[part 11 of 22: package /Cluster]
AUTOSAR XML (schema 4-3-0)
package /Cluster  (continued)
  can cluster E3V_K2CANFD: baudrate=500000, protocol-name=CAN, protocol-version=2.0, bus-off-recovery={bor-counter-l-1-to-l-2=1, bor-time-l-1=0.05, bor-time-l-2=0.2}, can-fd-baudrate=500000  (continued)
    can physical channel CHNL: comm-connectors=CN_E3V_K2CANFD  (continued)
      frame TSG_FT_01_XIX_E3V_K2CANFD: id 0x3D0, to SAM, frame-length=8, can-addressing-mode=STANDARD, can-frame-rx-behavior=CAN-FD, can-frame-tx-behavior=CAN-FD
        pdu TSG_FT_01_XIX_E3V_K2CANFD: length=8, minimum-delay=0.02, transmission-mode-true-timing={cyclic-timing={time-offset=0.0, time-period=0.1}, event-controlled-timing={number-of-repetitions=0, repetition-period=0.0}}, unused-bit-pattern=0  # ab MQB 7.05
          signal FT_Tuer_geoeffnet_XIX_TSG_FT_01_XIX_E3V_K2CANFD: start 0, 1 bit, little-endian, data-type-policy=OVERRIDE, i-signal-type=PRIMITIVE, init-value=0, base-type=BT_FT_Tuer_geoeffnet, compu {0=Cx0_geschlossen (CM_FT_Tuer_geoeffnet_Cx0_geschlossen), 1=Cx1_Tuer_offen (CM_FT_Tuer_geoeffnet_Cx1_Tuer_offen)}, range raw 0..1, transfer-property=TRIGGERED-ON-CHANGE-WITHOUT-REPETITION, to SAM(timeout 1 s)  # Zeigt eine geöffnete Tür an
          signal FT_verriegelt_XIX_TSG_FT_01_XIX_E3V_K2CANFD: start 1, 1 bit, little-endian, data-type-policy=OVERRIDE, i-signal-type=PRIMITIVE, init-value=0, base-type=BT_FT_verriegelt, compu {0=Cx0_Init (CM_FT_verriegelt_Cx0_Init), 1=Cx1_verriegelt (CM_FT_verriegelt_Cx1_verriegelt)}, range raw 0..1, transfer-property=TRIGGERED-ON-CHANGE-WITHOUT-REPETITION  # Zeigt eine verriegelte Tür an ( Status wird erst nach vollständiger Schlossansteuerung ausgegeben (<=1,5sek))
          signal FT_gesafet_XIX_TSG_FT_01_XIX_E3V_K2CANFD: start 2, 1 bit, little-endian, data-type-policy=OVERRIDE, i-signal-type=PRIMITIVE, init-value=0, base-type=BT_FT_gesafet, compu {0=Cx0_Init (CM_FT_gesafet_Cx0_Init), 1=Cx1_gesafet (CM_FT_gesafet_Cx1_gesafet)}, range raw 0..1, transfer-property=TRIGGERED-ON-CHANGE-WITHOUT-REPETITION  # Im Zustand Safe wird auch das Signal FT_verriegelt = 1 gesendet
          signal FT_Schluesselschalter_auf_XIX_TSG_FT_01_XIX_E3V_K2CANFD: start 3, 1 bit, little-endian, data-type-policy=OVERRIDE, i-signal-type=PRIMITIVE, init-value=0, base-type=BT_FT_Schluesselschalter_auf, compu {0=Cx0_Init (CM_FT_Schluesselschalter_auf_Cx0_Init), 1=Cx1_Schluesselschalter_auf_betaetigt (CM_FT_Schluesselschalter_auf_Cx1_Schluesselschalter_auf_betaetigt)}, range raw 0..1, transfer-property=TRIGGERED-ON-CHANGE-WITHOUT-REPETITION  # Schlüsselschalter Richtung auf betätigt
          signal FT_Schluesselschalter_zu_XIX_TSG_FT_01_XIX_E3V_K2CANFD: start 4, 1 bit, little-endian, data-type-policy=OVERRIDE, i-signal-type=PRIMITIVE, init-value=0, base-type=BT_FT_Schluesselschalter_zu, compu {1=Cx1_Schluesselschalter_zu_betaetigt (CM_FT_Schluesselschalter_zu_Cx1_Schluesselschalter_zu_betaetigt) (Schluesselschalter zu betaetigt)}, range raw 1, transfer-property=TRIGGERED-ON-CHANGE-WITHOUT-REPETITION
          signal FT_Unlock_Taster_XIX_TSG_FT_01_XIX_E3V_K2CANFD: start 5, 1 bit, little-endian, data-type-policy=OVERRIDE, i-signal-type=PRIMITIVE, init-value=0, base-type=BT_FT_Unlock_Taster, compu {0=Cx0_Init (CM_FT_Unlock_Taster_Cx0_Init), 1=Cx1_Unlock_Taster_betaetigt (CM_FT_Unlock_Taster_Cx1_Unlock_Taster_betaetigt)}, range raw 0..1, transfer-property=TRIGGERED-ON-CHANGE-WITHOUT-REPETITION  # Entriegelungstaster betätigt
          signal FT_Lock_Taster_XIX_TSG_FT_01_XIX_E3V_K2CANFD: start 6, 1 bit, little-endian, data-type-policy=OVERRIDE, i-signal-type=PRIMITIVE, init-value=0, base-type=BT_FT_Lock_Taster, compu {0=Cx0_Init (CM_FT_Lock_Taster_Cx0_Init), 1=Cx1_Lock_Taster_betaetigt (CM_FT_Lock_Taster_Cx1_Lock_Taster_betaetigt)}, range raw 0..1, transfer-property=TRIGGERED-ON-CHANGE-WITHOUT-REPETITION  # Verriegelungstaster betätigt
          signal FT_Sperrklinke_XIX_TSG_FT_01_XIX_E3V_K2CANFD: start 7, 1 bit, little-endian, data-type-policy=OVERRIDE, i-signal-type=PRIMITIVE, init-value=0, base-type=BT_FT_Sperrklinke, compu {0=Cx0_Schloss_in_Vorraste_und_Hauptraste (CM_FT_Sperrklinke_Cx0_Schloss_in_Vorraste_und_Hauptraste), 1=Cx1_Tuer_auf_oder_Tuer_Position_zwischen_Vor_und_Hauptraste (CM_FT_Sperrklinke_Cx1_Tuer_auf_oder_Tuer_Position_zwischen_Vor_und_Hauptraste)}, range raw 0..1, transfer-property=TRIGGERED-ON-CHANGE-WITHOUT-REPETITION  # Vorraste für Schloß zwischen Vor- und Hauptraste Signal kurz auf 1, danach wieder auf 0 wenn Tür in Hauptraste (Tür ist sicher zu wenn Sperrklinke und Türkontakt auf 0 sind)
          signal FT_TAG_betaetigt_XIX_TSG_FT_01_XIX_E3V_K2CANFD: start 8, 1 bit, little-endian, data-type-policy=OVERRIDE, i-signal-type=PRIMITIVE, init-value=0, base-type=BT_FT_TAG_betaetigt, compu {0=Cx0_nicht_betaetigt (CM_FT_TAG_betaetigt_Cx0_nicht_betaetigt), 1=Cx1_betaetigt (CM_FT_TAG_betaetigt_Cx1_betaetigt)}, range raw 0..1, transfer-property=TRIGGERED-ON-CHANGE-WITHOUT-REPETITION  # Türaussengriff wird nicht im MLB-B8 verwendet
          signal FT_TIG_betaetigt_XIX_TSG_FT_01_XIX_E3V_K2CANFD: start 9, 1 bit, little-endian, data-type-policy=OVERRIDE, i-signal-type=PRIMITIVE, init-value=0, base-type=BT_FT_TIG_betaetigt, compu {0=Cx0_nicht_betaetigt (CM_FT_TIG_betaetigt_Cx0_nicht_betaetigt), 1=Cx1_betaetigt (CM_FT_TIG_betaetigt_Cx1_betaetigt)}, range raw 0..1, transfer-property=TRIGGERED-ON-CHANGE-WITHOUT-REPETITION  # Türinnengriff wird nicht im MLB-B8 verwendet
          signal FT_IRUE_Taste_XIX_TSG_FT_01_XIX_E3V_K2CANFD: start 10, 1 bit, little-endian, data-type-policy=OVERRIDE, i-signal-type=PRIMITIVE, init-value=0, base-type=BT_FT_IRUE_Taste, compu {0=Cx0_Init (CM_FT_IRUE_Taste_Cx0_Init), 1=Cx1_IRUE_Taste_betaetigt (CM_FT_IRUE_Taste_Cx1_IRUE_Taste_betaetigt)}, range raw 0..1, transfer-property=TRIGGERED-ON-CHANGE-WITHOUT-REPETITION  # Betätigung IRUE-Taster (Innenraumüberwachung) MQB: Bei Verbau eines einzelnen Taster zur Deaktivierung von IRUE und NGS wird dieses Signal als Deaktivierungsanforderung beider DWA-Alarmquellen gesendet.
          signal FT_HD_Taste_XIX_TSG_FT_01_XIX_E3V_K2CANFD: start 11, 1 bit, little-endian, data-type-policy=OVERRIDE, i-signal-type=PRIMITIVE, init-value=0, base-type=BT_FT_HD_Taste, compu {0=Cx0_nicht_betaetigt (CM_FT_HD_Taste_Cx0_nicht_betaetigt), 1=Cx1_Heckdeckeltaste_betaetigt (CM_FT_HD_Taste_Cx1_Heckdeckeltaste_betaetigt)}, range raw 0..1, transfer-property=TRIGGERED-ON-CHANGE-WITHOUT-REPETITION  # Taste in der Fahrertür zum Öffnen des Heckschlosses
          signal FT_TD_Taste_Fehler_XIX_TSG_FT_01_XIX_E3V_K2CANFD: start 12, 1 bit, little-endian, data-type-policy=OVERRIDE, i-signal-type=PRIMITIVE, init-value=0, base-type=BT_FT_TD_Taste_Fehler, compu {0=Cx0_iO (CM_FT_TD_Taste_Fehler_Cx0_iO), 1=Cx1_defekt (CM_FT_TD_Taste_Fehler_Cx1_defekt)}, range raw 0..1, transfer-property=PENDING  # Fehlerstatus des Tankdeckelentriegelungstasters. Wird bei Drucktankkonzepten vom MSG zusammen mit dem Signal FT_TD_Taste ausgewertet, um Tankbereitschaft herzustellen. Der Fehler beschreibt einen hängenden TD_Taster. Ein Kurzschluss oder Leitungsunterbrechung kann nicht diagnostiziert werden.
          signal FT_TD_Taste_XIX_TSG_FT_01_XIX_E3V_K2CANFD: start 13, 1 bit, little-endian, data-type-policy=OVERRIDE, i-signal-type=PRIMITIVE, init-value=0, base-type=BT_FT_TD_Taste, compu {0=Cx0_Init (CM_FT_TD_Taste_Cx0_Init), 1=Cx1_Tankdeckel_Taster_betaetigt (CM_FT_TD_Taste_Cx1_Tankdeckel_Taster_betaetigt)}, range raw 0..1, transfer-property=TRIGGERED-ON-CHANGE-WITHOUT-REPETITION  # Tankdeckelentriegelungs-Taste betätigt
          signal SSR_Temp_Freigabe_XIX_TSG_FT_01_XIX_E3V_K2CANFD: start 14, 1 bit, little-endian, data-type-policy=OVERRIDE, i-signal-type=PRIMITIVE, init-value=0, base-type=BT_SSR_Temp_Freigabe, compu {0=Cx0_SSR_Deaktiviert (CM_SSR_Temp_Freigabe_Cx0_SSR_Deaktiviert), 1=Cx1_SSR_Freigegeben (CM_SSR_Temp_Freigabe_Cx1_SSR_Freigegeben)}, range raw 0..1, transfer-property=PENDING  # Freigabe des Seitenscheibenrollos. Bit wird für die Deaktivierung des SSR bei Innenraumtemperaturen kleiner -10 Grad verwendet.
          signal FT_Sp_Heizung_Anf_XIX_TSG_FT_01_XIX_E3V_K2CANFD: start 15, 1 bit, little-endian, data-type-policy=OVERRIDE, i-signal-type=PRIMITIVE, init-value=0, base-type=BT_FT_Sp_Heizung_Anf, compu {phys=raw*100 for raw 0..1; unit Unit_PerCent}, range phys 0..100 Unit_PerCent, raw 0..1, unit=Unit_PerCent, transfer-property=PENDING  # Kundenanforderung der Außenspiegelheizung Fahrertür
          signal FT_HD_Taste_2_XIX_TSG_FT_01_XIX_E3V_K2CANFD: start 16, 1 bit, little-endian, data-type-policy=OVERRIDE, i-signal-type=PRIMITIVE, init-value=0, base-type=BT_FT_HD_Taste_2, compu {0=Cx0_Taste_nicht_gedrueckt (CM_FT_HD_Taste_2_Cx0_Taste_nicht_gedrueckt), 1=Cx1_Taste_gedrueckt (CM_FT_HD_Taste_2_Cx1_Taste_gedrueckt)}, range raw 0..1, transfer-property=TRIGGERED-ON-CHANGE-WITHOUT-REPETITION  # 2. HD-Taste im Bedienfeld Funktion: Heckdeckel schließen
          signal FT_Lock_Unlock_Taster_XIX_TSG_FT_01_XIX_E3V_K2CANFD: start 17, 1 bit, little-endian, data-type-policy=OVERRIDE, i-signal-type=PRIMITIVE, init-value=0, base-type=BT_FT_Lock_Unlock_Taster, compu {0=Cx0_nicht_betaetigt (CM_FT_Lock_Unlock_Taster_Cx0_nicht_betaetigt), 1=Cx1_betaetigt (CM_FT_Lock_Unlock_Taster_Cx1_betaetigt)}, range raw 0..1, transfer-property=TRIGGERED-ON-CHANGE-WITHOUT-REPETITION  # ZV Funktion Lock Unlock mit Toggle-Logik
          signal FT_TSG_hinten_verbaut_XIX_TSG_FT_01_XIX_E3V_K2CANFD: start 18, 1 bit, little-endian, data-type-policy=OVERRIDE, i-signal-type=PRIMITIVE, init-value=0, base-type=BT_FT_TSG_hinten_verbaut, compu {0=Cx0_nicht_verbaut (CM_FT_TSG_hinten_verbaut_Cx0_nicht_verbaut) (nicht verbaut), 1=Cx1_verbaut (CM_FT_TSG_hinten_verbaut_Cx1_verbaut)}, range raw 0..1, transfer-property=TRIGGERED-ON-CHANGE-WITHOUT-REPETITION
          signal FT_Sp_Blk_def_XIX_TSG_FT_01_XIX_E3V_K2CANFD: start 19, 1 bit, little-endian, data-type-policy=OVERRIDE, i-signal-type=PRIMITIVE, init-value=0, base-type=BT_FT_Sp_Blk_def, compu {0=Cx0_iO (CM_FT_Sp_Blk_def_Cx0_iO), 1=Cx1_defekt (CM_FT_Sp_Blk_def_Cx1_defekt)}, range raw 0..1, transfer-property=TRIGGERED-ON-CHANGE-WITHOUT-REPETITION, to SAM(timeout 1 s)  # Blinker am Spiegel defekt
          signal FT_FH_S_ManHoch_XIX_TSG_FT_01_XIX_E3V_K2CANFD: start 20, 1 bit, little-endian, data-type-policy=OVERRIDE, i-signal-type=PRIMITIVE, init-value=0, base-type=BT_FT_FH_S_ManHoch, compu {0=Cx0_Init (CM_FT_FH_S_ManHoch_Cx0_Init), 1=Cx1_FH_Schalter_man_hoch_betaetigt (CM_FT_FH_S_ManHoch_Cx1_FH_Schalter_man_hoch_betaetigt)}, range raw 0..1, transfer-property=TRIGGERED-ON-CHANGE-WITHOUT-REPETITION  # FH Schalter manuell hoch gedrückt
          signal FT_FH_S_AutoHoch_XIX_TSG_FT_01_XIX_E3V_K2CANFD: start 21, 1 bit, little-endian, data-type-policy=OVERRIDE, i-signal-type=PRIMITIVE, init-value=0, base-type=BT_FT_FH_S_AutoHoch, compu {0=Cx0_Init (CM_FT_FH_S_AutoHoch_Cx0_Init), 1=Cx1_FH_Schalter_auto_hoch_betaetigt (CM_FT_FH_S_AutoHoch_Cx1_FH_Schalter_auto_hoch_betaetigt)}, range raw 0..1, transfer-property=TRIGGERED-ON-CHANGE-WITHOUT-REPETITION  # FH Schalter automatisch hoch gedrückt
          signal FT_FH_S_ManTief_XIX_TSG_FT_01_XIX_E3V_K2CANFD: start 22, 1 bit, little-endian, data-type-policy=OVERRIDE, i-signal-type=PRIMITIVE, init-value=0, base-type=BT_FT_FH_S_ManTief, compu {0=Cx0_Init (CM_FT_FH_S_ManTief_Cx0_Init), 1=Cx1_FH_Schalter_man_tief_betaetigt (CM_FT_FH_S_ManTief_Cx1_FH_Schalter_man_tief_betaetigt)}, range raw 0..1, transfer-property=TRIGGERED-ON-CHANGE-WITHOUT-REPETITION  # FH Schalter manuell tief gedrückt
          signal FT_FH_S_AutoTief_XIX_TSG_FT_01_XIX_E3V_K2CANFD: start 23, 1 bit, little-endian, data-type-policy=OVERRIDE, i-signal-type=PRIMITIVE, init-value=0, base-type=BT_FT_FH_S_AutoTief, compu {0=Cx0_Init (CM_FT_FH_S_AutoTief_Cx0_Init), 1=Cx1_FH_Schalter_auto_tief_betaetigt (CM_FT_FH_S_AutoTief_Cx1_FH_Schalter_auto_tief_betaetigt)}, range raw 0..1, transfer-property=TRIGGERED-ON-CHANGE-WITHOUT-REPETITION  # FH Schalter automatisch tief gedrückt
          signal FT_FH_Oeffnung_XIX_TSG_FT_01_XIX_E3V_K2CANFD: start 24, 8 bit, little-endian, data-type-policy=OVERRIDE, i-signal-type=PRIMITIVE, init-value=0, base-type=BT_FT_FH_Oeffnung, compu {phys=raw*0.5 for raw 0..200; unit Unit_PerCent}, range phys 0..100 Unit_PerCent, raw 0..200, unit=Unit_PerCent, transfer-property=TRIGGERED-ON-CHANGE-WITHOUT-REPETITION  # Gibt den Fensteröffnungswert in % an.
          signal FT_FH_Bew_hoch_XIX_TSG_FT_01_XIX_E3V_K2CANFD: start 32, 1 bit, little-endian, data-type-policy=OVERRIDE, i-signal-type=PRIMITIVE, init-value=0, base-type=BT_FT_FH_Bew_hoch, compu {0=Cx0_Init (CM_FT_FH_Bew_hoch_Cx0_Init), 1=Cx1_FH_in_Bewegung_hoch (CM_FT_FH_Bew_hoch_Cx1_FH_in_Bewegung_hoch)}, range raw 0..1, transfer-property=TRIGGERED-ON-CHANGE-WITHOUT-REPETITION, to SAM(timeout 1 s)  # Fensterheber in Bewegung Richtung hoch
          signal FT_FH_Bew_tief_XIX_TSG_FT_01_XIX_E3V_K2CANFD: start 33, 1 bit, little-endian, data-type-policy=OVERRIDE, i-signal-type=PRIMITIVE, init-value=0, base-type=BT_FT_FH_Bew_tief, compu {0=Cx0_Init (CM_FT_FH_Bew_tief_Cx0_Init), 1=Cx1_FH_in_Bewegung_tief (CM_FT_FH_Bew_tief_Cx1_FH_in_Bewegung_tief)}, range raw 0..1, transfer-property=TRIGGERED-ON-CHANGE-WITHOUT-REPETITION, to SAM(timeout 1 s)  # Fensterheber in Bewegung Richtung tief
          signal FT_FH_Fang_XIX_TSG_FT_01_XIX_E3V_K2CANFD: start 34, 1 bit, little-endian, data-type-policy=OVERRIDE, i-signal-type=PRIMITIVE, init-value=0, base-type=BT_FT_FH_Fang, compu {0=Cx0_ausserhalb_Fangbereich (CM_FT_FH_Fang_Cx0_ausserhalb_Fangbereich), 1=Cx1_innerhalb_Fangbereich (CM_FT_FH_Fang_Cx1_innerhalb_Fangbereich)}, range raw 0..1, transfer-property=TRIGGERED-ON-CHANGE-WITHOUT-REPETITION  # Fangbereich ist 4mm von oberer Lippendichtung
          signal FT_FH_Block_XIX_TSG_FT_01_XIX_E3V_K2CANFD: start 35, 1 bit, little-endian, data-type-policy=OVERRIDE, i-signal-type=PRIMITIVE, init-value=0, base-type=BT_FT_FH_Block, compu {0=Cx0_Init (CM_FT_FH_Block_Cx0_Init), 1=Cx1_Fenster_Block (CM_FT_FH_Block_Cx1_Fenster_Block)}, range raw 0..1, transfer-property=TRIGGERED-ON-CHANGE-WITHOUT-REPETITION  # Fensterscheibe befindet sich im mechanischen Block (oben oder unten)
          signal FT_FH_Thermo_XIX_TSG_FT_01_XIX_E3V_K2CANFD: start 36, 1 bit, little-endian, data-type-policy=OVERRIDE, i-signal-type=PRIMITIVE, init-value=0, base-type=BT_FT_FH_Thermo, compu {0=Cx0_Init (CM_FT_FH_Thermo_Cx0_Init), 1=Cx1_Thermoschutz_aktiv (CM_FT_FH_Thermo_Cx1_Thermoschutz_aktiv)}, range raw 0..1, transfer-property=TRIGGERED-ON-CHANGE-WITHOUT-REPETITION  # gibt an ob Fensterheber im Thermoschutz ist
          signal FT_UEKB_aktiviert_XIX_TSG_FT_01_XIX_E3V_K2CANFD: start 37, 1 bit, little-endian, data-type-policy=OVERRIDE, i-signal-type=PRIMITIVE, init-value=0, base-type=BT_FT_UEKB_aktiviert, compu {0=Cx0_Init (CM_FT_UEKB_aktiviert_Cx0_Init), 1=Cx1_UEKB_aktiv (CM_FT_UEKB_aktiviert_Cx1_UEKB_aktiv)}, range raw 0..1, transfer-property=TRIGGERED-ON-CHANGE-WITHOUT-REPETITION  # Überschutzbegrenzungskraft bei Reversieren
          signal ASW_HMI_defekt_XIX_TSG_FT_01_XIX_E3V_K2CANFD: start 38, 1 bit, little-endian, data-type-policy=OVERRIDE, i-signal-type=PRIMITIVE, init-value=0, base-type=BT_ASW_HMI_defekt, compu {0=Cx0_iO (CM_ASW_HMI_defekt_Cx0_iO), 1=Cx1_defekt (CM_ASW_HMI_defekt_Cx1_defekt)}, range raw 0..1, transfer-property=PENDING  # HMI Status der Funktion AusstiegsWarnung (ASW). HMI wird durch das TSG angesteuert.
          signal FT_FH_normiert_XIX_TSG_FT_01_XIX_E3V_K2CANFD: start 39, 1 bit, little-endian, data-type-policy=OVERRIDE, i-signal-type=PRIMITIVE, init-value=0, base-type=BT_FT_FH_normiert, compu {0=Cx0_Init (CM_FT_FH_normiert_Cx0_Init), 1=Cx1_Fenster_normiert (CM_FT_FH_normiert_Cx1_Fenster_normiert)}, range raw 0..1, transfer-property=TRIGGERED-ON-CHANGE-WITHOUT-REPETITION  # Die Position der Fensterheberscheibe ist bekannt
          signal FT_Schliesstaster_XIX_TSG_FT_01_XIX_E3V_K2CANFD: start 40, 1 bit, little-endian, data-type-policy=OVERRIDE, i-signal-type=PRIMITIVE, init-value=0, base-type=BT_FT_Schliesstaster, compu {1=Cx1_Schliesstaster_betaetigt (CM_FT_Schliesstaster_Cx1_Schliesstaster_betaetigt)}, range raw 1, transfer-property=TRIGGERED-ON-CHANGE-WITHOUT-REPETITION  # Vorhalt
          signal FT_Zuziehhilfe_aktiv_XIX_TSG_FT_01_XIX_E3V_K2CANFD: start 41, 1 bit, little-endian, data-type-policy=OVERRIDE, i-signal-type=PRIMITIVE, init-value=0, base-type=BT_FT_Zuziehhilfe_aktiv, compu {0=Cx0_Init (CM_FT_Zuziehhilfe_aktiv_Cx0_Init), 1=Cx1_Zuziehilfe_aktiv (CM_FT_Zuziehhilfe_aktiv_Cx1_Zuziehilfe_aktiv)}, range raw 0..1, transfer-property=TRIGGERED-ON-CHANGE-WITHOUT-REPETITION  # Zuziehhilfe aktiv
          signal FT_SP_ausgerastet_XIX_TSG_FT_01_XIX_E3V_K2CANFD: start 42, 1 bit, little-endian, data-type-policy=OVERRIDE, i-signal-type=PRIMITIVE, init-value=0, base-type=BT_FT_SP_ausgerastet, compu {0=Cx0_Init (CM_FT_SP_ausgerastet_Cx0_Init), 1=Cx1_Spiegel_ausgerastet (CM_FT_SP_ausgerastet_Cx1_Spiegel_ausgerastet)}, range raw 0..1, transfer-property=TRIGGERED-ON-CHANGE-WITHOUT-REPETITION  # Spiegel ausgerastet
          signal FT_SP_lr_aktiv_XIX_TSG_FT_01_XIX_E3V_K2CANFD: start 43, 1 bit, little-endian, data-type-policy=OVERRIDE, i-signal-type=PRIMITIVE, init-value=0, base-type=BT_FT_SP_lr_aktiv, compu {0=Cx0_Init (CM_FT_SP_lr_aktiv_Cx0_Init), 1=Cx1_Spiegel_xAchse_aktiv (CM_FT_SP_lr_aktiv_Cx1_Spiegel_xAchse_aktiv)}, range raw 0..1, transfer-property=TRIGGERED-ON-CHANGE-WITHOUT-REPETITION  # Spiegelverstellung in Richtung links/rechts aktiv
          signal FT_SP_ht_aktiv_XIX_TSG_FT_01_XIX_E3V_K2CANFD: start 44, 1 bit, little-endian, data-type-policy=OVERRIDE, i-signal-type=PRIMITIVE, init-value=0, base-type=BT_FT_SP_ht_aktiv, compu {0=Cx0_Init (CM_FT_SP_ht_aktiv_Cx0_Init), 1=Cx1_Spiegel_yAchse_aktiv (CM_FT_SP_ht_aktiv_Cx1_Spiegel_yAchse_aktiv)}, range raw 0..1, transfer-property=TRIGGERED-ON-CHANGE-WITHOUT-REPETITION  # Spiegelverstellung in Richtung hoch/tief aktiv
          signal ASW_wakeup_XIX_TSG_FT_01_XIX_E3V_K2CANFD: start 45, 1 bit, little-endian, data-type-policy=OVERRIDE, i-signal-type=PRIMITIVE, init-value=0, base-type=BT_ASW_wakeup, compu {0=Cx0_Sleep (CM_ASW_wakeup_Cx0_Sleep), 1=Cx1_Wakeup (CM_ASW_wakeup_Cx1_Wakeup)}, range raw 0..1, transfer-property=TRIGGERED-ON-CHANGE-WITHOUT-REPETITION  # Trigger Start Nachlaufzeit t_1 für die Funktion Ausstieswarnung (ASW)
          signal FT_Oben_Block_erw_XIX_TSG_FT_01_XIX_E3V_K2CANFD: start 46, 1 bit, little-endian, data-type-policy=OVERRIDE, i-signal-type=PRIMITIVE, init-value=0, base-type=BT_FT_Oben_Block_erw, compu {0=Cx0_Fensterheber_nicht_in_Blockerwar (CM_FT_Oben_Block_erw_Cx0_Fensterheber_nicht_in_Blockerwar), 1=Cx1_Fensterheber_in_Blockerwartung_o (CM_FT_Oben_Block_erw_Cx1_Fensterheber_in_Blockerwartung_o)}, range raw 0..1, transfer-property=TRIGGERED-ON-CHANGE-WITHOUT-REPETITION, to SAM(timeout 1 s)  # Fensterheber in Blockerwartung oben
          signal FT_Unten_Block_erw_XIX_TSG_FT_01_XIX_E3V_K2CANFD: start 47, 1 bit, little-endian, data-type-policy=OVERRIDE, i-signal-type=PRIMITIVE, init-value=0, base-type=BT_FT_Unten_Block_erw, compu {0=Cx0_Fensterheber_nicht_in_Blockerwar (CM_FT_Unten_Block_erw_Cx0_Fensterheber_nicht_in_Blockerwar), 1=Cx1_Fensterheber_in_Blockerwartung_u (CM_FT_Unten_Block_erw_Cx1_Fensterheber_in_Blockerwartung_u)}, range raw 0..1, transfer-property=TRIGGERED-ON-CHANGE-WITHOUT-REPETITION, to SAM(timeout 1 s)  # Fensterheber in Blockerwartung unten
          signal FT_Kisi_li_aktiv_XIX_TSG_FT_01_XIX_E3V_K2CANFD: start 48, 1 bit, little-endian, data-type-policy=OVERRIDE, i-signal-type=PRIMITIVE, init-value=0, base-type=BT_FT_Kisi_li_aktiv, compu {0=Cx0_inaktiv (CM_FT_Kisi_li_aktiv_Cx0_inaktiv), 1=Cx1_aktiv (CM_FT_Kisi_li_aktiv_Cx1_aktiv)}, range raw 0..1, transfer-property=TRIGGERED-ON-CHANGE-WITHOUT-REPETITION, to SAM(timeout 1 s)  # Aktivierungsstatus der Kindersicherung links
          signal FT_Kisi_re_aktiv_XIX_TSG_FT_01_XIX_E3V_K2CANFD: start 49, 1 bit, little-endian, data-type-policy=OVERRIDE, i-signal-type=PRIMITIVE, init-value=0, base-type=BT_FT_Kisi_re_aktiv, compu {0=Cx0_inaktiv (CM_FT_Kisi_re_aktiv_Cx0_inaktiv), 1=Cx1_aktiv (CM_FT_Kisi_re_aktiv_Cx1_aktiv)}, range raw 0..1, transfer-property=TRIGGERED-ON-CHANGE-WITHOUT-REPETITION, to SAM(timeout 1 s)  # Aktivierungsstatus der Kindersicherung rechts
          signal FT_Kisi_Taster_li_XIX_TSG_FT_01_XIX_E3V_K2CANFD: start 50, 1 bit, little-endian, data-type-policy=OVERRIDE, i-signal-type=PRIMITIVE, init-value=0, base-type=BT_FT_Kisi_Taster_li, compu {0=Cx0_nicht_betaetigt (CM_FT_Kisi_Taster_li_Cx0_nicht_betaetigt), 1=Cx1_betaetigt (CM_FT_Kisi_Taster_li_Cx1_betaetigt)}, range raw 0..1, transfer-property=TRIGGERED-ON-CHANGE-WITHOUT-REPETITION, to SAM(timeout 1 s)  # Linker Kisi Taster betaetigt
          signal FT_Kisi_Taster_re_XIX_TSG_FT_01_XIX_E3V_K2CANFD: start 51, 1 bit, little-endian, data-type-policy=OVERRIDE, i-signal-type=PRIMITIVE, init-value=0, base-type=BT_FT_Kisi_Taster_re, compu {0=Cx0_nicht_betaetigt (CM_FT_Kisi_Taster_re_Cx0_nicht_betaetigt), 1=Cx1_betaetigt (CM_FT_Kisi_Taster_re_Cx1_betaetigt)}, range raw 0..1, transfer-property=TRIGGERED-ON-CHANGE-WITHOUT-REPETITION, to SAM(timeout 1 s)  # Rechter Kisi Taster betaetigt
          signal FT_BFS_Fond_Freigabe_XIX_TSG_FT_01_XIX_E3V_K2CANFD: start 52, 1 bit, little-endian, data-type-policy=OVERRIDE, i-signal-type=PRIMITIVE, init-value=0, base-type=BT_FT_BFS_Fond_Freigabe, compu {0=Cx0_Init (CM_FT_BFS_Fond_Freigabe_Cx0_Init), 1=Cx1_Freigabe_fuer_Fondbedienung_BFS (CM_FT_BFS_Fond_Freigabe_Cx1_Freigabe_fuer_Fondbedienung_BFS)}, range raw 0..1, transfer-property=TRIGGERED-ON-CHANGE-WITHOUT-REPETITION  # Freigabe für Fondverstellung
          signal FT_Kisi_Fehler_XIX_TSG_FT_01_XIX_E3V_K2CANFD: start 53, 1 bit, little-endian, data-type-policy=OVERRIDE, i-signal-type=PRIMITIVE, init-value=0, base-type=BT_FT_Kisi_Fehler, invalid-value=Invalid_FT_Kisi_Fehler_XIX_TSG_FT_01_XIX_E3V_K2CANFD:1, compu {0=Cx0_kein_Fehler (CM_FT_Kisi_Fehler_Cx0_kein_Fehler), 1=Cx1_Fehler (CM_FT_Kisi_Fehler_Cx1_Fehler)}, range raw 0..1, transfer-property=TRIGGERED-ON-CHANGE-WITHOUT-REPETITION  # Fehlerstatus Kindersicherungsfunktion
          signal FT_Daemmglas_XIX_TSG_FT_01_XIX_E3V_K2CANFD: start 54, 1 bit, little-endian, data-type-policy=OVERRIDE, i-signal-type=PRIMITIVE, init-value=0, base-type=BT_FT_Daemmglas, compu {0=Cx0_Normalglas_verbaut (CM_FT_Daemmglas_Cx0_Normalglas_verbaut), 1=Cx1_Daemmglas_verbaut (CM_FT_Daemmglas_Cx1_Daemmglas_verbaut)}, range raw 0..1, transfer-property=TRIGGERED-ON-CHANGE-WITHOUT-REPETITION  # Daemmglas verbaut
          signal FT_SP_Heizung_Status_XIX_TSG_FT_01_XIX_E3V_K2CANFD: start 55, 1 bit, little-endian, data-type-policy=OVERRIDE, i-signal-type=PRIMITIVE, init-value=0, base-type=BT_FT_SP_Heizung_Status, compu {0=Cx0_Init (CM_FT_SP_Heizung_Status_Cx0_Init), 1=Cx1_Status_Spiegelheizung_ein (CM_FT_SP_Heizung_Status_Cx1_Status_Spiegelheizung_ein)}, range raw 0..1, transfer-property=TRIGGERED-ON-CHANGE-WITHOUT-REPETITION  # Status der Spiegelheizung
          signal ASW_Warnung_aktiv_FS_XIX_TSG_FT_01_XIX_E3V_K2CANFD: start 56, 1 bit, little-endian, data-type-policy=OVERRIDE, i-signal-type=PRIMITIVE, init-value=0, base-type=BT_ASW_Warnung_aktiv_FS, compu {0=Cx0_nicht_angefordert (CM_ASW_Warnung_aktiv_FS_Cx0_nicht_angefordert), 1=Cx1_angefordert (CM_ASW_Warnung_aktiv_FS_Cx1_angefordert)}, range raw 0..1, transfer-property=TRIGGERED-ON-CHANGE-WITHOUT-REPETITION, to SAM(timeout 1 s)  # Abschaltung der Ambientefunktion Fahrertür bei aktiver ASW Warnung an der Fahrertür
          signal FT_FH_Pos_oben_XIX_TSG_FT_01_XIX_E3V_K2CANFD: start 57, 1 bit, little-endian, data-type-policy=OVERRIDE, i-signal-type=PRIMITIVE, init-value=0, base-type=BT_FT_FH_Pos_oben, compu {1=Cx1_Scheibe_oben_nach_Absenken_auf_Position (CM_FT_FH_Pos_oben_Cx1_Scheibe_oben_nach_Absenken_auf_Position) (Scheibe oben (nach Absenken auf Position))}, range raw 1, transfer-property=TRIGGERED-ON-CHANGE-WITHOUT-REPETITION
          signal FT_Tuerschloss_defekt_XIX_TSG_FT_01_XIX_E3V_K2CANFD: start 58, 1 bit, little-endian, data-type-policy=OVERRIDE, i-signal-type=PRIMITIVE, init-value=0, base-type=BT_FT_Tuerschloss_defekt, compu {0=Cx0_Tuerschloss_funktionsfaehig (CM_FT_Tuerschloss_defekt_Cx0_Tuerschloss_funktionsfaehig), 1=Cx1_Tuerschloss_defekt (CM_FT_Tuerschloss_defekt_Cx1_Tuerschloss_defekt)}, range raw 0..1, transfer-property=PENDING  # Das Fahrertürschloss ist nicht mehr funktionsfähig.
          signal FT_SWA_Taster_XIX_TSG_FT_01_XIX_E3V_K2CANFD: start 59, 1 bit, little-endian, data-type-policy=OVERRIDE, i-signal-type=PRIMITIVE, init-value=0, base-type=BT_FT_SWA_Taster, compu {0=Cx0_Taster_nicht_betaetigt (CM_FT_SWA_Taster_Cx0_Taster_nicht_betaetigt), 1=Cx1_Taster_betaetigt (CM_FT_SWA_Taster_Cx1_Taster_betaetigt)}, range raw 0..1, transfer-property=TRIGGERED-ON-CHANGE-WITHOUT-REPETITION  # SWA/ASW Taster Fahrertür
          signal SWA_HMI_Diagnose_XIX_TSG_FT_01_XIX_E3V_K2CANFD: start 60, 2 bit, little-endian, data-type-policy=OVERRIDE, i-signal-type=PRIMITIVE, init-value=0, base-type=BT_SWA_HMI_Diagnose, compu {0=Cx0_kein_Fehler_erkannt (CM_SWA_HMI_Diagnose_Cx0_kein_Fehler_erkannt), 1=Cx1_Fehler_Taster_erkannt (CM_SWA_HMI_Diagnose_Cx1_Fehler_Taster_erkannt), 2=Cx2_Fehler_LED_erkannt (CM_SWA_HMI_Diagnose_Cx2_Fehler_LED_erkannt), 3=Cx3_Fehler_LED_und_Taster_erkannt (CM_SWA_HMI_Diagnose_Cx3_Fehler_LED_und_Taster_erkannt)}, range raw 0..3, transfer-property=PENDING  # SWA HMI Diagnose beim TSG
          signal FS_Status_eTAG_XIX_TSG_FT_01_XIX_E3V_K2CANFD: start 62, 2 bit, little-endian, data-type-policy=OVERRIDE, i-signal-type=PRIMITIVE, init-value=0, base-type=BT_FS_Status_eTAG, invalid-value=Invalid_FS_Status_eTAG_XIX_TSG_FT_01_XIX_E3V_K2CANFD:3, compu {0=Cx0_Init (CM_FS_Status_eTAG_Cx0_Init), 1=Cx1_Griff_ausgefahren (CM_FS_Status_eTAG_Cx1_Griff_ausgefahren), 2=Cx2_Griff_eingefahren (CM_FS_Status_eTAG_Cx2_Griff_eingefahren), 3=Cx3_Fehler (CM_FS_Status_eTAG_Cx3_Fehler)}, range raw 0..3, transfer-property=TRIGGERED-ON-CHANGE-WITHOUT-REPETITION  # Status des elektrischen Tueraussengriffes Fahrertuer
      frame TSG_FT_02_XIX_E3V_K2CANFD: id 0x3E5, to SAM, frame-length=8, can-addressing-mode=STANDARD, can-frame-rx-behavior=CAN-FD, can-frame-tx-behavior=CAN-FD
        pdu TSG_FT_02_XIX_E3V_K2CANFD_E2E: length=8, minimum-delay=0.02, transmission-mode-true-timing=event-controlled-timing={number-of-repetitions=0, repetition-period=0.0}, unused-bit-pattern=0  # Fuer die Botschaft ist das Cyclic-Timing 0.1 zu verwenden.
          signal TSG_FT_02_CRC_XIX_TSG_FT_02_XIX_E3V_K2CANFD: start 0, 8 bit, little-endian, data-type-policy=OVERRIDE, i-signal-type=PRIMITIVE, base-type=BT_TSG_FT_02_CRC, compu {phys=raw for raw 0..255}, range phys 0..255, raw 0..255, to SAM(timeout 1 s)  # Für MLB: "Berechnung siehe Lastenheft "Kommunikationsabsicherung für FlexRay und CAN"" Ab MQB und MLBevo: "Berechnung siehe Lastenheft "End-to-End Kommunikationsabsicherung"" Endwerte siehe Begleitdokument "S-PDU Kennungsfolgen"
          signal TSG_FT_02_BZ_XIX_TSG_FT_02_XIX_E3V_K2CANFD: start 8, 4 bit, little-endian, data-type-policy=OVERRIDE, i-signal-type=PRIMITIVE, base-type=BT_TSG_FT_02_BZ, compu {phys=raw for raw 0..15}, range phys 0..15, raw 0..15, to SAM(timeout 1 s)  # 4bit Botschaftszaehler, wird mit jeder Sendebotschaft inkrementiert
          signal FT_Tuer_Status_XIX_TSG_FT_02_XIX_E3V_K2CANFD: start 12, 2 bit, little-endian, data-type-policy=OVERRIDE, i-signal-type=PRIMITIVE, init-value=0, base-type=BT_FT_Tuer_Status, invalid-value=Invalid_FT_Tuer_Status_XIX_TSG_FT_02_XIX_E3V_K2CANFD:3, compu {0=Cx0_Init (CM_FT_Tuer_Status_Cx0_Init), 1=Cx1_Tuer_geschlossen (CM_FT_Tuer_Status_Cx1_Tuer_geschlossen), 2=Cx2_Tuer_offen (CM_FT_Tuer_Status_Cx2_Tuer_offen), 3=Cx3_Fehler (CM_FT_Tuer_Status_Cx3_Fehler)}, range raw 0..3  # Tür geöffnet oder Tür geschlossen
          signal FT_Tuer_Status_QBit_XIX_TSG_FT_02_XIX_E3V_K2CANFD: start 14, 1 bit, little-endian, data-type-policy=OVERRIDE, i-signal-type=PRIMITIVE, base-type=BT_FT_Tuer_Status_QBit, compu {0=Cx0_Status_Tuerkontakt_sicher (CM_FT_Tuer_Status_QBit_Cx0_Status_Tuerkontakt_sicher), 1=Cx1_Status_Tuerkontakt_unsicher (CM_FT_Tuer_Status_QBit_Cx1_Status_Tuerkontakt_unsicher)}, range raw 0..1  # Dieses Bit gibt die Zuverlässigkeit des Türkontakts an. Ein auf dieses Bit folgender Fehlereintrag ist mit dem Sender des Bits abzustimmen (gültig ab PPE).
          signal FT_Lock_Taster_02_XIX_TSG_FT_02_XIX_E3V_K2CANFD: start 15, 1 bit, little-endian, data-type-policy=OVERRIDE, i-signal-type=PRIMITIVE, init-value=0, base-type=BT_FT_Lock_Taster_02, compu {0=Cx0_nicht_betaetigt (CM_FT_Lock_Taster_02_Cx0_nicht_betaetigt), 1=Cx1_betaetigt (CM_FT_Lock_Taster_02_Cx1_betaetigt)}, range raw 0..1  # Lock-Taster betätigt
          signal FT_Schluesselschalter_zu_02_XIX_TSG_FT_02_XIX_E3V_K2CANFD: start 16, 1 bit, little-endian, data-type-policy=OVERRIDE, i-signal-type=PRIMITIVE, init-value=0, base-type=BT_FT_Schluesselschalter_zu_02, compu {0=Cx0_nicht_betaetigt (CM_FT_Schluesselschalter_zu_02_Cx0_nicht_betaetigt), 1=Cx1_betaetigt (CM_FT_Schluesselschalter_zu_02_Cx1_betaetigt)}, range raw 0..1  # Schlüsselschalter für Schließen betätigt
          signal FT_BFS_Tuer_Status_XIX_TSG_FT_02_XIX_E3V_K2CANFD: start 17, 2 bit, little-endian, data-type-policy=OVERRIDE, i-signal-type=PRIMITIVE, init-value=0, base-type=BT_FT_BFS_Tuer_Status, invalid-value=Invalid_FT_BFS_Tuer_Status_XIX_TSG_FT_02_XIX_E3V_K2CANFD:3, compu {0=Cx0_Init (CM_FT_BFS_Tuer_Status_Cx0_Init), 1=Cx1_Tuer_geschlossen (CM_FT_BFS_Tuer_Status_Cx1_Tuer_geschlossen), 2=Cx2_Tuer_offen (CM_FT_BFS_Tuer_Status_Cx2_Tuer_offen), 3=Cx3_Fehler (CM_FT_BFS_Tuer_Status_Cx3_Fehler)}, range raw 0..3  # Gesammelte Türstatusbotschaft
          signal FT_HBFS_Tuer_Status_XIX_TSG_FT_02_XIX_E3V_K2CANFD: start 19, 2 bit, little-endian, data-type-policy=OVERRIDE, i-signal-type=PRIMITIVE, init-value=0, base-type=BT_FT_HBFS_Tuer_Status, invalid-value=Invalid_FT_HBFS_Tuer_Status_XIX_TSG_FT_02_XIX_E3V_K2CANFD:3, compu {0=Cx0_Init (CM_FT_HBFS_Tuer_Status_Cx0_Init), 1=Cx1_Tuer_geschlossen (CM_FT_HBFS_Tuer_Status_Cx1_Tuer_geschlossen), 2=Cx2_Tuer_offen (CM_FT_HBFS_Tuer_Status_Cx2_Tuer_offen), 3=Cx3_Fehler (CM_FT_HBFS_Tuer_Status_Cx3_Fehler)}, range raw 0..3  # Türstatus mit Fehler und Initwert
          signal FT_HFS_Tuer_Status_XIX_TSG_FT_02_XIX_E3V_K2CANFD: start 21, 2 bit, little-endian, data-type-policy=OVERRIDE, i-signal-type=PRIMITIVE, init-value=0, base-type=BT_FT_HFS_Tuer_Status, invalid-value=Invalid_FT_HFS_Tuer_Status_XIX_TSG_FT_02_XIX_E3V_K2CANFD:3, compu {0=Cx0_Init (CM_FT_HFS_Tuer_Status_Cx0_Init), 1=Cx1_Tuer_geschlossen (CM_FT_HFS_Tuer_Status_Cx1_Tuer_geschlossen), 2=Cx2_Tuer_offen (CM_FT_HFS_Tuer_Status_Cx2_Tuer_offen), 3=Cx3_Fehler (CM_FT_HFS_Tuer_Status_Cx3_Fehler)}, range raw 0..3  # Türstatus mit Fehler und Initwert
          signal FT_Tueroeffnen_Warnung_XIX_TSG_FT_02_XIX_E3V_K2CANFD: start 23, 1 bit, little-endian, data-type-policy=OVERRIDE, i-signal-type=PRIMITIVE, init-value=0, base-type=BT_FT_Tueroeffnen_Warnung, compu {0=Cx0_Tuerwarnung_nicht_aktiv (CM_FT_Tueroeffnen_Warnung_Cx0_Tuerwarnung_nicht_aktiv), 1=Cx1_Tuerwarnung_aktiv (CM_FT_Tueroeffnen_Warnung_Cx1_Tuerwarnung_aktiv)}, range raw 0..1  # Bit wird gesetzt, wenn Tür während der Fahrt geoeffnet werden soll.
          signal FT_SP_Heizung_ein_XIX_TSG_FT_02_XIX_E3V_K2CANFD: start 24, 1 bit, little-endian, data-type-policy=OVERRIDE, i-signal-type=PRIMITIVE, init-value=0, base-type=BT_FT_SP_Heizung_ein, compu {0=Cx0_Aus (CM_FT_SP_Heizung_ein_Cx0_Aus), 1=Cx1_Ein (CM_FT_SP_Heizung_ein_Cx1_Ein)}, range raw 0..1  # Dieses Signal zeigt die tatsächliche Ansteuerung der Spiegelheizung incl. PWM an. Zudem wird aufgrund des Teilnetzbetriebs das Signal zur Ansteuerung der Beifahrer-Spiegelheizung benutzt.
          signal FT_Kisi_Taster_li_02_XIX_TSG_FT_02_XIX_E3V_K2CANFD: start 25, 1 bit, little-endian, data-type-policy=OVERRIDE, i-signal-type=PRIMITIVE, init-value=0, base-type=BT_FT_Kisi_Taster_li_02, compu {0=Cx0_nicht_betaetigt (CM_FT_Kisi_Taster_li_02_Cx0_nicht_betaetigt), 1=Cx1_betaetigt (CM_FT_Kisi_Taster_li_02_Cx1_betaetigt)}, range raw 0..1, to SAM(timeout 1 s)  # Der Kindersicherungstaster hinten links aktiv.
          signal FT_Kisi_Taster_re_02_XIX_TSG_FT_02_XIX_E3V_K2CANFD: start 26, 1 bit, little-endian, data-type-policy=OVERRIDE, i-signal-type=PRIMITIVE, init-value=0, base-type=BT_FT_Kisi_Taster_re_02, compu {0=Cx0_nicht_betaetigt (CM_FT_Kisi_Taster_re_02_Cx0_nicht_betaetigt), 1=Cx1_betaetigt (CM_FT_Kisi_Taster_re_02_Cx1_betaetigt)}, range raw 0..1, to SAM(timeout 1 s)  # Der Kindersicherungstaster hinten rechts aktiv.
          signal FT_TD_Taste_Status_XIX_TSG_FT_02_XIX_E3V_K2CANFD: start 27, 2 bit, little-endian, data-type-policy=OVERRIDE, i-signal-type=PRIMITIVE, init-value=0, base-type=BT_FT_TD_Taste_Status, compu {0=Cx0_kein_Fehler (CM_FT_TD_Taste_Status_Cx0_kein_Fehler), 1=Cx1_Kurzschluss_nach_Minus (CM_FT_TD_Taste_Status_Cx1_Kurzschluss_nach_Minus), 2=Cx2_Kurzschluss_nach_Plus (CM_FT_TD_Taste_Status_Cx2_Kurzschluss_nach_Plus), 3=Cx3_Leitungsunterbrechung (CM_FT_TD_Taste_Status_Cx3_Leitungsunterbrechung)}, range raw 0..3  # Status Taste für Tankdeckel
          signal FT_TCR_Mode_aktiv_XIX_TSG_FT_02_XIX_E3V_K2CANFD: start 29, 1 bit, little-endian, data-type-policy=OVERRIDE, i-signal-type=PRIMITIVE, init-value=0, base-type=BT_FT_TCR_Mode_aktiv, compu {0=Cx0_TCR_Mode_deaktiv (CM_FT_TCR_Mode_aktiv_Cx0_TCR_Mode_deaktiv), 1=Cx1_TCR_Mode_aktiv (CM_FT_TCR_Mode_aktiv_Cx1_TCR_Mode_aktiv)}, range raw 0..1  # Signal zeigt eine aktive mechanische Redundanz am Türschloss an.
          signal TBF_FS_Touch_Event_XIX_TSG_FT_02_XIX_E3V_K2CANFD: start 30, 4 bit, little-endian, data-type-policy=OVERRIDE, i-signal-type=PRIMITIVE, init-value=0, base-type=BT_TBF_FS_Touch_Event, compu {0=Cx0_nicht_betaetigt (CM_TBF_FS_Touch_Event_Cx0_nicht_betaetigt), 1=Cx1_Tippen (CM_TBF_FS_Touch_Event_Cx1_Tippen), 2=Cx2_Wischen (CM_TBF_FS_Touch_Event_Cx2_Wischen), 3=Cx3_Geste (CM_TBF_FS_Touch_Event_Cx3_Geste), 4=Cx4_Doppeltippen (CM_TBF_FS_Touch_Event_Cx4_Doppeltippen), 5=Cx5_Longpress_1 (CM_TBF_FS_Touch_Event_Cx5_Longpress_1), 6=Cx6_Longpress_2 (CM_TBF_FS_Touch_Event_Cx6_Longpress_2), 7=Cx7_reserviert (CM_TBF_FS_Touch_Event_Cx7_reserviert), 8=Cx8_reserviert (CM_TBF_FS_Touch_Event_Cx8_reserviert), 9=Cx9_reserviert (CM_TBF_FS_Touch_Event_Cx9_reserviert), 10=Cxa_reserviert (CM_TBF_FS_Touch_Event_Cxa_reserviert), 11=Cxb_reserviert (CM_TBF_FS_Touch_Event_Cxb_reserviert), 12=Cxc_reserviert (CM_TBF_FS_Touch_Event_Cxc_reserviert), 13=Cxd_reserviert (CM_TBF_FS_Touch_Event_Cxd_reserviert), 14=Cxe_reserviert (CM_TBF_FS_Touch_Event_Cxe_reserviert), 15=Cxf_reserviert (CM_TBF_FS_Touch_Event_Cxf_reserviert)}, range raw 0..15  # Touch_Events für Informationen einer Funktionsauslösung auf dem TBF, welche dann für bspw. ein akustisches Signal zentral umgesetzt werden können.
          signal FT_KiSi_Status_Soll_HBFS_XIX_TSG_FT_02_XIX_E3V_K2CANFD: start 34, 1 bit, little-endian, data-type-policy=OVERRIDE, i-signal-type=PRIMITIVE, base-type=BT_FT_KiSi_Status_Soll_HBFS, compu {0=Cx0_inaktiv (CM_FT_KiSi_Status_Soll_HBFS_Cx0_inaktiv), 1=Cx1_aktiv (CM_FT_KiSi_Status_Soll_HBFS_Cx1_aktiv)}, range raw 0..1  # Soll KiSi Status HBFS
          signal FT_KiSi_Status_Soll_HFS_XIX_TSG_FT_02_XIX_E3V_K2CANFD: start 35, 1 bit, little-endian, data-type-policy=OVERRIDE, i-signal-type=PRIMITIVE, base-type=BT_FT_KiSi_Status_Soll_HFS, compu {0=Cx0_inaktiv (CM_FT_KiSi_Status_Soll_HFS_Cx0_inaktiv), 1=Cx1_aktiv (CM_FT_KiSi_Status_Soll_HFS_Cx1_aktiv)}, range raw 0..1  # Soll Status der KiSi HFS
          signal FS_Push_Tuergriff_XIX_TSG_FT_02_XIX_E3V_K2CANFD: start 36, 1 bit, little-endian, data-type-policy=OVERRIDE, i-signal-type=PRIMITIVE, init-value=0, base-type=BT_FS_Push_Tuergriff, compu {0=Cx0_nicht_erkannt (CM_FS_Push_Tuergriff_Cx0_nicht_erkannt), 1=Cx1_erkannt (CM_FS_Push_Tuergriff_Cx1_erkannt)}, range raw 0..1  # Push zum Ausfahren der Flush-Tuergriffe
          signal TSG_FS_Spiegel_angeklappt_XIX_TSG_FT_02_XIX_E3V_K2CANFD: start 37, 1 bit, little-endian, data-type-policy=OVERRIDE, i-signal-type=PRIMITIVE, init-value=0, base-type=BT_TSG_FS_Spiegel_angeklappt, compu {0=Cx0_Spiegel_ausgeklappt (CM_TSG_FS_Spiegel_angeklappt_Cx0_Spiegel_ausgeklappt), 1=Cx1_Spiegel_eingeklappt (CM_TSG_FS_Spiegel_angeklappt_Cx1_Spiegel_eingeklappt)}, range raw 0..1  # Funktionsrückmeldung TSG_FS über Spiegelstellung angeklappt
          signal FT_Cargolock_bet_XIX_TSG_FT_02_XIX_E3V_K2CANFD: start 38, 1 bit, little-endian, data-type-policy=OVERRIDE, i-signal-type=PRIMITIVE, init-value=0, base-type=BT_FT_Cargolock_bet, compu {0=Cx0_nicht_betaetigt (CM_FT_Cargolock_bet_Cx0_nicht_betaetigt), 1=Cx1_betaetigt (CM_FT_Cargolock_bet_Cx1_betaetigt)}, range raw 0..1  # CargoLock-Taste betätigt
          signal ISignalVoid_TSG_FT_02_XIX_E3V_K2CANFD_0: start 39, 1 bit, little-endian, system signal SignalVoid_TSG_FT_02_0, data-type-policy=OVERRIDE, i-signal-type=PRIMITIVE, base-type=BT_SignalVoid
          signal FT_kisi_asynchron_XIX_TSG_FT_02_XIX_E3V_K2CANFD: start 40, 1 bit, little-endian, data-type-policy=OVERRIDE, i-signal-type=PRIMITIVE, init-value=0, base-type=BT_FT_kisi_asynchron, compu {0=Cx0_nicht_aktiv (CM_FT_kisi_asynchron_Cx0_nicht_aktiv), 1=Cx1_aktiv (CM_FT_kisi_asynchron_Cx1_aktiv)}, range raw 0..1  # Signal erzeugt eine seperate Warnmeldung bei ungewollter Asynchronität der "elektrische Kindersicherung" der Schlösser.
          signal ISignalVoid_TSG_FT_02_XIX_E3V_K2CANFD_1: start 41, 1 bit, little-endian, system signal SignalVoid_TSG_FT_02_1, data-type-policy=OVERRIDE, i-signal-type=PRIMITIVE, base-type=BT_SignalVoid
          signal FS_Status_eTAG_ext_XIX_TSG_FT_02_XIX_E3V_K2CANFD: start 42, 3 bit, little-endian, data-type-policy=OVERRIDE, i-signal-type=PRIMITIVE, init-value=3, base-type=BT_FS_Status_eTAG_ext, invalid-value=Invalid_FS_Status_eTAG_ext_XIX_TSG_FT_02_XIX_E3V_K2CANFD:4, compu {0=Cx0_Griff_eingefahren (CM_FS_Status_eTAG_ext_Cx0_Griff_eingefahren), 1=Cx1_Griff_ausgefahren (CM_FS_Status_eTAG_ext_Cx1_Griff_ausgefahren), 2=Cx2_Griff_verfaehrt (CM_FS_Status_eTAG_ext_Cx2_Griff_verfaehrt), 3=Cx3_init (CM_FS_Status_eTAG_ext_Cx3_init), 4=Cx4_Fehler (CM_FS_Status_eTAG_ext_Cx4_Fehler)}, range raw 0..4  # erweitert um den Wert "verfährt"
          signal FT_ASW_Warnton_XIX_TSG_FT_02_XIX_E3V_K2CANFD: start 45, 2 bit, little-endian, data-type-policy=OVERRIDE, i-signal-type=PRIMITIVE, init-value=0, base-type=BT_FT_ASW_Warnton, invalid-value=Invalid_FT_ASW_Warnton_XIX_TSG_FT_02_XIX_E3V_K2CANFD:3, compu {0=Cx0_kein_warnton (CM_FT_ASW_Warnton_Cx0_kein_warnton), 1=Cx1_warnton_links (CM_FT_ASW_Warnton_Cx1_warnton_links), 2=Cx2_warnton_rechts (CM_FT_ASW_Warnton_Cx2_warnton_rechts), 3=Cx3_Fehler (CM_FT_ASW_Warnton_Cx3_Fehler)}, range raw 0..3  # erzeugt ein Warnton bei AS Warnung
          signal SSA_FT_ASW_Status_XIX_TSG_FT_02_XIX_E3V_K2CANFD: start 47, 2 bit, little-endian, data-type-policy=OVERRIDE, i-signal-type=PRIMITIVE, init-value=0, base-type=BT_SSA_FT_ASW_Status, compu {0=Cx0_Init (CM_SSA_FT_ASW_Status_Cx0_Init), 1=Cx1_InfoStufe_aktiv (CM_SSA_FT_ASW_Status_Cx1_InfoStufe_aktiv), 2=Cx2_Warnstufe_aktiv (CM_SSA_FT_ASW_Status_Cx2_Warnstufe_aktiv)}, range raw 0..2  # SmartSensorActor: Rückmeldung des Status der ASW Anzeige.
          signal ISignalVoid_TSG_FT_02_XIX_E3V_K2CANFD_2: start 49, 7 bit, little-endian, system signal SignalVoid_TSG_FT_02_2, data-type-policy=OVERRIDE, i-signal-type=PRIMITIVE, base-type=BT_SignalVoid
          signal ISignalVoid_TSG_FT_02_XIX_E3V_K2CANFD_3: start 56, 8 bit, little-endian, system signal SignalVoid_TSG_FT_02_3, data-type-policy=OVERRIDE, i-signal-type=PRIMITIVE, base-type=BT_SignalVoid
          mapping SG_TSG_FT_02_XIX_E3V_K2CANFD: i-signal-group=SG_TSG_FT_02_XIX_E3V_K2CANFD, transfer-property=TRIGGERED-WITHOUT-REPETITION
      frame TSG_HBFS_01_XIX_E3V_K2CANFD: id 0x3CF, from SAM, to SAM, frame-length=8, can-addressing-mode=STANDARD, can-frame-rx-behavior=CAN-FD, can-frame-tx-behavior=CAN-FD
        pdu TSG_HBFS_01_XIX_E3V_K2CANFD: length=8, minimum-delay=0.02, transmission-mode-true-timing={cyclic-timing={time-offset=0.0, time-period=0.1}, event-controlled-timing={number-of-repetitions=0, repetition-period=0.0}}, unused-bit-pattern=0
          signal HBFS_Tuer_geoeffnet_XIX_TSG_HBFS_01_XIX_E3V_K2CANFD: start 0, 1 bit, little-endian, data-type-policy=OVERRIDE, i-signal-type=PRIMITIVE, init-value=0, base-type=BT_HBFS_Tuer_geoeffnet, compu {0=Cx0_geschlossen (CM_HBFS_Tuer_geoeffnet_Cx0_geschlossen), 1=Cx1_offen (CM_HBFS_Tuer_geoeffnet_Cx1_offen)}, range raw 0..1, transfer-property=TRIGGERED-ON-CHANGE-WITHOUT-REPETITION, to SAM(timeout 1 s)  # HBFS Tuer geoeffnet
          signal HBFS_verriegelt_XIX_TSG_HBFS_01_XIX_E3V_K2CANFD: start 1, 1 bit, little-endian, data-type-policy=OVERRIDE, i-signal-type=PRIMITIVE, init-value=0, base-type=BT_HBFS_verriegelt, compu {0=Cx0_nicht_verriegelt (CM_HBFS_verriegelt_Cx0_nicht_verriegelt), 1=Cx1_verriegelt (CM_HBFS_verriegelt_Cx1_verriegelt)}, range raw 0..1, transfer-property=TRIGGERED-ON-CHANGE-WITHOUT-REPETITION  # Verriegelungsstatus Tür
          signal HBFS_gesafet_XIX_TSG_HBFS_01_XIX_E3V_K2CANFD: start 2, 1 bit, little-endian, data-type-policy=OVERRIDE, i-signal-type=PRIMITIVE, init-value=0, base-type=BT_HBFS_gesafet, compu {0=Cx0_nicht_gesafet (CM_HBFS_gesafet_Cx0_nicht_gesafet), 1=Cx1_gesafet (CM_HBFS_gesafet_Cx1_gesafet)}, range raw 0..1, transfer-property=TRIGGERED-ON-CHANGE-WITHOUT-REPETITION  # HBFS Tuer gesafet. Im Zustand Safe wird auch das Signal HBFS_verriegelt = 1 gesendet.
          signal HBFS_Heckrollotaster_betaetigt_XIX_TSG_HBFS_01_XIX_E3V_K2CANFD: start 3, 1 bit, little-endian, data-type-policy=OVERRIDE, i-signal-type=PRIMITIVE, init-value=0, base-type=BT_HBFS_Heckrollotaster_betaetigt, compu {0=Cx0_keine_Verfahranweisung_in_Richtung_Hoch (CM_HBFS_Heckrollotaster_betaetigt_Cx0_keine_Verfahranweisung_in_Richtung_Hoch), 1=Cx1_In_Richtung_Hoch_Verfahren (CM_HBFS_Heckrollotaster_betaetigt_Cx1_In_Richtung_Hoch_Verfahren)}, range raw 0..1, transfer-property=TRIGGERED-ON-CHANGE-WITHOUT-REPETITION  # Verfahren des Heckrollos in Richtung Hoch Bei Einfachtaster wird Bit als Togglebit verwendet (Heckrollo hoch, tief)
          signal HBFS_Tuerschloss_defekt_XIX_TSG_HBFS_01_XIX_E3V_K2CANFD: start 4, 1 bit, little-endian, data-type-policy=OVERRIDE, i-signal-type=PRIMITIVE, base-type=BT_HBFS_Tuerschloss_defekt, compu {0=Cx0_Tuerschloss_funktionsfaehig (CM_HBFS_Tuerschloss_defekt_Cx0_Tuerschloss_funktionsfaehig), 1=Cx1_Tuerschloss_defekt (CM_HBFS_Tuerschloss_defekt_Cx1_Tuerschloss_defekt)}, range raw 0..1, transfer-property=PENDING  # Das hintere Tuerschloss auf der Beifahrerseite ist nicht mehr funktionsfähig.
          signal HBFS_Unlock_Taster_XIX_TSG_HBFS_01_XIX_E3V_K2CANFD: start 5, 1 bit, little-endian, data-type-policy=OVERRIDE, i-signal-type=PRIMITIVE, init-value=0, base-type=BT_HBFS_Unlock_Taster, compu {0=Cx0_nicht_betaetigt (CM_HBFS_Unlock_Taster_Cx0_nicht_betaetigt), 1=Cx1_betaetigt (CM_HBFS_Unlock_Taster_Cx1_betaetigt)}, range raw 0..1, transfer-property=TRIGGERED-ON-CHANGE-WITHOUT-REPETITION  # Betaetigung Unlock Taster
          signal HBFS_Lock_Taster_XIX_TSG_HBFS_01_XIX_E3V_K2CANFD: start 6, 1 bit, little-endian, data-type-policy=OVERRIDE, i-signal-type=PRIMITIVE, init-value=0, base-type=BT_HBFS_Lock_Taster, compu {0=Cx0_nicht_betaetigt (CM_HBFS_Lock_Taster_Cx0_nicht_betaetigt), 1=Cx1_betaetigt (CM_HBFS_Lock_Taster_Cx1_betaetigt)}, range raw 0..1, transfer-property=TRIGGERED-ON-CHANGE-WITHOUT-REPETITION  # Betaetigung Lock-Taster
          signal HBFS_Sperrklinke_XIX_TSG_HBFS_01_XIX_E3V_K2CANFD: start 7, 1 bit, little-endian, data-type-policy=OVERRIDE, i-signal-type=PRIMITIVE, init-value=0, base-type=BT_HBFS_Sperrklinke, compu {0=Cx0_Schloss_in_Vorraste_und_Hauptraste (CM_HBFS_Sperrklinke_Cx0_Schloss_in_Vorraste_und_Hauptraste), 1=Cx1_Tuer_auf_oder_Tuer_Position_zwischen_Vor_und_Hauptraste (CM_HBFS_Sperrklinke_Cx1_Tuer_auf_oder_Tuer_Position_zwischen_Vor_und_Hauptraste)}, range raw 0..1, transfer-property=TRIGGERED-ON-CHANGE-WITHOUT-REPETITION  # Vorraste für Schloß zwischen Vor- und Hauptraste Signal kurz auf 1, danach wieder auf 0 wenn Tür in Hauptraste (Tür ist sicher zu wenn Sperrklinke und Türkontakt auf 0 sind)
          signal HBFS_TAG_betaetigt_XIX_TSG_HBFS_01_XIX_E3V_K2CANFD: start 8, 1 bit, little-endian, data-type-policy=OVERRIDE, i-signal-type=PRIMITIVE, init-value=0, base-type=BT_HBFS_TAG_betaetigt, compu {0=Cx0_nicht_betaetigt (CM_HBFS_TAG_betaetigt_Cx0_nicht_betaetigt), 1=Cx1_betaetigt (CM_HBFS_TAG_betaetigt_Cx1_betaetigt)}, range raw 0..1, transfer-property=TRIGGERED-ON-CHANGE-WITHOUT-REPETITION  # Betaetigung Türaussengriff
          signal HBFS_TIG_betaetigt_XIX_TSG_HBFS_01_XIX_E3V_K2CANFD: start 9, 1 bit, little-endian, data-type-policy=OVERRIDE, i-signal-type=PRIMITIVE, init-value=0, base-type=BT_HBFS_TIG_betaetigt, compu {0=Cx0_nicht_betaetigt (CM_HBFS_TIG_betaetigt_Cx0_nicht_betaetigt), 1=Cx1_betaetigt (CM_HBFS_TIG_betaetigt_Cx1_betaetigt)}, range raw 0..1, transfer-property=TRIGGERED-ON-CHANGE-WITHOUT-REPETITION, to SAM(timeout 1 s)  # Betaetigung Tuerinnengriff
          signal HBFS_FH_S_HFS_AutoHoch_XIX_TSG_HBFS_01_XIX_E3V_K2CANFD: start 10, 1 bit, little-endian, data-type-policy=OVERRIDE, i-signal-type=PRIMITIVE, init-value=0, base-type=BT_HBFS_FH_S_HFS_AutoHoch, compu {0=Cx0_keine_Bedienung (CM_HBFS_FH_S_HFS_AutoHoch_Cx0_keine_Bedienung), 1=Cx1_Automatiklauf_Angefordert (CM_HBFS_FH_S_HFS_AutoHoch_Cx1_Automatiklauf_Angefordert)}, range raw 0..1, transfer-property=TRIGGERED-ON-CHANGE-WITHOUT-REPETITION  # Automatisches Hochfahren der Seitenscheibe HFS
          signal HBFS_FH_S_HFS_AutoTief_XIX_TSG_HBFS_01_XIX_E3V_K2CANFD: start 11, 1 bit, little-endian, data-type-policy=OVERRIDE, i-signal-type=PRIMITIVE, init-value=0, base-type=BT_HBFS_FH_S_HFS_AutoTief, compu {0=Cx0_keine_Bedienung (CM_HBFS_FH_S_HFS_AutoTief_Cx0_keine_Bedienung), 1=Cx1_Automatiklauf_Angefordert (CM_HBFS_FH_S_HFS_AutoTief_Cx1_Automatiklauf_Angefordert)}, range raw 0..1, transfer-property=TRIGGERED-ON-CHANGE-WITHOUT-REPETITION  # Automatisches Absenken der Seitenscheibe HFS
          signal HBFS_FH_S_HFS_ManHoch_XIX_TSG_HBFS_01_XIX_E3V_K2CANFD: start 12, 1 bit, little-endian, data-type-policy=OVERRIDE, i-signal-type=PRIMITIVE, init-value=0, base-type=BT_HBFS_FH_S_HFS_ManHoch, compu {0=Cx0_keine_Bedienung (CM_HBFS_FH_S_HFS_ManHoch_Cx0_keine_Bedienung), 1=Cx1_Manueller_Lauf_Angefordert (CM_HBFS_FH_S_HFS_ManHoch_Cx1_Manueller_Lauf_Angefordert)}, range raw 0..1, transfer-property=TRIGGERED-ON-CHANGE-WITHOUT-REPETITION  # Manuelles Hochfahren der Seitenscheibe HFS
          signal HBFS_FH_S_HFS_ManTief_XIX_TSG_HBFS_01_XIX_E3V_K2CANFD: start 13, 1 bit, little-endian, data-type-policy=OVERRIDE, i-signal-type=PRIMITIVE, init-value=0, base-type=BT_HBFS_FH_S_HFS_ManTief, compu {0=Cx0_keine_Bedienung (CM_HBFS_FH_S_HFS_ManTief_Cx0_keine_Bedienung), 1=Cx1_Manueller_Lauf_Angefordert (CM_HBFS_FH_S_HFS_ManTief_Cx1_Manueller_Lauf_Angefordert)}, range raw 0..1, transfer-property=TRIGGERED-ON-CHANGE-WITHOUT-REPETITION  # Manuelles Absenken der Seitenscheibe HFS
          signal HBFS_Tuer_Status_XIX_TSG_HBFS_01_XIX_E3V_K2CANFD: start 14, 2 bit, little-endian, data-type-policy=OVERRIDE, i-signal-type=PRIMITIVE, init-value=0, base-type=BT_HBFS_Tuer_Status, invalid-value=Invalid_HBFS_Tuer_Status_XIX_TSG_HBFS_01_XIX_E3V_K2CANFD:3, compu {0=Cx0_Init (CM_HBFS_Tuer_Status_Cx0_Init), 1=Cx1_Tuer_geschlossen (CM_HBFS_Tuer_Status_Cx1_Tuer_geschlossen), 2=Cx2_Tuer_offen (CM_HBFS_Tuer_Status_Cx2_Tuer_offen), 3=Cx3_Fehler (CM_HBFS_Tuer_Status_Cx3_Fehler)}, range raw 0..3, transfer-property=TRIGGERED-ON-CHANGE-WITHOUT-REPETITION  # Türstatus mit Fehler und Initwert
          signal HBFS_SAD_Schalter_XIX_TSG_HBFS_01_XIX_E3V_K2CANFD: start 16, 4 bit, little-endian, data-type-policy=OVERRIDE, i-signal-type=PRIMITIVE, init-value=14, base-type=BT_HBFS_SAD_Schalter, invalid-value=Invalid_HBFS_SAD_Schalter_XIX_TSG_HBFS_01_XIX_E3V_K2CANFD:15, compu {0=Cx0_nicht_betaetigt (CM_HBFS_SAD_Schalter_Cx0_nicht_betaetigt), 5=Cx5_AUF_manuell (CM_HBFS_SAD_Schalter_Cx5_AUF_manuell), 6=Cx6_AUF_automatik (CM_HBFS_SAD_Schalter_Cx6_AUF_automatik), 7=Cx7_ZU_manuell (CM_HBFS_SAD_Schalter_Cx7_ZU_manuell), 8=Cx8_ZU_automatik (CM_HBFS_SAD_Schalter_Cx8_ZU_automatik), 13=Cxd_nicht_verfuegbar (CM_HBFS_SAD_Schalter_Cxd_nicht_verfuegbar), 14=Cxe_Init (CM_HBFS_SAD_Schalter_Cxe_Init), 15=Cxf_Fehler (CM_HBFS_SAD_Schalter_Cxf_Fehler)}, range raw 0..15, transfer-property=TRIGGERED-ON-CHANGE-WITHOUT-REPETITION  # | Ausstelldach MD3 ----------------------------- 0 | nicht_betaetigt 1 | 2 | 3 | 4 | 5 | (m) Auf 6 | (a) Auf 7 | (m) Zu 8 | (a) Zu 13| Schalter nicht verfuegbar 14| Init 15| Fehlerfall
          signal HBFS_FH_S_ManHoch_XIX_TSG_HBFS_01_XIX_E3V_K2CANFD: start 20, 1 bit, little-endian, data-type-policy=OVERRIDE, i-signal-type=PRIMITIVE, init-value=0, base-type=BT_HBFS_FH_S_ManHoch, compu {0=Cx0_nicht_betaetigt (CM_HBFS_FH_S_ManHoch_Cx0_nicht_betaetigt), 1=Cx1_betaetigt (CM_HBFS_FH_S_ManHoch_Cx1_betaetigt)}, range raw 0..1, transfer-property=TRIGGERED-ON-CHANGE-WITHOUT-REPETITION, to SAM(timeout 1 s)  # Betaetigung FH Schalter man hoch
          signal HBFS_FH_S_AutoHoch_XIX_TSG_HBFS_01_XIX_E3V_K2CANFD: start 21, 1 bit, little-endian, data-type-policy=OVERRIDE, i-signal-type=PRIMITIVE, init-value=0, base-type=BT_HBFS_FH_S_AutoHoch, compu {0=Cx0_nicht_betaetigt (CM_HBFS_FH_S_AutoHoch_Cx0_nicht_betaetigt), 1=Cx1_betaetigt (CM_HBFS_FH_S_AutoHoch_Cx1_betaetigt)}, range raw 0..1, transfer-property=TRIGGERED-ON-CHANGE-WITHOUT-REPETITION, to SAM(timeout 1 s)  # Betaetigung FH Schalter auto tief
          signal HBFS_FH_S_ManTief_XIX_TSG_HBFS_01_XIX_E3V_K2CANFD: start 22, 1 bit, little-endian, data-type-policy=OVERRIDE, i-signal-type=PRIMITIVE, init-value=0, base-type=BT_HBFS_FH_S_ManTief, compu {0=Cx0_nicht_betaetigt (CM_HBFS_FH_S_ManTief_Cx0_nicht_betaetigt), 1=Cx1_betaetigt (CM_HBFS_FH_S_ManTief_Cx1_betaetigt)}, range raw 0..1, transfer-property=TRIGGERED-ON-CHANGE-WITHOUT-REPETITION, to SAM(timeout 1 s)  # Betaetigung FH Schalter man tief
          signal HBFS_FH_S_AutoTief_XIX_TSG_HBFS_01_XIX_E3V_K2CANFD: start 23, 1 bit, little-endian, data-type-policy=OVERRIDE, i-signal-type=PRIMITIVE, init-value=0, base-type=BT_HBFS_FH_S_AutoTief, compu {0=Cx0_nicht_betaetigt (CM_HBFS_FH_S_AutoTief_Cx0_nicht_betaetigt), 1=Cx1_betaetigt (CM_HBFS_FH_S_AutoTief_Cx1_betaetigt)}, range raw 0..1, transfer-property=TRIGGERED-ON-CHANGE-WITHOUT-REPETITION, to SAM(timeout 1 s)  # Betaetigung FH Schalter auto hoch
          signal HBFS_FH_Oeffnung_XIX_TSG_HBFS_01_XIX_E3V_K2CANFD: start 24, 8 bit, little-endian, data-type-policy=OVERRIDE, i-signal-type=PRIMITIVE, init-value=0, base-type=BT_HBFS_FH_Oeffnung, compu {phys=raw*0.5 for raw 0..200; unit Unit_PerCent}, range phys 0..100 Unit_PerCent, raw 0..200, unit=Unit_PerCent, transfer-property=TRIGGERED-ON-CHANGE-WITHOUT-REPETITION  # Gibt den Fensteröffnungswert in % an.
          signal HBFS_FH_Bew_hoch_XIX_TSG_HBFS_01_XIX_E3V_K2CANFD: start 32, 1 bit, little-endian, data-type-policy=OVERRIDE, i-signal-type=PRIMITIVE, init-value=0, base-type=BT_HBFS_FH_Bew_hoch, compu {0=Cx0_inaktiv (CM_HBFS_FH_Bew_hoch_Cx0_inaktiv), 1=Cx1_aktiv (CM_HBFS_FH_Bew_hoch_Cx1_aktiv)}, range raw 0..1, transfer-property=TRIGGERED-ON-CHANGE-WITHOUT-REPETITION  # HBFS Fenster bewegt sich in Richtung hoch
          signal HBFS_FH_Bew_tief_XIX_TSG_HBFS_01_XIX_E3V_K2CANFD: start 33, 1 bit, little-endian, data-type-policy=OVERRIDE, i-signal-type=PRIMITIVE, init-value=0, base-type=BT_HBFS_FH_Bew_tief, compu {0=Cx0_inaktiv (CM_HBFS_FH_Bew_tief_Cx0_inaktiv), 1=Cx1_aktiv (CM_HBFS_FH_Bew_tief_Cx1_aktiv)}, range raw 0..1, transfer-property=TRIGGERED-ON-CHANGE-WITHOUT-REPETITION  # HBFS Fenster bewegt sich in Richtung tief
          signal HBFS_FH_Fang_XIX_TSG_HBFS_01_XIX_E3V_K2CANFD: start 34, 1 bit, little-endian, data-type-policy=OVERRIDE, i-signal-type=PRIMITIVE, init-value=0, base-type=BT_HBFS_FH_Fang, compu {0=Cx0_ausserhalb_Fangbereich (CM_HBFS_FH_Fang_Cx0_ausserhalb_Fangbereich), 1=Cx1_innerhalb_Fangbereich (CM_HBFS_FH_Fang_Cx1_innerhalb_Fangbereich)}, range raw 0..1, transfer-property=TRIGGERED-ON-CHANGE-WITHOUT-REPETITION  # Fangbereich ist 4mm von oberer Lippendichtung
          signal HBFS_FH_Block_XIX_TSG_HBFS_01_XIX_E3V_K2CANFD: start 35, 1 bit, little-endian, data-type-policy=OVERRIDE, i-signal-type=PRIMITIVE, init-value=0, base-type=BT_HBFS_FH_Block, compu {0=Cx0_inaktiv (CM_HBFS_FH_Block_Cx0_inaktiv), 1=Cx1_aktiv (CM_HBFS_FH_Block_Cx1_aktiv)}, range raw 0..1, transfer-property=TRIGGERED-ON-CHANGE-WITHOUT-REPETITION  # Fensterscheibe befindet sich im mechanischen Block (oben oder unten)
          signal HBFS_FH_Thermo_XIX_TSG_HBFS_01_XIX_E3V_K2CANFD: start 36, 1 bit, little-endian, data-type-policy=OVERRIDE, i-signal-type=PRIMITIVE, init-value=0, base-type=BT_HBFS_FH_Thermo, compu {0=Cx0_inaktiv (CM_HBFS_FH_Thermo_Cx0_inaktiv), 1=Cx1_aktiv (CM_HBFS_FH_Thermo_Cx1_aktiv)}, range raw 0..1, transfer-property=TRIGGERED-ON-CHANGE-WITHOUT-REPETITION  # gibt an ob Fensterheber im Thermoschutz ist
          signal HBFS_UEKB_aktiviert_XIX_TSG_HBFS_01_XIX_E3V_K2CANFD: start 37, 1 bit, little-endian, data-type-policy=OVERRIDE, i-signal-type=PRIMITIVE, init-value=0, base-type=BT_HBFS_UEKB_aktiviert, compu {0=Cx0_inaktiv (CM_HBFS_UEKB_aktiviert_Cx0_inaktiv), 1=Cx1_aktiv (CM_HBFS_UEKB_aktiviert_Cx1_aktiv)}, range raw 0..1, transfer-property=TRIGGERED-ON-CHANGE-WITHOUT-REPETITION  # Überschutzbegrenzungskraft bei Reversieren
          signal HBFS_Tueroeffnen_Warnung_XIX_TSG_HBFS_01_XIX_E3V_K2CANFD: start 38, 1 bit, little-endian, data-type-policy=OVERRIDE, i-signal-type=PRIMITIVE, init-value=0, base-type=BT_HBFS_Tueroeffnen_Warnung, compu {0=Cx0_Tuerwarnung_nicht_aktiv (CM_HBFS_Tueroeffnen_Warnung_Cx0_Tuerwarnung_nicht_aktiv), 1=Cx1_Tuerwarnung_aktiv (CM_HBFS_Tueroeffnen_Warnung_Cx1_Tuerwarnung_aktiv)}, range raw 0..1, transfer-property=TRIGGERED-ON-CHANGE-WITHOUT-REPETITION  # Bit wird gesetzt, wenn Tür während der Fahrt geoeffnet werden soll.
          signal HBFS_FH_normiert_XIX_TSG_HBFS_01_XIX_E3V_K2CANFD: start 39, 1 bit, little-endian, data-type-policy=OVERRIDE, i-signal-type=PRIMITIVE, init-value=0, base-type=BT_HBFS_FH_normiert, compu {0=Cx0_inaktiv (CM_HBFS_FH_normiert_Cx0_inaktiv), 1=Cx1_aktiv (CM_HBFS_FH_normiert_Cx1_aktiv)}, range raw 0..1, transfer-property=TRIGGERED-ON-CHANGE-WITHOUT-REPETITION  # Die Position der Fensterheberscheibe ist bekannt.
          signal ASW_Warnung_aktiv_HBFS_XIX_TSG_HBFS_01_XIX_E3V_K2CANFD: start 40, 1 bit, little-endian, data-type-policy=OVERRIDE, i-signal-type=PRIMITIVE, init-value=0, base-type=BT_ASW_Warnung_aktiv_HBFS, compu {0=Cx0_nicht_angefordert (CM_ASW_Warnung_aktiv_HBFS_Cx0_nicht_angefordert), 1=Cx1_angefordert (CM_ASW_Warnung_aktiv_HBFS_Cx1_angefordert)}, range raw 0..1, transfer-property=TRIGGERED-ON-CHANGE-WITHOUT-REPETITION, to SAM(timeout 1 s)  # Abschaltung der Ambientefunktion Tür hinten der Beifahrerseite bei aktiver ASW Warnung an der Fahrertür
          signal HBFS_Zuziehhilfe_aktiv_XIX_TSG_HBFS_01_XIX_E3V_K2CANFD: start 41, 1 bit, little-endian, data-type-policy=OVERRIDE, i-signal-type=PRIMITIVE, init-value=0, base-type=BT_HBFS_Zuziehhilfe_aktiv, compu {0=Cx0_Init (CM_HBFS_Zuziehhilfe_aktiv_Cx0_Init), 1=Cx1_Zuziehhilfe_aktiv (CM_HBFS_Zuziehhilfe_aktiv_Cx1_Zuziehhilfe_aktiv)}, range raw 0..1, transfer-property=TRIGGERED-ON-CHANGE-WITHOUT-REPETITION  # Zuziehhilfe aktiv
          signal HBFS_Seitenrollo_hoch_XIX_TSG_HBFS_01_XIX_E3V_K2CANFD: start 42, 1 bit, little-endian, data-type-policy=OVERRIDE, i-signal-type=PRIMITIVE, init-value=0, base-type=BT_HBFS_Seitenrollo_hoch, compu {0=Cx0_Init (CM_HBFS_Seitenrollo_hoch_Cx0_Init), 1=Cx1_Seitenrollo_in_Bewegung_hoch (CM_HBFS_Seitenrollo_hoch_Cx1_Seitenrollo_in_Bewegung_hoch)}, range raw 0..1, transfer-property=TRIGGERED-ON-CHANGE-WITHOUT-REPETITION  # Seitenrollo in Bewegung Richtung hoch
          signal HBFS_Seitenrollo_tief_XIX_TSG_HBFS_01_XIX_E3V_K2CANFD: start 43, 1 bit, little-endian, data-type-policy=OVERRIDE, i-signal-type=PRIMITIVE, init-value=0, base-type=BT_HBFS_Seitenrollo_tief, compu {0=Cx0_Init (CM_HBFS_Seitenrollo_tief_Cx0_Init), 1=Cx1_Seitenrollo_in_Bewegung_tief (CM_HBFS_Seitenrollo_tief_Cx1_Seitenrollo_in_Bewegung_tief)}, range raw 0..1, transfer-property=TRIGGERED-ON-CHANGE-WITHOUT-REPETITION  # Seitenrollo in Bewegung Richtung tief
          signal HBFS_Status_KiSi_XIX_TSG_HBFS_01_XIX_E3V_K2CANFD: start 44, 1 bit, little-endian, data-type-policy=OVERRIDE, i-signal-type=PRIMITIVE, init-value=0, base-type=BT_HBFS_Status_KiSi, compu {0=Cx0_inaktiv (CM_HBFS_Status_KiSi_Cx0_inaktiv), 1=Cx1_aktiv (CM_HBFS_Status_KiSi_Cx1_aktiv)}, range raw 0..1, transfer-property=TRIGGERED-ON-CHANGE-WITHOUT-REPETITION, to SAM(timeout 1 s)  # Status Kindersicherung HBFS
          signal SSR_HBFS_Pos_Unten_XIX_TSG_HBFS_01_XIX_E3V_K2CANFD: start 45, 1 bit, little-endian, data-type-policy=OVERRIDE, i-signal-type=PRIMITIVE, init-value=0, base-type=BT_SSR_HBFS_Pos_Unten, compu {0=Cx0_SSR_Oben (CM_SSR_HBFS_Pos_Unten_Cx0_SSR_Oben), 1=Cx1_SSR_Unten (CM_SSR_HBFS_Pos_Unten_Cx1_SSR_Unten)}, range raw 0..1, transfer-property=PENDING  # Signal für die "Global Close". Über dieses Bit wissen die anderen TSGs, ob der SSR oder der FH verfahren werden darf.
          signal HBFS_Oben_Block_erw_XIX_TSG_HBFS_01_XIX_E3V_K2CANFD: start 46, 1 bit, little-endian, data-type-policy=OVERRIDE, i-signal-type=PRIMITIVE, init-value=0, base-type=BT_HBFS_Oben_Block_erw, compu {0=Cx0_Fensterheber_nicht_in_Blockerwar (CM_HBFS_Oben_Block_erw_Cx0_Fensterheber_nicht_in_Blockerwar), 1=Cx1_Fensterheber_in_Blockerwartung_o (CM_HBFS_Oben_Block_erw_Cx1_Fensterheber_in_Blockerwartung_o)}, range raw 0..1, transfer-property=TRIGGERED-ON-CHANGE-WITHOUT-REPETITION  # Fensterheber in Blockerwartung oben
          signal HBFS_Unten_Block_erw_XIX_TSG_HBFS_01_XIX_E3V_K2CANFD: start 47, 1 bit, little-endian, data-type-policy=OVERRIDE, i-signal-type=PRIMITIVE, init-value=0, base-type=BT_HBFS_Unten_Block_erw, compu {0=Cx0_Fensterheber_nicht_in_Blockerwar (CM_HBFS_Unten_Block_erw_Cx0_Fensterheber_nicht_in_Blockerwar), 1=Cx1_Fensterheber_in_Blockerwartung_u (CM_HBFS_Unten_Block_erw_Cx1_Fensterheber_in_Blockerwartung_u)}, range raw 0..1, transfer-property=TRIGGERED-ON-CHANGE-WITHOUT-REPETITION  # Fensterheber in Blockerwartung unten
          signal MTHBFS_M_Taste_XIX_TSG_HBFS_01_XIX_E3V_K2CANFD: start 48, 1 bit, little-endian, data-type-policy=OVERRIDE, i-signal-type=PRIMITIVE, init-value=0, base-type=BT_MTHBFS_M_Taste, compu {0=Cx0_nicht_betaetigt (CM_MTHBFS_M_Taste_Cx0_nicht_betaetigt), 1=Cx1_betaetigt (CM_MTHBFS_M_Taste_Cx1_betaetigt)}, range raw 0..1, transfer-property=TRIGGERED-ON-CHANGE-WITHOUT-REPETITION  # Betätigung M-Taste HBFS
          signal MTHBFS_Pos1_XIX_TSG_HBFS_01_XIX_E3V_K2CANFD: start 49, 1 bit, little-endian, data-type-policy=OVERRIDE, i-signal-type=PRIMITIVE, init-value=0, base-type=BT_MTHBFS_Pos1, compu {0=Cx0_nicht_betaetigt (CM_MTHBFS_Pos1_Cx0_nicht_betaetigt), 1=Cx1_betaetigt (CM_MTHBFS_Pos1_Cx1_betaetigt)}, range raw 0..1, transfer-property=TRIGGERED-ON-CHANGE-WITHOUT-REPETITION  # Betätigung Postionstaste 1 HBFS
          signal MTHBFS_Pos2_XIX_TSG_HBFS_01_XIX_E3V_K2CANFD: start 50, 1 bit, little-endian, data-type-policy=OVERRIDE, i-signal-type=PRIMITIVE, init-value=0, base-type=BT_MTHBFS_Pos2, compu {0=Cx0_nicht_betaetigt (CM_MTHBFS_Pos2_Cx0_nicht_betaetigt), 1=Cx1_betaetigt (CM_MTHBFS_Pos2_Cx1_betaetigt)}, range raw 0..1, transfer-property=TRIGGERED-ON-CHANGE-WITHOUT-REPETITION  # Betätigung Postionstaste 2 HBFS
          signal MTHBFS_Pos3_XIX_TSG_HBFS_01_XIX_E3V_K2CANFD: start 51, 1 bit, little-endian, data-type-policy=OVERRIDE, i-signal-type=PRIMITIVE, init-value=0, base-type=BT_MTHBFS_Pos3, compu {0=Cx0_nicht_betaetigt (CM_MTHBFS_Pos3_Cx0_nicht_betaetigt), 1=Cx1_betaetigt (CM_MTHBFS_Pos3_Cx1_betaetigt)}, range raw 0..1, transfer-property=TRIGGERED-ON-CHANGE-WITHOUT-REPETITION  # Betätigung Postionstaste 3 HBFS
          signal HBFS_MRollo_Schalter_XIX_TSG_HBFS_01_XIX_E3V_K2CANFD: start 52, 3 bit, little-endian, data-type-policy=OVERRIDE, i-signal-type=PRIMITIVE, init-value=6, base-type=BT_HBFS_MRollo_Schalter, invalid-value=Invalid_HBFS_MRollo_Schalter_XIX_TSG_HBFS_01_XIX_E3V_K2CANFD:7, compu {0=Cx0_nicht_betaetigt (CM_HBFS_MRollo_Schalter_Cx0_nicht_betaetigt), 1=Cx1_ZU_manuell (CM_HBFS_MRollo_Schalter_Cx1_ZU_manuell), 2=Cx2_ZU_automatik (CM_HBFS_MRollo_Schalter_Cx2_ZU_automatik), 3=Cx3_AUF_manuell (CM_HBFS_MRollo_Schalter_Cx3_AUF_manuell), 4=Cx4_AUF_automatik (CM_HBFS_MRollo_Schalter_Cx4_AUF_automatik), 5=Cx5_nicht_verfuegbar (CM_HBFS_MRollo_Schalter_Cx5_nicht_verfuegbar), 6=Cx6_Init (CM_HBFS_MRollo_Schalter_Cx6_Init), 7=Cx7_Fehler (CM_HBFS_MRollo_Schalter_Cx7_Fehler)}, range raw 0..7, transfer-property=TRIGGERED-ON-CHANGE-WITHOUT-REPETITION  # | MRollo2 ----------------------------- 0 | nicht_betaetigt 1 | (m) Zu 2 | (a) Zu 3 | (m) Auf 4 | (a) Auf 5 | Schalter nicht verfuegbar 6 | Init 7 | Fehlerfall
          signal HBFS_Lock_Taster_inv_XIX_TSG_HBFS_01_XIX_E3V_K2CANFD: start 55, 1 bit, little-endian, data-type-policy=OVERRIDE, i-signal-type=PRIMITIVE, base-type=BT_HBFS_Lock_Taster_inv, compu {0=Cx0_Lock_Taster_betaetgit (CM_HBFS_Lock_Taster_inv_Cx0_Lock_Taster_betaetgit) (Lock Taster betätgit), 1=Cx1_Lock_Taster_nicht_betaetigt (CM_HBFS_Lock_Taster_inv_Cx1_Lock_Taster_nicht_betaetigt) (Lock Taster nicht betätigt)}, range raw 0..1, transfer-property=TRIGGERED-ON-CHANGE-WITHOUT-REPETITION  # Lock Taster nicht betätigt
          signal HBFS_Status_KiSi_inv_XIX_TSG_HBFS_01_XIX_E3V_K2CANFD: start 56, 1 bit, little-endian, data-type-policy=OVERRIDE, i-signal-type=PRIMITIVE, init-value=1, base-type=BT_HBFS_Status_KiSi_inv, compu {0=Cx0_aktiv (CM_HBFS_Status_KiSi_inv_Cx0_aktiv), 1=Cx1_inaktiv (CM_HBFS_Status_KiSi_inv_Cx1_inaktiv)}, range raw 0..1, transfer-property=TRIGGERED-ON-CHANGE-WITHOUT-REPETITION  # Inverser Status der elektrischen Kindersicherung Beifahrerseite hinten
          signal HBFS_Status_eTAG_XIX_TSG_HBFS_01_XIX_E3V_K2CANFD: start 57, 2 bit, little-endian, data-type-policy=OVERRIDE, i-signal-type=PRIMITIVE, init-value=0, base-type=BT_HBFS_Status_eTAG, invalid-value=Invalid_HBFS_Status_eTAG_XIX_TSG_HBFS_01_XIX_E3V_K2CANFD:3, compu {0=Cx0_Init (CM_HBFS_Status_eTAG_Cx0_Init), 1=Cx1_Griff_ausgefahren (CM_HBFS_Status_eTAG_Cx1_Griff_ausgefahren), 2=Cx2_Griff_eingefahren (CM_HBFS_Status_eTAG_Cx2_Griff_eingefahren), 3=Cx3_Fehler (CM_HBFS_Status_eTAG_Cx3_Fehler)}, range raw 0..3, transfer-property=TRIGGERED-ON-CHANGE-WITHOUT-REPETITION  # Status des elektrischen Tueraussengriffes Tuer Beifahrerseite hinten
          signal HBFS_Tuer_Status_QBit_XIX_TSG_HBFS_01_XIX_E3V_K2CANFD: start 59, 1 bit, little-endian, data-type-policy=OVERRIDE, i-signal-type=PRIMITIVE, init-value=0, base-type=BT_HBFS_Tuer_Status_QBit, compu {0=Cx0_Status_Tuerkontakt_sicher (CM_HBFS_Tuer_Status_QBit_Cx0_Status_Tuerkontakt_sicher), 1=Cx1_Status_Tuerkontakt_unsicher (CM_HBFS_Tuer_Status_QBit_Cx1_Status_Tuerkontakt_unsicher)}, range raw 0..1, transfer-property=TRIGGERED-ON-CHANGE-WITHOUT-REPETITION  # Dieses Bit gibt die Zuverlässigkeit des Türkontakts an. Ein auf dieses Bit folgender Fehlereintrag ist mit dem Sender des Bits abzustimmen (gültig ab PPE).
          signal HBFS_TIG_betaetigt_schliessen_XIX_TSG_HBFS_01_XIX_E3V_K2CANFD: start 60, 1 bit, little-endian, data-type-policy=OVERRIDE, i-signal-type=PRIMITIVE, init-value=0, base-type=BT_HBFS_TIG_betaetigt_schliessen, compu {0=Cx0_nicht_betaetigt (CM_HBFS_TIG_betaetigt_schliessen_Cx0_nicht_betaetigt), 1=Cx1_betaetigt (CM_HBFS_TIG_betaetigt_schliessen_Cx1_betaetigt)}, range raw 0..1, transfer-property=TRIGGERED-ON-CHANGE-WITHOUT-REPETITION  # Türinnenbetätigung, Taster Tür schließen.
          signal HBFS_TIG_betaetigt_oeffnen_XIX_TSG_HBFS_01_XIX_E3V_K2CANFD: start 61, 1 bit, little-endian, data-type-policy=OVERRIDE, i-signal-type=PRIMITIVE, init-value=0, base-type=BT_HBFS_TIG_betaetigt_oeffnen, compu {0=Cx0_nicht_betaetigt (CM_HBFS_TIG_betaetigt_oeffnen_Cx0_nicht_betaetigt), 1=Cx1_betaetigt (CM_HBFS_TIG_betaetigt_oeffnen_Cx1_betaetigt)}, range raw 0..1, transfer-property=TRIGGERED-ON-CHANGE-WITHOUT-REPETITION  # Türinnenbetätigung, Taster Tür öffnen.
          signal HBFS_Vorraste_betaetigt_XIX_TSG_HBFS_01_XIX_E3V_K2CANFD: start 62, 1 bit, little-endian, data-type-policy=OVERRIDE, i-signal-type=PRIMITIVE, init-value=0, base-type=BT_HBFS_Vorraste_betaetigt, compu {0=Cx0_nicht_in_Vorraste (CM_HBFS_Vorraste_betaetigt_Cx0_nicht_in_Vorraste), 1=Cx1_in_Vorraste (CM_HBFS_Vorraste_betaetigt_Cx1_in_Vorraste)}, range raw 0..1, transfer-property=TRIGGERED-ON-CHANGE-WITHOUT-REPETITION  # Status der Vorraste
          signal HBFS_SK_betaetigt_XIX_TSG_HBFS_01_XIX_E3V_K2CANFD: start 63, 1 bit, little-endian, data-type-policy=OVERRIDE, i-signal-type=PRIMITIVE, init-value=0, base-type=BT_HBFS_SK_betaetigt, compu {0=Cx0_ausgehoben (CM_HBFS_SK_betaetigt_Cx0_ausgehoben), 1=Cx1_eingefallen (CM_HBFS_SK_betaetigt_Cx1_eingefallen)}, range raw 0..1, transfer-property=TRIGGERED-ON-CHANGE-WITHOUT-REPETITION  # Status der Sperrklinke
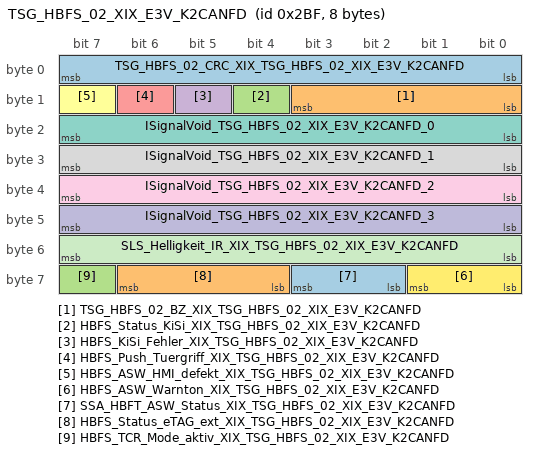
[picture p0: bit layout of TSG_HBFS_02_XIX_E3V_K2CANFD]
      frame TSG_HBFS_02_XIX_E3V_K2CANFD: id 0x2BF, from SAM, frame-length=8, can-addressing-mode=STANDARD, can-frame-rx-behavior=CAN-FD, can-frame-tx-behavior=CAN-FD
        pdu TSG_HBFS_02_XIX_E3V_K2CANFD_E2E: length=8, minimum-delay=0.02, transmission-mode-true-timing=event-controlled-timing={number-of-repetitions=0, repetition-period=0.0}, unused-bit-pattern=0  # Fuer die Botschaft ist das Cyclic-Timing 0.1 zu verwenden.
          signal TSG_HBFS_02_CRC_XIX_TSG_HBFS_02_XIX_E3V_K2CANFD: start 0, 8 bit, little-endian, data-type-policy=OVERRIDE, i-signal-type=PRIMITIVE, base-type=BT_TSG_HBFS_02_CRC, compu {phys=raw for raw 0..255}, range phys 0..255, raw 0..255  # Für MLB: Berechnung siehe Lastenheft "Kommunikationsabsicherung für FlexRay und CAN" Ab MQB und MLBevo: Berechnung siehe Lastenheft "End-to-End Kommunikationsabsicherung" Endwerte siehe Begleitdokument "S-PDU Kennungsfolgen"
          signal TSG_HBFS_02_BZ_XIX_TSG_HBFS_02_XIX_E3V_K2CANFD: start 8, 4 bit, little-endian, data-type-policy=OVERRIDE, i-signal-type=PRIMITIVE, base-type=BT_TSG_HBFS_02_BZ, compu {phys=raw for raw 0..15}, range phys 0..15, raw 0..15  # 4bit Botschaftszähler, wird mit jeder Sendebotschaft inkrementiert
          signal HBFS_Status_KiSi_XIX_TSG_HBFS_02_XIX_E3V_K2CANFD: start 12, 1 bit, little-endian, data-type-policy=OVERRIDE, i-signal-type=PRIMITIVE, init-value=0, base-type=BT_HBFS_Status_KiSi, compu {0=Cx0_inaktiv (CM_HBFS_Status_KiSi_Cx0_inaktiv), 1=Cx1_aktiv (CM_HBFS_Status_KiSi_Cx1_aktiv)}, range raw 0..1  # Status Kindersicherung HBFS
          signal HBFS_KiSi_Fehler_XIX_TSG_HBFS_02_XIX_E3V_K2CANFD: start 13, 1 bit, little-endian, data-type-policy=OVERRIDE, i-signal-type=PRIMITIVE, init-value=0, base-type=BT_HBFS_KiSi_Fehler, compu {0=Cx0_kein_Fehler (CM_HBFS_KiSi_Fehler_Cx0_kein_Fehler), 1=Cx1_Fehler_liegt_an (CM_HBFS_KiSi_Fehler_Cx1_Fehler_liegt_an)}, range raw 0..1  # Status der Kindersicherung unplausibel
          signal HBFS_Push_Tuergriff_XIX_TSG_HBFS_02_XIX_E3V_K2CANFD: start 14, 1 bit, little-endian, data-type-policy=OVERRIDE, i-signal-type=PRIMITIVE, init-value=0, base-type=BT_HBFS_Push_Tuergriff, compu {0=Cx0_nicht_erkannt (CM_HBFS_Push_Tuergriff_Cx0_nicht_erkannt), 1=Cx1_erkannt (CM_HBFS_Push_Tuergriff_Cx1_erkannt)}, range raw 0..1  # Push zum Ausfahren der Flush-Tuergriffe
          signal HBFS_ASW_HMI_defekt_XIX_TSG_HBFS_02_XIX_E3V_K2CANFD: start 15, 1 bit, little-endian, data-type-policy=OVERRIDE, i-signal-type=PRIMITIVE, init-value=0, base-type=BT_HBFS_ASW_HMI_defekt, compu {0=Cx0_ASW_kein_Fehler (CM_HBFS_ASW_HMI_defekt_Cx0_ASW_kein_Fehler), 1=Cx1_ASW_Fehler (CM_HBFS_ASW_HMI_defekt_Cx1_ASW_Fehler)}, range raw 0..1  # HMI Status der Funktion AusstiegsWarnung (ASW), HMI wird durch das TSG angesteuert.
          signal ISignalVoid_TSG_HBFS_02_XIX_E3V_K2CANFD_0: start 16, 8 bit, little-endian, system signal SignalVoid_TSG_HBFS_02_0, data-type-policy=OVERRIDE, i-signal-type=PRIMITIVE, base-type=BT_SignalVoid
          signal ISignalVoid_TSG_HBFS_02_XIX_E3V_K2CANFD_1: start 24, 8 bit, little-endian, system signal SignalVoid_TSG_HBFS_02_1, data-type-policy=OVERRIDE, i-signal-type=PRIMITIVE, base-type=BT_SignalVoid
          signal ISignalVoid_TSG_HBFS_02_XIX_E3V_K2CANFD_2: start 32, 8 bit, little-endian, system signal SignalVoid_TSG_HBFS_02_2, data-type-policy=OVERRIDE, i-signal-type=PRIMITIVE, base-type=BT_SignalVoid
          signal ISignalVoid_TSG_HBFS_02_XIX_E3V_K2CANFD_3: start 40, 8 bit, little-endian, system signal SignalVoid_TSG_HBFS_02_3, data-type-policy=OVERRIDE, i-signal-type=PRIMITIVE, base-type=BT_SignalVoid
          signal SLS_Helligkeit_IR_XIX_TSG_HBFS_02_XIX_E3V_K2CANFD: start 48, 8 bit, little-endian, data-type-policy=OVERRIDE, i-signal-type=PRIMITIVE, init-value=254, base-type=BT_SLS_Helligkeit_IR, invalid-value=Invalid_SLS_Helligkeit_IR_XIX_TSG_HBFS_02_XIX_E3V_K2CANFD:255, compu {phys=raw*250 for raw 0..28, 254=Cxfe_Init (CM_SLS_Helligkeit_IR_Cxfe_Init), 255=Cxff_Fehler (CM_SLS_Helligkeit_IR_Cxff_Fehler); unit Unit_Lux}, range phys 0..7000 Unit_Lux, raw 0..255, unit=Unit_Lux  # Helligkeitswert des "Smart-Light-Sensor" im Dashboard analog / alternativ zu LS_Helligkeit_IR. Es ist entweder ein RLS_LIN oder ein Smart-LS im FZG verbaut.
          signal HBFS_ASW_Warnton_XIX_TSG_HBFS_02_XIX_E3V_K2CANFD: start 56, 2 bit, little-endian, data-type-policy=OVERRIDE, i-signal-type=PRIMITIVE, init-value=0, base-type=BT_HBFS_ASW_Warnton, invalid-value=Invalid_HBFS_ASW_Warnton_XIX_TSG_HBFS_02_XIX_E3V_K2CANFD:3, compu {0=Cx0_kein_warnton (CM_HBFS_ASW_Warnton_Cx0_kein_warnton), 1=Cx1_warnton_links (CM_HBFS_ASW_Warnton_Cx1_warnton_links), 2=Cx2_warnton_rechts (CM_HBFS_ASW_Warnton_Cx2_warnton_rechts), 3=Cx3_Fehler (CM_HBFS_ASW_Warnton_Cx3_Fehler)}, range raw 0..3  # erzeugt ein Warnton bei AS Warnung
          signal SSA_HBFT_ASW_Status_XIX_TSG_HBFS_02_XIX_E3V_K2CANFD: start 58, 2 bit, little-endian, data-type-policy=OVERRIDE, i-signal-type=PRIMITIVE, init-value=0, base-type=BT_SSA_HBFT_ASW_Status, compu {0=Cx0_Init (CM_SSA_HBFT_ASW_Status_Cx0_Init), 1=Cx1_InfoStufe_aktiv (CM_SSA_HBFT_ASW_Status_Cx1_InfoStufe_aktiv), 2=Cx2_Warnstufe_aktiv (CM_SSA_HBFT_ASW_Status_Cx2_Warnstufe_aktiv)}, range raw 0..2  # SmartSensorActor: Rückmeldung des Status der ASW Anzyeige.
          signal HBFS_Status_eTAG_ext_XIX_TSG_HBFS_02_XIX_E3V_K2CANFD: start 60, 3 bit, little-endian, data-type-policy=OVERRIDE, i-signal-type=PRIMITIVE, init-value=3, base-type=BT_HBFS_Status_eTAG_ext, invalid-value=Invalid_HBFS_Status_eTAG_ext_XIX_TSG_HBFS_02_XIX_E3V_K2CANFD:4, compu {0=Cx0_Griff_eingefahren (CM_HBFS_Status_eTAG_ext_Cx0_Griff_eingefahren), 1=Cx1_Griff_ausgefahren (CM_HBFS_Status_eTAG_ext_Cx1_Griff_ausgefahren), 2=Cx2_Griff_verfaehrt (CM_HBFS_Status_eTAG_ext_Cx2_Griff_verfaehrt), 3=Cx3_init (CM_HBFS_Status_eTAG_ext_Cx3_init), 4=Cx4_Fehler (CM_HBFS_Status_eTAG_ext_Cx4_Fehler)}, range raw 0..4  # HBFS Status eTAG erweitert um den Wert "Griff verfaehrt"
          signal HBFS_TCR_Mode_aktiv_XIX_TSG_HBFS_02_XIX_E3V_K2CANFD: start 63, 1 bit, little-endian, data-type-policy=OVERRIDE, i-signal-type=PRIMITIVE, base-type=BT_HBFS_TCR_Mode_aktiv, compu {0=Cx0_TCR_Mode_deaktiv (CM_HBFS_TCR_Mode_aktiv_Cx0_TCR_Mode_deaktiv), 1=Cx1_TCR_Mode_aktiv (CM_HBFS_TCR_Mode_aktiv_Cx1_TCR_Mode_aktiv)}, range raw 0..1  # Signal zeigt eine aktive mechanische Redundanz am Türschloss an.
          mapping SG_TSG_HBFS_02_XIX_E3V_K2CANFD: i-signal-group=SG_TSG_HBFS_02_XIX_E3V_K2CANFD, transfer-property=TRIGGERED-WITHOUT-REPETITION
      frame TSG_HFS_01_XIX_E3V_K2CANFD: id 0x3CE, from SAM, to SAM, frame-length=8, can-addressing-mode=STANDARD, can-frame-rx-behavior=CAN-FD, can-frame-tx-behavior=CAN-FD
        pdu TSG_HFS_01_XIX_E3V_K2CANFD: length=8, minimum-delay=0.02, transmission-mode-true-timing={cyclic-timing={time-offset=0.0, time-period=0.1}, event-controlled-timing={number-of-repetitions=0, repetition-period=0.0}}, unused-bit-pattern=0
          signal HFS_Tuer_geoeffnet_XIX_TSG_HFS_01_XIX_E3V_K2CANFD: start 0, 1 bit, little-endian, data-type-policy=OVERRIDE, i-signal-type=PRIMITIVE, init-value=0, base-type=BT_HFS_Tuer_geoeffnet, compu {0=Cx0_geschlossen (CM_HFS_Tuer_geoeffnet_Cx0_geschlossen), 1=Cx1_offen (CM_HFS_Tuer_geoeffnet_Cx1_offen)}, range raw 0..1, transfer-property=TRIGGERED-ON-CHANGE-WITHOUT-REPETITION, to SAM(timeout 1 s)  # HFS Tuer geoeffnet
          signal HFS_verriegelt_XIX_TSG_HFS_01_XIX_E3V_K2CANFD: start 1, 1 bit, little-endian, data-type-policy=OVERRIDE, i-signal-type=PRIMITIVE, init-value=0, base-type=BT_HFS_verriegelt, compu {0=Cx0_nicht_verriegelt (CM_HFS_verriegelt_Cx0_nicht_verriegelt), 1=Cx1_verriegelt (CM_HFS_verriegelt_Cx1_verriegelt)}, range raw 0..1, transfer-property=TRIGGERED-ON-CHANGE-WITHOUT-REPETITION  # HFS Tuer verriegelt
          signal HFS_gesafet_XIX_TSG_HFS_01_XIX_E3V_K2CANFD: start 2, 1 bit, little-endian, data-type-policy=OVERRIDE, i-signal-type=PRIMITIVE, init-value=0, base-type=BT_HFS_gesafet, compu {0=Cx0_nicht_gesafet (CM_HFS_gesafet_Cx0_nicht_gesafet), 1=Cx1_gesafet (CM_HFS_gesafet_Cx1_gesafet)}, range raw 0..1, transfer-property=TRIGGERED-ON-CHANGE-WITHOUT-REPETITION  # HFS Tuer gesafet. Im Zustand Safe wird auch das Signal HFS_verriegelt = 1 gesendet.
          signal HFS_Heckrollotaster_betaetigt_XIX_TSG_HFS_01_XIX_E3V_K2CANFD: start 3, 1 bit, little-endian, data-type-policy=OVERRIDE, i-signal-type=PRIMITIVE, init-value=0, base-type=BT_HFS_Heckrollotaster_betaetigt, compu {0=Cx0_keine_Verfahranweisung_in_Richtung_Hoch (CM_HFS_Heckrollotaster_betaetigt_Cx0_keine_Verfahranweisung_in_Richtung_Hoch), 1=Cx1_In_Richtung_Hoch_Verfahren (CM_HFS_Heckrollotaster_betaetigt_Cx1_In_Richtung_Hoch_Verfahren)}, range raw 0..1, transfer-property=TRIGGERED-ON-CHANGE-WITHOUT-REPETITION  # Verfahren des Heckrollos in Richtung Hoch Bei Einfachtaster wird Bit als Togglebit verwendet (Heckrollo hoch, tief)
          signal HFS_Tuerschloss_defekt_XIX_TSG_HFS_01_XIX_E3V_K2CANFD: start 4, 1 bit, little-endian, data-type-policy=OVERRIDE, i-signal-type=PRIMITIVE, base-type=BT_HFS_Tuerschloss_defekt, compu {0=Cx0_Tuerschloss_funktionsfaehig (CM_HFS_Tuerschloss_defekt_Cx0_Tuerschloss_funktionsfaehig), 1=Cx1_Tuerschloss_defekt (CM_HFS_Tuerschloss_defekt_Cx1_Tuerschloss_defekt)}, range raw 0..1, transfer-property=PENDING  # Das hintere Tuerschloss auf der Fahrerseite ist nicht mehr funktionsfähig.
          signal HFS_Unlock_Taster_XIX_TSG_HFS_01_XIX_E3V_K2CANFD: start 5, 1 bit, little-endian, data-type-policy=OVERRIDE, i-signal-type=PRIMITIVE, init-value=0, base-type=BT_HFS_Unlock_Taster, compu {0=Cx0_nicht_betaetigt (CM_HFS_Unlock_Taster_Cx0_nicht_betaetigt), 1=Cx1_betaetigt (CM_HFS_Unlock_Taster_Cx1_betaetigt)}, range raw 0..1, transfer-property=TRIGGERED-ON-CHANGE-WITHOUT-REPETITION  # Betaetigung Unlock Taster
          signal HFS_Lock_Taster_XIX_TSG_HFS_01_XIX_E3V_K2CANFD: start 6, 1 bit, little-endian, data-type-policy=OVERRIDE, i-signal-type=PRIMITIVE, init-value=0, base-type=BT_HFS_Lock_Taster, compu {0=Cx0_nicht_betaetigt (CM_HFS_Lock_Taster_Cx0_nicht_betaetigt), 1=Cx1_betaetigt (CM_HFS_Lock_Taster_Cx1_betaetigt)}, range raw 0..1, transfer-property=TRIGGERED-ON-CHANGE-WITHOUT-REPETITION  # Betätigung Lock-Taster
          signal HFS_Sperrklinke_XIX_TSG_HFS_01_XIX_E3V_K2CANFD: start 7, 1 bit, little-endian, data-type-policy=OVERRIDE, i-signal-type=PRIMITIVE, init-value=0, base-type=BT_HFS_Sperrklinke, compu {0=Cx0_Schloss_in_Vorraste_und_Hauptraste (CM_HFS_Sperrklinke_Cx0_Schloss_in_Vorraste_und_Hauptraste), 1=Cx1_Tuer_auf_oder_Tuer_Position_zwischen_Vor_und_Hauptraste (CM_HFS_Sperrklinke_Cx1_Tuer_auf_oder_Tuer_Position_zwischen_Vor_und_Hauptraste)}, range raw 0..1, transfer-property=TRIGGERED-ON-CHANGE-WITHOUT-REPETITION  # Vorraste für Schloß zwischen Vor- und Hauptraste Signal kurz auf 1, danach wieder auf 0 wenn Tür in Hauptraste (Tür ist sicher zu wenn Sperrklinke und Türkontakt auf 0 sind)
          signal HFS_TAG_betaetigt_XIX_TSG_HFS_01_XIX_E3V_K2CANFD: start 8, 1 bit, little-endian, data-type-policy=OVERRIDE, i-signal-type=PRIMITIVE, init-value=0, base-type=BT_HFS_TAG_betaetigt, compu {0=Cx0_nicht_betaetigt (CM_HFS_TAG_betaetigt_Cx0_nicht_betaetigt), 1=Cx1_betaetigt (CM_HFS_TAG_betaetigt_Cx1_betaetigt)}, range raw 0..1, transfer-property=TRIGGERED-ON-CHANGE-WITHOUT-REPETITION  # Betaetigung Türaussengriff
          signal HFS_TIG_betaetigt_XIX_TSG_HFS_01_XIX_E3V_K2CANFD: start 9, 1 bit, little-endian, data-type-policy=OVERRIDE, i-signal-type=PRIMITIVE, init-value=0, base-type=BT_HFS_TIG_betaetigt, compu {0=Cx0_nicht_betaetigt (CM_HFS_TIG_betaetigt_Cx0_nicht_betaetigt), 1=Cx1_betaetigt (CM_HFS_TIG_betaetigt_Cx1_betaetigt)}, range raw 0..1, transfer-property=TRIGGERED-ON-CHANGE-WITHOUT-REPETITION, to SAM(timeout 1 s)  # Betaetigung Türinnengriff
          signal HFS_FH_S_HBFS_AutoHoch_XIX_TSG_HFS_01_XIX_E3V_K2CANFD: start 10, 1 bit, little-endian, data-type-policy=OVERRIDE, i-signal-type=PRIMITIVE, init-value=0, base-type=BT_HFS_FH_S_HBFS_AutoHoch, compu {0=Cx0_keine_Bedienung (CM_HFS_FH_S_HBFS_AutoHoch_Cx0_keine_Bedienung), 1=Cx1_Automatiklauf_Angefordert (CM_HFS_FH_S_HBFS_AutoHoch_Cx1_Automatiklauf_Angefordert)}, range raw 0..1, transfer-property=TRIGGERED-ON-CHANGE-WITHOUT-REPETITION  # Automatisches Hochfahren der Seitenscheibe HBFS
          signal HFS_FH_S_HBFS_AutoTief_XIX_TSG_HFS_01_XIX_E3V_K2CANFD: start 11, 1 bit, little-endian, data-type-policy=OVERRIDE, i-signal-type=PRIMITIVE, init-value=0, base-type=BT_HFS_FH_S_HBFS_AutoTief, compu {0=Cx0_keine_Bedienung (CM_HFS_FH_S_HBFS_AutoTief_Cx0_keine_Bedienung), 1=Cx1_Automatiklauf_Angefordert (CM_HFS_FH_S_HBFS_AutoTief_Cx1_Automatiklauf_Angefordert)}, range raw 0..1, transfer-property=TRIGGERED-ON-CHANGE-WITHOUT-REPETITION  # Automatisches Absenken der Seitenscheibe HBFS
          signal HFS_FH_S_HBFS_ManHoch_XIX_TSG_HFS_01_XIX_E3V_K2CANFD: start 12, 1 bit, little-endian, data-type-policy=OVERRIDE, i-signal-type=PRIMITIVE, init-value=0, base-type=BT_HFS_FH_S_HBFS_ManHoch, compu {0=Cx0_keine_Bedienung (CM_HFS_FH_S_HBFS_ManHoch_Cx0_keine_Bedienung), 1=Cx1_Manueller_Lauf_Angefordert (CM_HFS_FH_S_HBFS_ManHoch_Cx1_Manueller_Lauf_Angefordert)}, range raw 0..1, transfer-property=TRIGGERED-ON-CHANGE-WITHOUT-REPETITION  # Manuelles Hochfahren der Seitenscheibe HBFS
          signal HFS_FH_S_HBFS_ManTief_XIX_TSG_HFS_01_XIX_E3V_K2CANFD: start 13, 1 bit, little-endian, data-type-policy=OVERRIDE, i-signal-type=PRIMITIVE, init-value=0, base-type=BT_HFS_FH_S_HBFS_ManTief, compu {0=Cx0_keine_Bedienung (CM_HFS_FH_S_HBFS_ManTief_Cx0_keine_Bedienung), 1=Cx1_Manueller_Lauf_Angefordert (CM_HFS_FH_S_HBFS_ManTief_Cx1_Manueller_Lauf_Angefordert)}, range raw 0..1, transfer-property=TRIGGERED-ON-CHANGE-WITHOUT-REPETITION  # Manuelles Absenken der Seitenscheibe HBFS
          signal HFS_Tuer_Status_XIX_TSG_HFS_01_XIX_E3V_K2CANFD: start 14, 2 bit, little-endian, data-type-policy=OVERRIDE, i-signal-type=PRIMITIVE, init-value=0, base-type=BT_HFS_Tuer_Status, invalid-value=Invalid_HFS_Tuer_Status_XIX_TSG_HFS_01_XIX_E3V_K2CANFD:3, compu {0=Cx0_Init (CM_HFS_Tuer_Status_Cx0_Init), 1=Cx1_Tuer_geschlossen (CM_HFS_Tuer_Status_Cx1_Tuer_geschlossen), 2=Cx2_Tuer_offen (CM_HFS_Tuer_Status_Cx2_Tuer_offen), 3=Cx3_Fehler (CM_HFS_Tuer_Status_Cx3_Fehler)}, range raw 0..3, transfer-property=TRIGGERED-ON-CHANGE-WITHOUT-REPETITION  # Türstatus mit Fehler und Initwert
          signal HFS_SAD_Schalter_XIX_TSG_HFS_01_XIX_E3V_K2CANFD: start 16, 4 bit, little-endian, data-type-policy=OVERRIDE, i-signal-type=PRIMITIVE, init-value=14, base-type=BT_HFS_SAD_Schalter, invalid-value=Invalid_HFS_SAD_Schalter_XIX_TSG_HFS_01_XIX_E3V_K2CANFD:15, compu {0=Cx0_nicht_betaetigt (CM_HFS_SAD_Schalter_Cx0_nicht_betaetigt), 5=Cx5_AUF_manuell (CM_HFS_SAD_Schalter_Cx5_AUF_manuell), 6=Cx6_AUF_automatik (CM_HFS_SAD_Schalter_Cx6_AUF_automatik), 7=Cx7_ZU_manuell (CM_HFS_SAD_Schalter_Cx7_ZU_manuell), 8=Cx8_ZU_automatik (CM_HFS_SAD_Schalter_Cx8_ZU_automatik), 13=Cxd_nicht_verfuegbar (CM_HFS_SAD_Schalter_Cxd_nicht_verfuegbar), 14=Cxe_Init (CM_HFS_SAD_Schalter_Cxe_Init), 15=Cxf_Fehler (CM_HFS_SAD_Schalter_Cxf_Fehler)}, range raw 0..15, transfer-property=TRIGGERED-ON-CHANGE-WITHOUT-REPETITION  # | Ausstelldach MD3 ----------------------------- 0 | nicht_betaetigt 1 | 2 | 3 | 4 | 5 | (m) Auf 6 | (a) Auf 7 | (m) Zu 8 | (a) Zu 13| Schalter nicht verfuegbar 14| Init 15| Fehlerfall
          signal HFS_FH_S_ManHoch_XIX_TSG_HFS_01_XIX_E3V_K2CANFD: start 20, 1 bit, little-endian, data-type-policy=OVERRIDE, i-signal-type=PRIMITIVE, init-value=0, base-type=BT_HFS_FH_S_ManHoch, compu {0=Cx0_nicht_betaetigt (CM_HFS_FH_S_ManHoch_Cx0_nicht_betaetigt), 1=Cx1_betaetigt (CM_HFS_FH_S_ManHoch_Cx1_betaetigt)}, range raw 0..1, transfer-property=TRIGGERED-ON-CHANGE-WITHOUT-REPETITION, to SAM(timeout 1 s)  # Betaetigung FH Schalter man hoch
          signal HFS_FH_S_AutoHoch_XIX_TSG_HFS_01_XIX_E3V_K2CANFD: start 21, 1 bit, little-endian, data-type-policy=OVERRIDE, i-signal-type=PRIMITIVE, init-value=0, base-type=BT_HFS_FH_S_AutoHoch, compu {0=Cx0_nicht_betaetigt (CM_HFS_FH_S_AutoHoch_Cx0_nicht_betaetigt), 1=Cx1_betaetigt (CM_HFS_FH_S_AutoHoch_Cx1_betaetigt)}, range raw 0..1, transfer-property=TRIGGERED-ON-CHANGE-WITHOUT-REPETITION, to SAM(timeout 1 s)  # Betaetigung FH Schalter auto hoch
          signal HFS_FH_S_ManTief_XIX_TSG_HFS_01_XIX_E3V_K2CANFD: start 22, 1 bit, little-endian, data-type-policy=OVERRIDE, i-signal-type=PRIMITIVE, init-value=0, base-type=BT_HFS_FH_S_ManTief, compu {0=Cx0_nicht_betaetigt (CM_HFS_FH_S_ManTief_Cx0_nicht_betaetigt), 1=Cx1_betaetigt (CM_HFS_FH_S_ManTief_Cx1_betaetigt)}, range raw 0..1, transfer-property=TRIGGERED-ON-CHANGE-WITHOUT-REPETITION, to SAM(timeout 1 s)  # Betaetigung FH Schalter man tief
          signal HFS_FH_S_AutoTief_XIX_TSG_HFS_01_XIX_E3V_K2CANFD: start 23, 1 bit, little-endian, data-type-policy=OVERRIDE, i-signal-type=PRIMITIVE, init-value=0, base-type=BT_HFS_FH_S_AutoTief, compu {0=Cx0_nicht_betaetigt (CM_HFS_FH_S_AutoTief_Cx0_nicht_betaetigt), 1=Cx1_betaetigt (CM_HFS_FH_S_AutoTief_Cx1_betaetigt)}, range raw 0..1, transfer-property=TRIGGERED-ON-CHANGE-WITHOUT-REPETITION, to SAM(timeout 1 s)  # Betaetigung FH Schalter auto tief
          signal HFS_FH_Oeffnung_XIX_TSG_HFS_01_XIX_E3V_K2CANFD: start 24, 8 bit, little-endian, data-type-policy=OVERRIDE, i-signal-type=PRIMITIVE, init-value=0, base-type=BT_HFS_FH_Oeffnung, compu {phys=raw*0.5 for raw 0..200; unit Unit_PerCent}, range phys 0..100 Unit_PerCent, raw 0..200, unit=Unit_PerCent, transfer-property=TRIGGERED-ON-CHANGE-WITHOUT-REPETITION  # Gibt den Fensteröffnungswert in % an.
          signal HFS_FH_Bew_hoch_XIX_TSG_HFS_01_XIX_E3V_K2CANFD: start 32, 1 bit, little-endian, data-type-policy=OVERRIDE, i-signal-type=PRIMITIVE, init-value=0, base-type=BT_HFS_FH_Bew_hoch, compu {0=Cx0_inaktiv (CM_HFS_FH_Bew_hoch_Cx0_inaktiv), 1=Cx1_aktiv (CM_HFS_FH_Bew_hoch_Cx1_aktiv)}, range raw 0..1, transfer-property=TRIGGERED-ON-CHANGE-WITHOUT-REPETITION  # HFS Fenster bewegt sich in Richtung hoch
          signal HFS_FH_Bew_tief_XIX_TSG_HFS_01_XIX_E3V_K2CANFD: start 33, 1 bit, little-endian, data-type-policy=OVERRIDE, i-signal-type=PRIMITIVE, init-value=0, base-type=BT_HFS_FH_Bew_tief, compu {0=Cx0_inaktiv (CM_HFS_FH_Bew_tief_Cx0_inaktiv), 1=Cx1_aktiv (CM_HFS_FH_Bew_tief_Cx1_aktiv)}, range raw 0..1, transfer-property=TRIGGERED-ON-CHANGE-WITHOUT-REPETITION  # HFS Fenster bewegt sich in Richtung tief
          signal HFS_FH_Fang_XIX_TSG_HFS_01_XIX_E3V_K2CANFD: start 34, 1 bit, little-endian, data-type-policy=OVERRIDE, i-signal-type=PRIMITIVE, init-value=0, base-type=BT_HFS_FH_Fang, compu {0=Cx0_ausserhalb_Fangbereich (CM_HFS_FH_Fang_Cx0_ausserhalb_Fangbereich), 1=Cx1_innerhalb_Fangbereich (CM_HFS_FH_Fang_Cx1_innerhalb_Fangbereich)}, range raw 0..1, transfer-property=TRIGGERED-ON-CHANGE-WITHOUT-REPETITION  # Fangbereich ist 4mm von oberer Lippendichtung
          signal HFS_FH_Block_XIX_TSG_HFS_01_XIX_E3V_K2CANFD: start 35, 1 bit, little-endian, data-type-policy=OVERRIDE, i-signal-type=PRIMITIVE, init-value=0, base-type=BT_HFS_FH_Block, compu {0=Cx0_inaktiv (CM_HFS_FH_Block_Cx0_inaktiv), 1=Cx1_aktiv (CM_HFS_FH_Block_Cx1_aktiv)}, range raw 0..1, transfer-property=TRIGGERED-ON-CHANGE-WITHOUT-REPETITION  # Fensterscheibe befindet sich im mechanischen Block (oben oder unten)
          signal HFS_FH_Thermo_XIX_TSG_HFS_01_XIX_E3V_K2CANFD: start 36, 1 bit, little-endian, data-type-policy=OVERRIDE, i-signal-type=PRIMITIVE, init-value=0, base-type=BT_HFS_FH_Thermo, compu {0=Cx0_inaktiv (CM_HFS_FH_Thermo_Cx0_inaktiv), 1=Cx1_aktiv (CM_HFS_FH_Thermo_Cx1_aktiv)}, range raw 0..1, transfer-property=TRIGGERED-ON-CHANGE-WITHOUT-REPETITION  # gibt an ob Fensterheber im Thermoschutz ist
          signal HFS_UEKB_aktiviert_XIX_TSG_HFS_01_XIX_E3V_K2CANFD: start 37, 1 bit, little-endian, data-type-policy=OVERRIDE, i-signal-type=PRIMITIVE, init-value=0, base-type=BT_HFS_UEKB_aktiviert, compu {0=Cx0_inaktiv (CM_HFS_UEKB_aktiviert_Cx0_inaktiv), 1=Cx1_aktiv (CM_HFS_UEKB_aktiviert_Cx1_aktiv)}, range raw 0..1, transfer-property=TRIGGERED-ON-CHANGE-WITHOUT-REPETITION  # Überschutzbegrenzungskraft bei Reversieren
          signal HFS_Tueroeffnen_Warnung_XIX_TSG_HFS_01_XIX_E3V_K2CANFD: start 38, 1 bit, little-endian, data-type-policy=OVERRIDE, i-signal-type=PRIMITIVE, init-value=0, base-type=BT_HFS_Tueroeffnen_Warnung, compu {0=Cx0_Tuerwarnung_nicht_aktiv (CM_HFS_Tueroeffnen_Warnung_Cx0_Tuerwarnung_nicht_aktiv), 1=Cx1_Tuerwarnung_aktiv (CM_HFS_Tueroeffnen_Warnung_Cx1_Tuerwarnung_aktiv)}, range raw 0..1, transfer-property=TRIGGERED-ON-CHANGE-WITHOUT-REPETITION  # Bit wird gesetzt, wenn Tür während der Fahrt geoeffnet werden soll.
          signal HFS_FH_normiert_XIX_TSG_HFS_01_XIX_E3V_K2CANFD: start 39, 1 bit, little-endian, data-type-policy=OVERRIDE, i-signal-type=PRIMITIVE, init-value=0, base-type=BT_HFS_FH_normiert, compu {0=Cx0_inaktiv (CM_HFS_FH_normiert_Cx0_inaktiv), 1=Cx1_aktiv (CM_HFS_FH_normiert_Cx1_aktiv)}, range raw 0..1, transfer-property=TRIGGERED-ON-CHANGE-WITHOUT-REPETITION  # Die Position der Fensterheberscheibe ist bekannt.
          signal ASW_Warnung_aktiv_HFS_XIX_TSG_HFS_01_XIX_E3V_K2CANFD: start 40, 1 bit, little-endian, data-type-policy=OVERRIDE, i-signal-type=PRIMITIVE, init-value=0, base-type=BT_ASW_Warnung_aktiv_HFS, compu {0=Cx0_nicht_angefordert (CM_ASW_Warnung_aktiv_HFS_Cx0_nicht_angefordert), 1=Cx1_angefordert (CM_ASW_Warnung_aktiv_HFS_Cx1_angefordert)}, range raw 0..1, transfer-property=TRIGGERED-ON-CHANGE-WITHOUT-REPETITION, to SAM(timeout 1 s)  # Abschaltung der Ambientefunktion Tür hinten der Fahrerseite bei aktiver ASW Warnung an der Fahrertür
          signal HFS_Zuziehhilfe_aktiv_XIX_TSG_HFS_01_XIX_E3V_K2CANFD: start 41, 1 bit, little-endian, data-type-policy=OVERRIDE, i-signal-type=PRIMITIVE, init-value=0, base-type=BT_HFS_Zuziehhilfe_aktiv, compu {0=Cx0_Init (CM_HFS_Zuziehhilfe_aktiv_Cx0_Init), 1=Cx1_Zuziehhilfe_aktiv (CM_HFS_Zuziehhilfe_aktiv_Cx1_Zuziehhilfe_aktiv)}, range raw 0..1, transfer-property=TRIGGERED-ON-CHANGE-WITHOUT-REPETITION  # Zuziehhilfe aktiv
          signal HFS_Seitenrollo_hoch_XIX_TSG_HFS_01_XIX_E3V_K2CANFD: start 42, 1 bit, little-endian, data-type-policy=OVERRIDE, i-signal-type=PRIMITIVE, init-value=0, base-type=BT_HFS_Seitenrollo_hoch, compu {0=Cx0_Init (CM_HFS_Seitenrollo_hoch_Cx0_Init), 1=Cx1_Seitenrollo_in_Bewegung_hoch (CM_HFS_Seitenrollo_hoch_Cx1_Seitenrollo_in_Bewegung_hoch)}, range raw 0..1, transfer-property=TRIGGERED-ON-CHANGE-WITHOUT-REPETITION  # Seitenrollo in Bewegung Richtung hoch
          signal HFS_Seitenrollo_tief_XIX_TSG_HFS_01_XIX_E3V_K2CANFD: start 43, 1 bit, little-endian, data-type-policy=OVERRIDE, i-signal-type=PRIMITIVE, init-value=0, base-type=BT_HFS_Seitenrollo_tief, compu {0=Cx0_Init (CM_HFS_Seitenrollo_tief_Cx0_Init), 1=Cx1_Seitenrollo_in_Bewegung_tief (CM_HFS_Seitenrollo_tief_Cx1_Seitenrollo_in_Bewegung_tief)}, range raw 0..1, transfer-property=TRIGGERED-ON-CHANGE-WITHOUT-REPETITION  # Seitenrollo in Bewegung Richtung tief
          signal HFS_Status_KiSi_XIX_TSG_HFS_01_XIX_E3V_K2CANFD: start 44, 1 bit, little-endian, data-type-policy=OVERRIDE, i-signal-type=PRIMITIVE, init-value=0, base-type=BT_HFS_Status_KiSi, compu {0=Cx0_inaktiv (CM_HFS_Status_KiSi_Cx0_inaktiv), 1=Cx1_aktiv (CM_HFS_Status_KiSi_Cx1_aktiv)}, range raw 0..1, transfer-property=TRIGGERED-ON-CHANGE-WITHOUT-REPETITION, to SAM(timeout 1 s)  # Status Kindersicherung hinten Fahrerseite
          signal SSR_HFS_Pos_Unten_XIX_TSG_HFS_01_XIX_E3V_K2CANFD: start 45, 1 bit, little-endian, data-type-policy=OVERRIDE, i-signal-type=PRIMITIVE, init-value=0, base-type=BT_SSR_HFS_Pos_Unten, compu {0=Cx0_SSR_Oben (CM_SSR_HFS_Pos_Unten_Cx0_SSR_Oben), 1=Cx1_SSR_Unten (CM_SSR_HFS_Pos_Unten_Cx1_SSR_Unten)}, range raw 0..1, transfer-property=PENDING  # Signal für die "Global Close". Über dieses Bit wissen die anderen TSGs, ob der SSR oder der FH verfahren werden darf.
          signal HFS_Oben_Block_erw_XIX_TSG_HFS_01_XIX_E3V_K2CANFD: start 46, 1 bit, little-endian, data-type-policy=OVERRIDE, i-signal-type=PRIMITIVE, init-value=0, base-type=BT_HFS_Oben_Block_erw, compu {0=Cx0_Fensterheber_nicht_in_Blockerwar (CM_HFS_Oben_Block_erw_Cx0_Fensterheber_nicht_in_Blockerwar), 1=Cx1_Fensterheber_in_Blockerwartung_o (CM_HFS_Oben_Block_erw_Cx1_Fensterheber_in_Blockerwartung_o)}, range raw 0..1, transfer-property=TRIGGERED-ON-CHANGE-WITHOUT-REPETITION  # Fensterheber in Blockerwartung oben
          signal HFS_Unten_Block_erw_XIX_TSG_HFS_01_XIX_E3V_K2CANFD: start 47, 1 bit, little-endian, data-type-policy=OVERRIDE, i-signal-type=PRIMITIVE, init-value=0, base-type=BT_HFS_Unten_Block_erw, compu {0=Cx0_Fensterheber_nicht_in_Blockerwar (CM_HFS_Unten_Block_erw_Cx0_Fensterheber_nicht_in_Blockerwar), 1=Cx1_Fensterheber_in_Blockerwartung_u (CM_HFS_Unten_Block_erw_Cx1_Fensterheber_in_Blockerwartung_u)}, range raw 0..1, transfer-property=TRIGGERED-ON-CHANGE-WITHOUT-REPETITION  # Fensterheber in Blockerwartung unten
          signal MTHFS_M_Taste_XIX_TSG_HFS_01_XIX_E3V_K2CANFD: start 48, 1 bit, little-endian, data-type-policy=OVERRIDE, i-signal-type=PRIMITIVE, init-value=0, base-type=BT_MTHFS_M_Taste, compu {0=Cx0_nicht_betaetigt (CM_MTHFS_M_Taste_Cx0_nicht_betaetigt), 1=Cx1_betaetigt (CM_MTHFS_M_Taste_Cx1_betaetigt)}, range raw 0..1, transfer-property=TRIGGERED-ON-CHANGE-WITHOUT-REPETITION  # Betätigung M-Taste HFS
          signal MTHFS_Pos1_XIX_TSG_HFS_01_XIX_E3V_K2CANFD: start 49, 1 bit, little-endian, data-type-policy=OVERRIDE, i-signal-type=PRIMITIVE, init-value=0, base-type=BT_MTHFS_Pos1, compu {0=Cx0_nicht_betaetigt (CM_MTHFS_Pos1_Cx0_nicht_betaetigt), 1=Cx1_betaetigt (CM_MTHFS_Pos1_Cx1_betaetigt)}, range raw 0..1, transfer-property=TRIGGERED-ON-CHANGE-WITHOUT-REPETITION  # Betätigung Postionstaste 1 HFS
          signal MTHFS_Pos2_XIX_TSG_HFS_01_XIX_E3V_K2CANFD: start 50, 1 bit, little-endian, data-type-policy=OVERRIDE, i-signal-type=PRIMITIVE, init-value=0, base-type=BT_MTHFS_Pos2, compu {0=Cx0_nicht_betaetigt (CM_MTHFS_Pos2_Cx0_nicht_betaetigt), 1=Cx1_betaetigt (CM_MTHFS_Pos2_Cx1_betaetigt)}, range raw 0..1, transfer-property=TRIGGERED-ON-CHANGE-WITHOUT-REPETITION  # Betätigung Postionstaste 2 HFS
          signal MTHFS_Pos3_XIX_TSG_HFS_01_XIX_E3V_K2CANFD: start 51, 1 bit, little-endian, data-type-policy=OVERRIDE, i-signal-type=PRIMITIVE, init-value=0, base-type=BT_MTHFS_Pos3, compu {0=Cx0_nicht_betaetigt (CM_MTHFS_Pos3_Cx0_nicht_betaetigt), 1=Cx1_betaetigt (CM_MTHFS_Pos3_Cx1_betaetigt)}, range raw 0..1, transfer-property=TRIGGERED-ON-CHANGE-WITHOUT-REPETITION  # Betätigung Postionstaste 3 HFS
          signal HFS_MRollo_Schalter_XIX_TSG_HFS_01_XIX_E3V_K2CANFD: start 52, 3 bit, little-endian, data-type-policy=OVERRIDE, i-signal-type=PRIMITIVE, init-value=6, base-type=BT_HFS_MRollo_Schalter, invalid-value=Invalid_HFS_MRollo_Schalter_XIX_TSG_HFS_01_XIX_E3V_K2CANFD:7, compu {0=Cx0_nicht_betaetigt (CM_HFS_MRollo_Schalter_Cx0_nicht_betaetigt), 1=Cx1_ZU_manuell (CM_HFS_MRollo_Schalter_Cx1_ZU_manuell), 2=Cx2_ZU_automatik (CM_HFS_MRollo_Schalter_Cx2_ZU_automatik), 3=Cx3_AUF_manuell (CM_HFS_MRollo_Schalter_Cx3_AUF_manuell), 4=Cx4_AUF_automatik (CM_HFS_MRollo_Schalter_Cx4_AUF_automatik), 5=Cx5_nicht_verfuegbar (CM_HFS_MRollo_Schalter_Cx5_nicht_verfuegbar), 6=Cx6_Init (CM_HFS_MRollo_Schalter_Cx6_Init), 7=Cx7_Fehler (CM_HFS_MRollo_Schalter_Cx7_Fehler)}, range raw 0..7, transfer-property=TRIGGERED-ON-CHANGE-WITHOUT-REPETITION  # | MRollo2 ----------------------------- 0 | nicht_betaetigt 1 | (m) Zu 2 | (a) Zu 3 | (m) Auf 4 | (a) Auf 5 | Schalter nicht verfuegbar 6 | Init 7 | Fehlerfall
          signal HFS_Lock_Taster_inv_XIX_TSG_HFS_01_XIX_E3V_K2CANFD: start 55, 1 bit, little-endian, data-type-policy=OVERRIDE, i-signal-type=PRIMITIVE, init-value=0, base-type=BT_HFS_Lock_Taster_inv, compu {0=Cx0_Lock_Taster_betaetgit (CM_HFS_Lock_Taster_inv_Cx0_Lock_Taster_betaetgit) (Lock Taster betätgit), 1=Cx1_Lock_Taster_nicht_betaetigt (CM_HFS_Lock_Taster_inv_Cx1_Lock_Taster_nicht_betaetigt) (Lock Taster nicht betätigt)}, range raw 0..1, transfer-property=TRIGGERED-ON-CHANGE-WITHOUT-REPETITION  # Lock Taster nicht betätigt
          signal HFS_Status_eTAG_XIX_TSG_HFS_01_XIX_E3V_K2CANFD: start 56, 2 bit, little-endian, data-type-policy=OVERRIDE, i-signal-type=PRIMITIVE, init-value=0, base-type=BT_HFS_Status_eTAG, invalid-value=Invalid_HFS_Status_eTAG_XIX_TSG_HFS_01_XIX_E3V_K2CANFD:3, compu {0=Cx0_Init (CM_HFS_Status_eTAG_Cx0_Init), 1=Cx1_Griff_ausgefahren (CM_HFS_Status_eTAG_Cx1_Griff_ausgefahren), 2=Cx2_Griff_eingefahren (CM_HFS_Status_eTAG_Cx2_Griff_eingefahren), 3=Cx3_Fehler (CM_HFS_Status_eTAG_Cx3_Fehler)}, range raw 0..3, transfer-property=TRIGGERED-ON-CHANGE-WITHOUT-REPETITION  # Status des elektrischen Tueraussengriffes Tuer Fahrerseite hinten
          signal HFS_Tuer_Status_QBit_XIX_TSG_HFS_01_XIX_E3V_K2CANFD: start 58, 1 bit, little-endian, data-type-policy=OVERRIDE, i-signal-type=PRIMITIVE, base-type=BT_HFS_Tuer_Status_QBit, compu {0=Cx0_Status_Tuerkontakt_sicher (CM_HFS_Tuer_Status_QBit_Cx0_Status_Tuerkontakt_sicher), 1=Cx1_Status_Tuerkontakt_unsicher (CM_HFS_Tuer_Status_QBit_Cx1_Status_Tuerkontakt_unsicher)}, range raw 0..1, transfer-property=PENDING  # Dieses Bit gibt die Zuverlässigkeit des Türkontakts an. Ein auf dieses Bit folgender Fehlereintrag ist mit dem Sender des Bits abzustimmen (gültig ab PPE).
          signal HFS_TCR_Mode_aktiv_XIX_TSG_HFS_01_XIX_E3V_K2CANFD: start 59, 1 bit, little-endian, data-type-policy=OVERRIDE, i-signal-type=PRIMITIVE, init-value=0, base-type=BT_HFS_TCR_Mode_aktiv, compu {0=Cx0_TCR_Mode_deaktiv (CM_HFS_TCR_Mode_aktiv_Cx0_TCR_Mode_deaktiv), 1=Cx1_TCR_Mode_aktiv (CM_HFS_TCR_Mode_aktiv_Cx1_TCR_Mode_aktiv)}, range raw 0..1, transfer-property=TRIGGERED-ON-CHANGE-WITHOUT-REPETITION  # Signal zeigt eine aktive mechanische Redundanz am Türschloss an.
          signal HFS_TIG_betaetigt_schliessen_XIX_TSG_HFS_01_XIX_E3V_K2CANFD: start 60, 1 bit, little-endian, data-type-policy=OVERRIDE, i-signal-type=PRIMITIVE, init-value=0, base-type=BT_HFS_TIG_betaetigt_schliessen, compu {0=Cx0_nicht_betaetigt (CM_HFS_TIG_betaetigt_schliessen_Cx0_nicht_betaetigt), 1=Cx1_betaetigt (CM_HFS_TIG_betaetigt_schliessen_Cx1_betaetigt)}, range raw 0..1, transfer-property=TRIGGERED-ON-CHANGE-WITHOUT-REPETITION  # Türinnenbetätigung, Taster Tür schließen.
          signal HFS_TIG_betaetigt_oeffnen_XIX_TSG_HFS_01_XIX_E3V_K2CANFD: start 61, 1 bit, little-endian, data-type-policy=OVERRIDE, i-signal-type=PRIMITIVE, init-value=0, base-type=BT_HFS_TIG_betaetigt_oeffnen, compu {0=Cx0_nicht_betaetigt (CM_HFS_TIG_betaetigt_oeffnen_Cx0_nicht_betaetigt), 1=Cx1_betaetigt (CM_HFS_TIG_betaetigt_oeffnen_Cx1_betaetigt)}, range raw 0..1, transfer-property=TRIGGERED-ON-CHANGE-WITHOUT-REPETITION  # Türinnenbetätigung, Taster Tür öffnen.
          signal HFS_Vorraste_betaetigt_XIX_TSG_HFS_01_XIX_E3V_K2CANFD: start 62, 1 bit, little-endian, data-type-policy=OVERRIDE, i-signal-type=PRIMITIVE, init-value=0, base-type=BT_HFS_Vorraste_betaetigt, compu {0=Cx0_nicht_in_Vorraste (CM_HFS_Vorraste_betaetigt_Cx0_nicht_in_Vorraste), 1=Cx1_in_Vorraste (CM_HFS_Vorraste_betaetigt_Cx1_in_Vorraste)}, range raw 0..1, transfer-property=TRIGGERED-ON-CHANGE-WITHOUT-REPETITION  # Status der Vorraste
          signal HFS_SK_betaetigt_XIX_TSG_HFS_01_XIX_E3V_K2CANFD: start 63, 1 bit, little-endian, data-type-policy=OVERRIDE, i-signal-type=PRIMITIVE, init-value=0, base-type=BT_HFS_SK_betaetigt, compu {0=Cx0_ausgehoben (CM_HFS_SK_betaetigt_Cx0_ausgehoben), 1=Cx1_eingefallen (CM_HFS_SK_betaetigt_Cx1_eingefallen)}, range raw 0..1, transfer-property=TRIGGERED-ON-CHANGE-WITHOUT-REPETITION  # Status der Sperrklinke
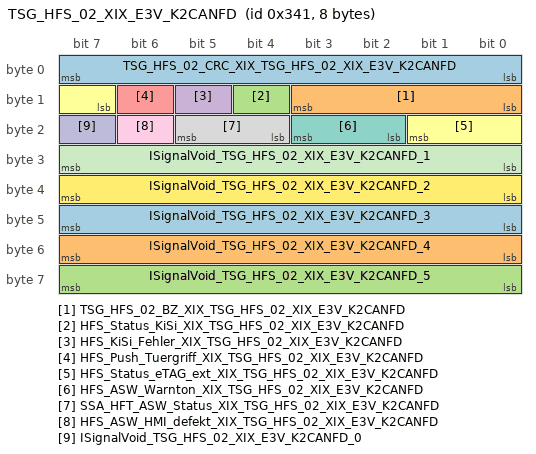
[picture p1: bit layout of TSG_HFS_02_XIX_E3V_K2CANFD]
      frame TSG_HFS_02_XIX_E3V_K2CANFD: id 0x341, from SAM, frame-length=8, can-addressing-mode=STANDARD, can-frame-rx-behavior=CAN-FD, can-frame-tx-behavior=CAN-FD
        pdu TSG_HFS_02_XIX_E3V_K2CANFD_E2E: length=8, minimum-delay=0.02, transmission-mode-true-timing=event-controlled-timing={number-of-repetitions=0, repetition-period=0.0}, unused-bit-pattern=0  # Fuer die Botschaft ist das Cyclic-Timing 0.1 zu verwenden.
          signal TSG_HFS_02_CRC_XIX_TSG_HFS_02_XIX_E3V_K2CANFD: start 0, 8 bit, little-endian, data-type-policy=OVERRIDE, i-signal-type=PRIMITIVE, base-type=BT_TSG_HFS_02_CRC, compu {phys=raw for raw 0..255}, range phys 0..255, raw 0..255  # Für MLB: Berechnung siehe Lastenheft "Kommunikationsabsicherung für FlexRay und CAN" Ab MQB und MLBevo: Berechnung siehe Lastenheft "End-to-End Kommunikationsabsicherung" Endwerte siehe Begleitdokument "S-PDU Kennungsfolgen"
          signal TSG_HFS_02_BZ_XIX_TSG_HFS_02_XIX_E3V_K2CANFD: start 8, 4 bit, little-endian, data-type-policy=OVERRIDE, i-signal-type=PRIMITIVE, base-type=BT_TSG_HFS_02_BZ, compu {phys=raw for raw 0..15}, range phys 0..15, raw 0..15  # 4bit Botschaftszähler, wird mit jeder Sendebotschaft inkrementiert
          signal HFS_Status_KiSi_XIX_TSG_HFS_02_XIX_E3V_K2CANFD: start 12, 1 bit, little-endian, data-type-policy=OVERRIDE, i-signal-type=PRIMITIVE, init-value=0, base-type=BT_HFS_Status_KiSi, compu {0=Cx0_inaktiv (CM_HFS_Status_KiSi_Cx0_inaktiv), 1=Cx1_aktiv (CM_HFS_Status_KiSi_Cx1_aktiv)}, range raw 0..1  # Status Kindersicherung hinten Fahrerseite
          signal HFS_KiSi_Fehler_XIX_TSG_HFS_02_XIX_E3V_K2CANFD: start 13, 1 bit, little-endian, data-type-policy=OVERRIDE, i-signal-type=PRIMITIVE, init-value=0, base-type=BT_HFS_KiSi_Fehler, compu {0=Cx0_kein_Fehler (CM_HFS_KiSi_Fehler_Cx0_kein_Fehler), 1=Cx1_Fehler_liegt_an (CM_HFS_KiSi_Fehler_Cx1_Fehler_liegt_an)}, range raw 0..1  # Status der Kindersicherung unplausibel
          signal HFS_Push_Tuergriff_XIX_TSG_HFS_02_XIX_E3V_K2CANFD: start 14, 1 bit, little-endian, data-type-policy=OVERRIDE, i-signal-type=PRIMITIVE, init-value=0, base-type=BT_HFS_Push_Tuergriff, compu {0=Cx0_nicht_erkannt (CM_HFS_Push_Tuergriff_Cx0_nicht_erkannt), 1=Cx1_erkannt (CM_HFS_Push_Tuergriff_Cx1_erkannt)}, range raw 0..1  # Push zum Ausfahren der Flush-Tuergriffe
          signal HFS_Status_eTAG_ext_XIX_TSG_HFS_02_XIX_E3V_K2CANFD: start 15, 3 bit, little-endian, data-type-policy=OVERRIDE, i-signal-type=PRIMITIVE, init-value=3, base-type=BT_HFS_Status_eTAG_ext, invalid-value=Invalid_HFS_Status_eTAG_ext_XIX_TSG_HFS_02_XIX_E3V_K2CANFD:4, compu {0=Cx0_Griff_eingefahren (CM_HFS_Status_eTAG_ext_Cx0_Griff_eingefahren), 1=Cx1_Griff_ausgefahren (CM_HFS_Status_eTAG_ext_Cx1_Griff_ausgefahren), 2=Cx2_Griff_verfaehrt (CM_HFS_Status_eTAG_ext_Cx2_Griff_verfaehrt), 3=Cx3_init (CM_HFS_Status_eTAG_ext_Cx3_init), 4=Cx4_Fehler (CM_HFS_Status_eTAG_ext_Cx4_Fehler)}, range raw 0..4  # HFS Status eTAG erweitert um den Wert "Griff verfaehrt"
          signal HFS_ASW_Warnton_XIX_TSG_HFS_02_XIX_E3V_K2CANFD: start 18, 2 bit, little-endian, data-type-policy=OVERRIDE, i-signal-type=PRIMITIVE, init-value=0, base-type=BT_HFS_ASW_Warnton, invalid-value=Invalid_HFS_ASW_Warnton_XIX_TSG_HFS_02_XIX_E3V_K2CANFD:3, compu {0=Cx0_kein_warnton (CM_HFS_ASW_Warnton_Cx0_kein_warnton), 1=Cx1_warnton_links (CM_HFS_ASW_Warnton_Cx1_warnton_links), 2=Cx2_warnton_rechts (CM_HFS_ASW_Warnton_Cx2_warnton_rechts), 3=Cx3_Fehler (CM_HFS_ASW_Warnton_Cx3_Fehler)}, range raw 0..3  # erzeugt ein Warnton bei AS Warnung
          signal SSA_HFT_ASW_Status_XIX_TSG_HFS_02_XIX_E3V_K2CANFD: start 20, 2 bit, little-endian, data-type-policy=OVERRIDE, i-signal-type=PRIMITIVE, init-value=0, base-type=BT_SSA_HFT_ASW_Status, compu {0=Cx0_Init (CM_SSA_HFT_ASW_Status_Cx0_Init), 1=Cx1_InfoStufe_aktiv (CM_SSA_HFT_ASW_Status_Cx1_InfoStufe_aktiv), 2=Cx2_Warnstufe_aktiv (CM_SSA_HFT_ASW_Status_Cx2_Warnstufe_aktiv)}, range raw 0..2  # SmartSensorActor: Rückmeldung des Status der ASW Anzyeige.
          signal HFS_ASW_HMI_defekt_XIX_TSG_HFS_02_XIX_E3V_K2CANFD: start 22, 1 bit, little-endian, data-type-policy=OVERRIDE, i-signal-type=PRIMITIVE, init-value=0, base-type=BT_HFS_ASW_HMI_defekt, compu {0=Cx0_ASW_kein_Fehler (CM_HFS_ASW_HMI_defekt_Cx0_ASW_kein_Fehler), 1=Cx1_ASW_Fehler (CM_HFS_ASW_HMI_defekt_Cx1_ASW_Fehler)}, range raw 0..1  # HMI Status der Funktion AusstiegsWarnung (ASW), HMI wird durch das TSG angesteuert.
          signal ISignalVoid_TSG_HFS_02_XIX_E3V_K2CANFD_0: start 23, 1 bit, little-endian, system signal SignalVoid_TSG_HFS_02_0, data-type-policy=OVERRIDE, i-signal-type=PRIMITIVE, base-type=BT_SignalVoid
          signal ISignalVoid_TSG_HFS_02_XIX_E3V_K2CANFD_1: start 24, 8 bit, little-endian, system signal SignalVoid_TSG_HFS_02_1, data-type-policy=OVERRIDE, i-signal-type=PRIMITIVE, base-type=BT_SignalVoid
          signal ISignalVoid_TSG_HFS_02_XIX_E3V_K2CANFD_2: start 32, 8 bit, little-endian, system signal SignalVoid_TSG_HFS_02_2, data-type-policy=OVERRIDE, i-signal-type=PRIMITIVE, base-type=BT_SignalVoid
          signal ISignalVoid_TSG_HFS_02_XIX_E3V_K2CANFD_3: start 40, 8 bit, little-endian, system signal SignalVoid_TSG_HFS_02_3, data-type-policy=OVERRIDE, i-signal-type=PRIMITIVE, base-type=BT_SignalVoid
          signal ISignalVoid_TSG_HFS_02_XIX_E3V_K2CANFD_4: start 48, 8 bit, little-endian, system signal SignalVoid_TSG_HFS_02_4, data-type-policy=OVERRIDE, i-signal-type=PRIMITIVE, base-type=BT_SignalVoid
          signal ISignalVoid_TSG_HFS_02_XIX_E3V_K2CANFD_5: start 56, 8 bit, little-endian, system signal SignalVoid_TSG_HFS_02_5, data-type-policy=OVERRIDE, i-signal-type=PRIMITIVE, base-type=BT_SignalVoid
          mapping SG_TSG_HFS_02_XIX_E3V_K2CANFD: i-signal-group=SG_TSG_HFS_02_XIX_E3V_K2CANFD, transfer-property=TRIGGERED-WITHOUT-REPETITION
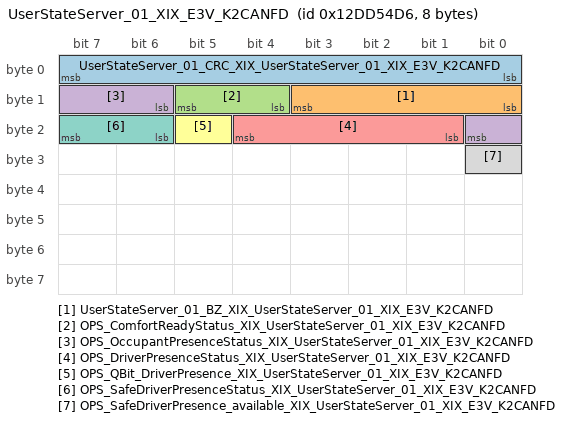
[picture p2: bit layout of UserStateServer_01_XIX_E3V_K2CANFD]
      frame UserStateServer_01_XIX_E3V_K2CANFD: id 0x12DD54D6, to SAM, frame-length=8, can-addressing-mode=EXTENDED, can-frame-rx-behavior=CAN-FD, can-frame-tx-behavior=CAN-FD
        pdu UserStateServer_01_XIX_E3V_K2CANFD: length=8, minimum-delay=0.01, transmission-mode-true-timing={cyclic-timing={time-offset=0.0, time-period=0.1}, event-controlled-timing={number-of-repetitions=5, repetition-period=0.01}}, unused-bit-pattern=0
          signal UserStateServer_01_CRC_XIX_UserStateServer_01_XIX_E3V_K2CANFD: start 0, 8 bit, little-endian, data-type-policy=OVERRIDE, i-signal-type=PRIMITIVE, base-type=BT_UserStateServer_01_CRC, compu {phys=raw for raw 0..255}, range phys 0..255, raw 0..255, transfer-property=PENDING  # Für MLB: Berechnung siehe Lastenheft "Kommunikationsabsicherung für FlexRay und CAN" Ab MQB und MLBevo: Berechnung siehe Lastenheft "End-to-End Kommunikationsabsicherung" Endwerte siehe Begleitdokument "S-PDU Kennungsfolgen"
          signal UserStateServer_01_BZ_XIX_UserStateServer_01_XIX_E3V_K2CANFD: start 8, 4 bit, little-endian, data-type-policy=OVERRIDE, i-signal-type=PRIMITIVE, base-type=BT_UserStateServer_01_BZ, compu {phys=raw for raw 0..15}, range phys 0..15, raw 0..15, transfer-property=PENDING  # 4bit Botschaftszähler, wird mit jeder Sendebotschaft inkrementiert
          signal OPS_ComfortReadyStatus_XIX_UserStateServer_01_XIX_E3V_K2CANFD: start 12, 2 bit, little-endian, data-type-policy=OVERRIDE, i-signal-type=PRIMITIVE, init-value=0, base-type=BT_OPS_ComfortReadyStatus, invalid-value=Invalid_OPS_ComfortReadyStatus_XIX_UserStateServer_01_XIX_E3V_K2CANFD:3, compu {0=Cx0_Init (CM_OPS_ComfortReadyStatus_Cx0_Init), 1=Cx1_aktiv (CM_OPS_ComfortReadyStatus_Cx1_aktiv), 2=Cx2_inaktiv (CM_OPS_ComfortReadyStatus_Cx2_inaktiv), 3=Cx3_Fehler (CM_OPS_ComfortReadyStatus_Cx3_Fehler)}, range raw 0..3, transfer-property=TRIGGERED-ON-CHANGE, to SAM(timeout 1 s)  # Das Signal wird durch den Basisdienst User State Server (Technikvariante: OccupantPresenceService) erzeugt und bildet einen neuen Zustand, bestehend aus einer Verknüpfung der Fahreranwesenheit (Fahrer abwesend / Fahrer anwesend) und der Klemmensteuerung (Klemme15/KlemmeS).Wird u.a. für das neue MEB Einstiegs-/Ausstiegskonzept verwendet.
          signal OPS_OccupantPresenceStatus_XIX_UserStateServer_01_XIX_E3V_K2CANFD: start 14, 3 bit, little-endian, data-type-policy=OVERRIDE, i-signal-type=PRIMITIVE, init-value=0, base-type=BT_OPS_OccupantPresenceStatus, invalid-value=Invalid_OPS_OccupantPresenceStatus_XIX_UserStateServer_01_XIX_E3V_K2CANFD:7, compu {0=Cx0_Init (CM_OPS_OccupantPresenceStatus_Cx0_Init), 1=Cx1_OccupantAbsent (CM_OPS_OccupantPresenceStatus_Cx1_OccupantAbsent), 2=Cx2_reserviert (CM_OPS_OccupantPresenceStatus_Cx2_reserviert), 3=Cx3_OccupantEntryExit (CM_OPS_OccupantPresenceStatus_Cx3_OccupantEntryExit), 4=Cx4_reserviert (CM_OPS_OccupantPresenceStatus_Cx4_reserviert), 5=Cx5_OccupantPresent (CM_OPS_OccupantPresenceStatus_Cx5_OccupantPresent), 6=Cx6_OccupantPresentVerified (CM_OPS_OccupantPresenceStatus_Cx6_OccupantPresentVerified), 7=Cx7_Fehler (CM_OPS_OccupantPresenceStatus_Cx7_Fehler)}, range raw 0..7, transfer-property=TRIGGERED-ON-CHANGE  # Das Signal wird durch den Basisdienst User State Server (Service: OccupantPresenceService) erzeugt und bildet die Anwesenheit und Abwesenheit aller Insassen im Fahrzeug ab.
          signal OPS_DriverPresenceStatus_XIX_UserStateServer_01_XIX_E3V_K2CANFD: start 17, 4 bit, little-endian, data-type-policy=OVERRIDE, i-signal-type=PRIMITIVE, init-value=0, base-type=BT_OPS_DriverPresenceStatus, invalid-value=Invalid_OPS_DriverPresenceStatus_XIX_UserStateServer_01_XIX_E3V_K2CANFD:15, compu {0=Cx0_Init (CM_OPS_DriverPresenceStatus_Cx0_Init), 1=Cx1_reserviert (CM_OPS_DriverPresenceStatus_Cx1_reserviert), 2=Cx2_DriverAbsent (CM_OPS_DriverPresenceStatus_Cx2_DriverAbsent), 3=Cx3_reserviert (CM_OPS_DriverPresenceStatus_Cx3_reserviert), 4=Cx4_DriverEntry (CM_OPS_DriverPresenceStatus_Cx4_DriverEntry), 5=Cx5_reserviert (CM_OPS_DriverPresenceStatus_Cx5_reserviert), 6=Cx6_DriverPresent (CM_OPS_DriverPresenceStatus_Cx6_DriverPresent), 7=Cx7_reserviert (CM_OPS_DriverPresenceStatus_Cx7_reserviert), 8=Cx8_DriverPresentVerified (CM_OPS_DriverPresenceStatus_Cx8_DriverPresentVerified), 9=Cx9_reserviert (CM_OPS_DriverPresenceStatus_Cx9_reserviert), 10=Cxa_reserviert (CM_OPS_DriverPresenceStatus_Cxa_reserviert), 11=Cxb_DriverExitIntent (CM_OPS_DriverPresenceStatus_Cxb_DriverExitIntent), 12=Cxc_reserviert (CM_OPS_DriverPresenceStatus_Cxc_reserviert), 13=Cxd_DriverExit (CM_OPS_DriverPresenceStatus_Cxd_DriverExit), 14=Cxe_reserviert (CM_OPS_DriverPresenceStatus_Cxe_reserviert), 15=Cxf_Fehler (CM_OPS_DriverPresenceStatus_Cxf_Fehler)}, range raw 0..15, transfer-property=TRIGGERED-ON-CHANGE, to SAM(timeout 1 s)  # Das Signal wird durch den Basisdienst User State Server (Service: OccupantPresenceService) erzeugt und bildet die Fahrerzustände im Fahrzeug ab.
          signal OPS_QBit_DriverPresence_XIX_UserStateServer_01_XIX_E3V_K2CANFD: start 21, 1 bit, little-endian, data-type-policy=OVERRIDE, i-signal-type=PRIMITIVE, init-value=1, base-type=BT_OPS_QBit_DriverPresence, compu {0=Cx0_gueltiger_Wert (CM_OPS_QBit_DriverPresence_Cx0_gueltiger_Wert), 1=Cx1_Ersatz_Init_oder_Fehlerwert (CM_OPS_QBit_DriverPresence_Cx1_Ersatz_Init_oder_Fehlerwert)}, range raw 0..1, transfer-property=TRIGGERED-ON-CHANGE  # Das Signal wird durch den Basisdienst User State Server (Service: OccupantPresenceService) erzeugt und signalisiert die Qualität der Fahrerzustände.
          signal OPS_SafeDriverPresenceStatus_XIX_UserStateServer_01_XIX_E3V_K2CANFD: start 22, 2 bit, little-endian, data-type-policy=OVERRIDE, i-signal-type=PRIMITIVE, init-value=0, base-type=BT_OPS_SafeDriverPresenceStatus, invalid-value=Invalid_OPS_SafeDriverPresenceStatus_XIX_UserStateServer_01_XIX_E3V_K2CANFD:3, compu {0=Cx0_Init (CM_OPS_SafeDriverPresenceStatus_Cx0_Init), 1=Cx1_Driver_Safe_Present (CM_OPS_SafeDriverPresenceStatus_Cx1_Driver_Safe_Present), 2=Cx2_Driver_Not_Safe_Present (CM_OPS_SafeDriverPresenceStatus_Cx2_Driver_Not_Safe_Present), 3=Cx3_Fehler (CM_OPS_SafeDriverPresenceStatus_Cx3_Fehler)}, range raw 0..3, transfer-property=TRIGGERED-ON-CHANGE  # Signalisierung einer sicheren Fahreranwesenheit nach ASIL B
          signal OPS_SafeDriverPresence_available_XIX_UserStateServer_01_XIX_E3V_K2CANFD: start 24, 1 bit, little-endian, data-type-policy=OVERRIDE, i-signal-type=PRIMITIVE, init-value=0, base-type=BT_OPS_SafeDriverPresence_available, compu {0=Cx0_Verfuegbar (CM_OPS_SafeDriverPresence_available_Cx0_Verfuegbar), 1=Cx1_Verfuegbar_eingeschr_Performance (CM_OPS_SafeDriverPresence_available_Cx1_Verfuegbar_eingeschr_Performance)}, range raw 0..1, transfer-property=TRIGGERED-ON-CHANGE  # Das Signal signalisiert inwiefern alle vorgesehene Sensoren für die Anwesenheit verwendet werden oder möglichweise bestimmte Sensoren nicht verfügbar sind. In beiden Fällen wird eine Anwesenheit berechnet, jedoch bei Ausfall bestimmter Sensoren kann zu bestimmten Einschränkungen führen. Das Signal wird funktional und ohne ASIL Güte bedient.
      frame VIN_01_XIX_E3V_K2CANFD: id 0x6B4, to SAM, frame-length=8, can-addressing-mode=STANDARD, can-frame-rx-behavior=CAN-FD, can-frame-tx-behavior=CAN-FD
        multiplexed i pdu VIN_01_XIX_E3V_K2CANFD:
          length=8
          dynamic-part{segment-position{segment-byte-order=little-endian, segment-length=64, segment-position=0}, dynamic-part-alternatives=[{i-pdu=VIN_01_Mx00_XIX_E3V_K2CANFD, initial-dynamic-part=true, selector-field-code=0}, {i-pdu=VIN_01_Mx01_XIX_E3V_K2CANFD, initial-dynamic-part=false, selector-field-code=1}, {i-pdu=VIN_01_Mx02_XIX_E3V_K2CANFD, initial-dynamic-part=false, selector-field-code=2}]}
          selector-field-byte-order=little-endian
          selector-field-length=2
          selector-field-start-position=0
          trigger-mode=DYNAMIC-PART-TRIGGER
          unused-bit-pattern=0
      frame VMM_02_Auth_XIX_E3V_K2CANFD: id 0x139, to SAM, frame-length=32, can-addressing-mode=STANDARD, can-frame-rx-behavior=CAN-FD, can-frame-tx-behavior=CAN-FD
        pdu VMM_02_Auth_XIX_E3V_K2CANFD_E2E: length=28, transmission-mode-true-timing=event-controlled-timing={number-of-repetitions=0, repetition-period=0.0}, unused-bit-pattern=0  # Fuer die Botschaft ist das Cyclic-Timing 0.1 zu verwenden.
          signal VMM_02_CRC_XIX_VMM_02_Auth_XIX_E3V_K2CANFD: start 0, 8 bit, little-endian, data-type-policy=OVERRIDE, i-signal-type=PRIMITIVE, base-type=BT_VMM_02_CRC, compu {phys=raw for raw 0..255}, range phys 0..255, raw 0..255, to SAM(timeout 1 s)  # Für MLB: Berechnung siehe Lastenheft "Kommunikationsabsicherung für FlexRay und CAN" Ab MQB und MLBevo: Berechnung siehe Lastenheft "End-to-End Kommunikationsabsicherung" Endwerte siehe Begleitdokument "S-PDU Kennungsfolgen"
          signal VMM_02_BZ_XIX_VMM_02_Auth_XIX_E3V_K2CANFD: start 8, 4 bit, little-endian, data-type-policy=OVERRIDE, i-signal-type=PRIMITIVE, base-type=BT_VMM_02_BZ, compu {phys=raw for raw 0..15}, range phys 0..15, raw 0..15, to SAM(timeout 1 s)  # 4bit Botschaftszähler, wird mit jeder Sendebotschaft inkrementiert
          signal VZM_aktiver_Basisservice_XIX_VMM_02_Auth_XIX_E3V_K2CANFD: start 12, 3 bit, little-endian, data-type-policy=OVERRIDE, i-signal-type=PRIMITIVE, init-value=0, base-type=BT_VZM_aktiver_Basisservice, compu {0=Cx0_Keine_Aktivitaet (CM_VZM_aktiver_Basisservice_Cx0_Keine_Aktivitaet), 1=Cx1_Bremsenkonditionierung (CM_VZM_aktiver_Basisservice_Cx1_Bremsenkonditionierung), 2=Cx2_Bremsruck (CM_VZM_aktiver_Basisservice_Cx2_Bremsruck), 3=Cx3_Verzoegerungsregelung (CM_VZM_aktiver_Basisservice_Cx3_Verzoegerungsregelung), 4=Cx4_Wegregelung (CM_VZM_aktiver_Basisservice_Cx4_Wegregelung)}, range raw 0..4  # In diesem Signal wird der aktive Basisservice des Verzögerungsmanagement zurück gegeben.
          signal VZM_Anhalteweg_nicht_verfuegbar_XIX_VMM_02_Auth_XIX_E3V_K2CANFD: start 15, 1 bit, little-endian, data-type-policy=OVERRIDE, i-signal-type=PRIMITIVE, init-value=0, base-type=BT_VZM_Anhalteweg_nicht_verfuegbar, compu {0=Cx0_verfuegbar (CM_VZM_Anhalteweg_nicht_verfuegbar_Cx0_verfuegbar), 1=Cx1_nicht_verfuegbar (CM_VZM_Anhalteweg_nicht_verfuegbar_Cx1_nicht_verfuegbar)}, range raw 0..1  # Rückmeldung ob die Anhaltewegregelung verfügbar ist.
          signal VZM_Fahrer_bremst_XIX_VMM_02_Auth_XIX_E3V_K2CANFD: start 16, 1 bit, little-endian, data-type-policy=OVERRIDE, i-signal-type=PRIMITIVE, init-value=0, base-type=BT_VZM_Fahrer_bremst, compu {0=Cx0_Bremsdruckschwelle_nicht_ueberschritten (CM_VZM_Fahrer_bremst_Cx0_Bremsdruckschwelle_nicht_ueberschritten), 1=Cx1_Bremsdruckschwelle_ueberschritten (CM_VZM_Fahrer_bremst_Cx1_Bremsdruckschwelle_ueberschritten)}, range raw 0..1  # Bit wird gesetzt beim Überschreiten der Bremsdruckschwelle Weiterführende Informationen im Lastenheft spezifiziert und in der entsprechenden Fachabteilung zu erfragen.
          signal VZM_QBit_Fahrer_bremst_XIX_VMM_02_Auth_XIX_E3V_K2CANFD: start 17, 1 bit, little-endian, data-type-policy=OVERRIDE, i-signal-type=PRIMITIVE, init-value=1, base-type=BT_VZM_QBit_Fahrer_bremst, compu {0=Cx0_gueltiger_Wert (CM_VZM_QBit_Fahrer_bremst_Cx0_gueltiger_Wert), 1=Cx1_Ersatz_Init_oder_Fehlerwert (CM_VZM_QBit_Fahrer_bremst_Cx1_Ersatz_Init_oder_Fehlerwert)}, range raw 0..1  # Gültigkeit der Bremsdruckschwelleninformation des Signals VZM_Fahrer_bremst und VZM_Fahrer_bremst_deutlich 0x1 = Druckschwelleninformation kann noch nicht oder aufgrund eines Fehlers nicht ausgegeben werden
          signal VMM_MKB_codiert_XIX_VMM_02_Auth_XIX_E3V_K2CANFD: start 18, 1 bit, little-endian, data-type-policy=OVERRIDE, i-signal-type=PRIMITIVE, init-value=0, base-type=BT_VMM_MKB_codiert, compu {0=Cx0_MKB_nicht_codiert (CM_VMM_MKB_codiert_Cx0_MKB_nicht_codiert), 1=Cx1_MKB_codiert (CM_VMM_MKB_codiert_Cx1_MKB_codiert)}, range raw 0..1  # Das Signal kennzeichnet den Codierstatus des ESC-SG bzgl. der Funktion Multikollisionsbremse.
          signal VMM_Inkonsistenz_EBKV_XIX_VMM_02_Auth_XIX_E3V_K2CANFD: start 19, 1 bit, little-endian, data-type-policy=OVERRIDE, i-signal-type=PRIMITIVE, init-value=0, base-type=BT_VMM_Inkonsistenz_EBKV, compu {0=Cx0_konsistent (CM_VMM_Inkonsistenz_EBKV_Cx0_konsistent), 1=Cx1_nicht_konsistent (CM_VMM_Inkonsistenz_EBKV_Cx1_nicht_konsistent)}, range raw 0..1  # Rückmeldung Inkonsistenz EBKV
          signal VMM_Notstopp_Status_XIX_VMM_02_Auth_XIX_E3V_K2CANFD: start 20, 3 bit, little-endian, data-type-policy=OVERRIDE, i-signal-type=PRIMITIVE, init-value=0, base-type=BT_VMM_Notstopp_Status, invalid-value=Invalid_VMM_Notstopp_Status_XIX_VMM_02_Auth_XIX_E3V_K2CANFD:7, compu {0=Cx0_Init (CM_VMM_Notstopp_Status_Cx0_Init), 1=Cx1_verfuegbar (CM_VMM_Notstopp_Status_Cx1_verfuegbar), 2=Cx2_warten_auf_sekundaer_System (CM_VMM_Notstopp_Status_Cx2_warten_auf_sekundaer_System), 3=Cx3_passiv_Ueberwachung (CM_VMM_Notstopp_Status_Cx3_passiv_Ueberwachung), 4=Cx4_aktiv_ausgeloest (CM_VMM_Notstopp_Status_Cx4_aktiv_ausgeloest), 7=Cx7_Fehler (CM_VMM_Notstopp_Status_Cx7_Fehler)}, range raw 0..7  # Status des Notstoppsystems
          signal VZM_Warnruck_nicht_verfuegbar_XIX_VMM_02_Auth_XIX_E3V_K2CANFD: start 23, 1 bit, little-endian, data-type-policy=OVERRIDE, i-signal-type=PRIMITIVE, init-value=0, base-type=BT_VZM_Warnruck_nicht_verfuegbar, compu {0=Cx0_verfuegbar (CM_VZM_Warnruck_nicht_verfuegbar_Cx0_verfuegbar), 1=Cx1_nicht_verfuegbar (CM_VZM_Warnruck_nicht_verfuegbar_Cx1_nicht_verfuegbar)}, range raw 0..1  # Rückmeldung ob ein einfacher Warnruck angefordert werden kann.
          signal VZM_Warnruckeln_nicht_verfuegbar_XIX_VMM_02_Auth_XIX_E3V_K2CANFD: start 24, 1 bit, little-endian, data-type-policy=OVERRIDE, i-signal-type=PRIMITIVE, init-value=0, base-type=BT_VZM_Warnruckeln_nicht_verfuegbar, compu {0=Cx0_verfuegbar (CM_VZM_Warnruckeln_nicht_verfuegbar_Cx0_verfuegbar), 1=Cx1_nicht_verfuegbar (CM_VZM_Warnruckeln_nicht_verfuegbar_Cx1_nicht_verfuegbar)}, range raw 0..1  # Rückmeldung ob mehrfach ein Warnruck durchgeführt werden kann.
          signal VZM_Bkd_nicht_verfuegbar_XIX_VMM_02_Auth_XIX_E3V_K2CANFD: start 25, 1 bit, little-endian, data-type-policy=OVERRIDE, i-signal-type=PRIMITIVE, init-value=0, base-type=BT_VZM_Bkd_nicht_verfuegbar, compu {0=Cx0_verfuegbar (CM_VZM_Bkd_nicht_verfuegbar_Cx0_verfuegbar), 1=Cx1_nicht_verfuegbar (CM_VZM_Bkd_nicht_verfuegbar_Cx1_nicht_verfuegbar)}, range raw 0..1  # Dieses Signal gibt eine Rückmeldung ob eine Bremsenkonditionierung (Prefill und Systemtotzeitminimierung) verfügbar ist.
          signal VMM_Bremslicht_defekt_XIX_VMM_02_Auth_XIX_E3V_K2CANFD: start 26, 1 bit, little-endian, data-type-policy=OVERRIDE, i-signal-type=PRIMITIVE, init-value=0, base-type=BT_VMM_Bremslicht_defekt, compu {0=Cx0_Bremslichter_nicht_defekt (CM_VMM_Bremslicht_defekt_Cx0_Bremslichter_nicht_defekt), 1=Cx1_Bremslichter_defekt (CM_VMM_Bremslicht_defekt_Cx1_Bremslichter_defekt)}, range raw 0..1  # Rückmeldung ob beide Bremslichter defekt sind. Bei gestecktem Anhänger werden die Anhängerbremslichter ausgewertet.
          signal VZM_Fahrer_bremst_deutlich_XIX_VMM_02_Auth_XIX_E3V_K2CANFD: start 27, 1 bit, little-endian, data-type-policy=OVERRIDE, i-signal-type=PRIMITIVE, init-value=0, base-type=BT_VZM_Fahrer_bremst_deutlich, compu {0=Cx0_Fahrer_bremst_nicht_deutlich (CM_VZM_Fahrer_bremst_deutlich_Cx0_Fahrer_bremst_nicht_deutlich), 1=Cx1_Fahrer_bremst_deutlich (CM_VZM_Fahrer_bremst_deutlich_Cx1_Fahrer_bremst_deutlich)}, range raw 0..1  # Rückmeldung an AWV ob der Fahrer das Bremspedal deutlich betätigt hat
          signal VZM_TSK_SRBM_Anf_XIX_VMM_02_Auth_XIX_E3V_K2CANFD: start 28, 1 bit, little-endian, data-type-policy=OVERRIDE, i-signal-type=PRIMITIVE, init-value=0, base-type=BT_VZM_TSK_SRBM_Anf, compu {0=Cx0_keine_Aktivitaet (CM_VZM_TSK_SRBM_Anf_Cx0_keine_Aktivitaet), 1=Cx1_Aktivitaet_durch_TSK (CM_VZM_TSK_SRBM_Anf_Cx1_Aktivitaet_durch_TSK)}, range raw 0..1  # Quittierung für TSK (SRBM = Summenradbremsmoment) Anforderung
          signal VZM_TSK_SRBM_nicht_verfuegbar_XIX_VMM_02_Auth_XIX_E3V_K2CANFD: start 29, 1 bit, little-endian, data-type-policy=OVERRIDE, i-signal-type=PRIMITIVE, init-value=0, base-type=BT_VZM_TSK_SRBM_nicht_verfuegbar, compu {0=Cx0_verfuegbar (CM_VZM_TSK_SRBM_nicht_verfuegbar_Cx0_verfuegbar), 1=Cx1_nicht_verfuegbar (CM_VZM_TSK_SRBM_nicht_verfuegbar_Cx1_nicht_verfuegbar)}, range raw 0..1  # Rückmeldung ob das ein Summenradbremsmoment angefordert werden kann.
          signal VZM_Verz_Reg_aktiv_XIX_VMM_02_Auth_XIX_E3V_K2CANFD: start 30, 5 bit, little-endian, data-type-policy=OVERRIDE, i-signal-type=PRIMITIVE, init-value=0, base-type=BT_VZM_Verz_Reg_aktiv, compu {0=Cx0_keine_Aktivitaet (CM_VZM_Verz_Reg_aktiv_Cx0_keine_Aktivitaet), 2=Cx2_Aktivitaet_durch_AWV_PCF (CM_VZM_Verz_Reg_aktiv_Cx2_Aktivitaet_durch_AWV_PCF), 3=Cx3_Aktivitaet_durch_EA (CM_VZM_Verz_Reg_aktiv_Cx3_Aktivitaet_durch_EA), 4=Cx4_Aktivitaet_durch_TSK (CM_VZM_Verz_Reg_aktiv_Cx4_Aktivitaet_durch_TSK), 5=Cx5_Aktivitaet_durch_RCTA (CM_VZM_Verz_Reg_aktiv_Cx5_Aktivitaet_durch_RCTA), 6=Cx6_Aktivitaet_durch_ParkAssist (CM_VZM_Verz_Reg_aktiv_Cx6_Aktivitaet_durch_ParkAssist), 7=Cx7_Aktivitaet_durch_ACC (CM_VZM_Verz_Reg_aktiv_Cx7_Aktivitaet_durch_ACC), 8=Cx8_Aktivitaet_durch_ARA (CM_VZM_Verz_Reg_aktiv_Cx8_Aktivitaet_durch_ARA), 9=Cx9_Aktivitaet_durch_NV (CM_VZM_Verz_Reg_aktiv_Cx9_Aktivitaet_durch_NV), 10=Cxa_Aktivitaet_durch_KAS (CM_VZM_Verz_Reg_aktiv_Cxa_Aktivitaet_durch_KAS), 11=Cxb_Aktivitaet_durch_FAS_VK (CM_VZM_Verz_Reg_aktiv_Cxb_Aktivitaet_durch_FAS_VK), 12=Cxc_Aktivitaet_durch_vESC (CM_VZM_Verz_Reg_aktiv_Cxc_Aktivitaet_durch_vESC), 13=Cxd_Aktivitaet_durch_KAM (CM_VZM_Verz_Reg_aktiv_Cxd_Aktivitaet_durch_KAM), 14=Cxe_Aktivitaet_durch_BRS_intern (CM_VZM_Verz_Reg_aktiv_Cxe_Aktivitaet_durch_BRS_intern), 15=Cxf_Aktivitaet_durch_AEB (CM_VZM_Verz_Reg_aktiv_Cxf_Aktivitaet_durch_AEB), 16=Cx10_Aktivitaet_durch_MKB (CM_VZM_Verz_Reg_aktiv_Cx10_Aktivitaet_durch_MKB)}, range raw 0..16  # Rueckmeldung Verzoegerungsregelung aktiv
          signal VZM_Verz_Reg_nicht_verfuegbar_XIX_VMM_02_Auth_XIX_E3V_K2CANFD: start 35, 1 bit, little-endian, data-type-policy=OVERRIDE, i-signal-type=PRIMITIVE, init-value=0, base-type=BT_VZM_Verz_Reg_nicht_verfuegbar, compu {0=Cx0_verfuegbar (CM_VZM_Verz_Reg_nicht_verfuegbar_Cx0_verfuegbar), 1=Cx1_nicht_verfuegbar (CM_VZM_Verz_Reg_nicht_verfuegbar_Cx1_nicht_verfuegbar)}, range raw 0..1  # In diesem Signal wird ausgegeben ob eine Verzögerungsregelung verfügbar ist.
          signal VMM_Inkonsistenz_KAS_XIX_VMM_02_Auth_XIX_E3V_K2CANFD: start 36, 1 bit, little-endian, data-type-policy=OVERRIDE, i-signal-type=PRIMITIVE, init-value=0, base-type=BT_VMM_Inkonsistenz_KAS, compu {0=Cx0_konsistent (CM_VMM_Inkonsistenz_KAS_Cx0_konsistent), 1=Cx1_nicht_konsistent (CM_VMM_Inkonsistenz_KAS_Cx1_nicht_konsistent)}, range raw 0..1  # Rückmeldung Inkonsistenz KAS
          signal VMM_Bremslicht_unplausibel_XIX_VMM_02_Auth_XIX_E3V_K2CANFD: start 37, 1 bit, little-endian, data-type-policy=OVERRIDE, i-signal-type=PRIMITIVE, init-value=0, base-type=BT_VMM_Bremslicht_unplausibel, compu {0=Cx0_plausibel (CM_VMM_Bremslicht_unplausibel_Cx0_plausibel), 1=Cx1_unplausibel (CM_VMM_Bremslicht_unplausibel_Cx1_unplausibel)}, range raw 0..1  # Bremslichtplausibilität aus Basis der CAN Anforderung
          signal VMM_Inkonsistenz_ACC_XIX_VMM_02_Auth_XIX_E3V_K2CANFD: start 38, 1 bit, little-endian, data-type-policy=OVERRIDE, i-signal-type=PRIMITIVE, init-value=0, base-type=BT_VMM_Inkonsistenz_ACC, compu {0=Cx0_konsistent (CM_VMM_Inkonsistenz_ACC_Cx0_konsistent), 1=Cx1_nicht_konsistent (CM_VMM_Inkonsistenz_ACC_Cx1_nicht_konsistent)}, range raw 0..1  # Rückmeldung Inkonsistenz ACC
          signal VMM_Inkonsistenz_AWV_PCF_XIX_VMM_02_Auth_XIX_E3V_K2CANFD: start 39, 1 bit, little-endian, data-type-policy=OVERRIDE, i-signal-type=PRIMITIVE, init-value=0, base-type=BT_VMM_Inkonsistenz_AWV_PCF, compu {0=Cx0_konsistent (CM_VMM_Inkonsistenz_AWV_PCF_Cx0_konsistent), 1=Cx1_nicht_konsistent (CM_VMM_Inkonsistenz_AWV_PCF_Cx1_nicht_konsistent)}, range raw 0..1  # Rückmeldung Inkonsistenz AWV PCF
          signal VMM_Inkonsistenz_ARA_XIX_VMM_02_Auth_XIX_E3V_K2CANFD: start 40, 1 bit, little-endian, data-type-policy=OVERRIDE, i-signal-type=PRIMITIVE, init-value=0, base-type=BT_VMM_Inkonsistenz_ARA, compu {0=Cx0_konsistent (CM_VMM_Inkonsistenz_ARA_Cx0_konsistent), 1=Cx1_nicht_konsistent (CM_VMM_Inkonsistenz_ARA_Cx1_nicht_konsistent)}, range raw 0..1  # Rückmeldung Inkonsistenz ARA 1.0
          signal VMM_Inkonsistenz_ParkAssist_XIX_VMM_02_Auth_XIX_E3V_K2CANFD: start 41, 1 bit, little-endian, data-type-policy=OVERRIDE, i-signal-type=PRIMITIVE, init-value=0, base-type=BT_VMM_Inkonsistenz_ParkAssist, compu {0=Cx0_konsistent (CM_VMM_Inkonsistenz_ParkAssist_Cx0_konsistent), 1=Cx1_nicht_konsistent (CM_VMM_Inkonsistenz_ParkAssist_Cx1_nicht_konsistent)}, range raw 0..1  # Rückmeldung Inkonsistenz der Parkenden Systeme
          signal VMM_Inkonsistenz_FAS_VK_XIX_VMM_02_Auth_XIX_E3V_K2CANFD: start 42, 1 bit, little-endian, data-type-policy=OVERRIDE, i-signal-type=PRIMITIVE, init-value=0, base-type=BT_VMM_Inkonsistenz_FAS_VK, compu {0=Cx0_konsistent (CM_VMM_Inkonsistenz_FAS_VK_Cx0_konsistent), 1=Cx1_nicht_konsistent (CM_VMM_Inkonsistenz_FAS_VK_Cx1_nicht_konsistent)}, range raw 0..1  # Rückmeldung Inkonsistenz Fahrerassistenzsystem
          signal VMM_Inkonsistenz_NV_XIX_VMM_02_Auth_XIX_E3V_K2CANFD: start 43, 1 bit, little-endian, data-type-policy=OVERRIDE, i-signal-type=PRIMITIVE, init-value=0, base-type=BT_VMM_Inkonsistenz_NV, compu {0=Cx0_konsistent (CM_VMM_Inkonsistenz_NV_Cx0_konsistent), 1=Cx1_nicht_konsistent (CM_VMM_Inkonsistenz_NV_Cx1_nicht_konsistent)}, range raw 0..1  # Rückmeldung Inkonsistenz Nightvision
          signal VMM_Inkonsistenz_RCTA_XIX_VMM_02_Auth_XIX_E3V_K2CANFD: start 44, 1 bit, little-endian, data-type-policy=OVERRIDE, i-signal-type=PRIMITIVE, init-value=0, base-type=BT_VMM_Inkonsistenz_RCTA, compu {0=Cx0_konsistent (CM_VMM_Inkonsistenz_RCTA_Cx0_konsistent), 1=Cx1_nicht_konsistent (CM_VMM_Inkonsistenz_RCTA_Cx1_nicht_konsistent)}, range raw 0..1  # Rückmeldung Inkonsistenz des RCTA
          signal VMM_Inkonsistenz_TSK_XIX_VMM_02_Auth_XIX_E3V_K2CANFD: start 45, 1 bit, little-endian, data-type-policy=OVERRIDE, i-signal-type=PRIMITIVE, init-value=0, base-type=BT_VMM_Inkonsistenz_TSK, compu {0=Cx0_konsistent (CM_VMM_Inkonsistenz_TSK_Cx0_konsistent), 1=Cx1_nicht_konsistent (CM_VMM_Inkonsistenz_TSK_Cx1_nicht_konsistent)}, range raw 0..1  # Rückmeldung Inkonsistenz TSK
          signal VMM_Inkonsistenz_MO_XIX_VMM_02_Auth_XIX_E3V_K2CANFD: start 46, 1 bit, little-endian, data-type-policy=OVERRIDE, i-signal-type=PRIMITIVE, init-value=0, base-type=BT_VMM_Inkonsistenz_MO, compu {0=Cx0_konsistent (CM_VMM_Inkonsistenz_MO_Cx0_konsistent), 1=Cx1_nicht_konsistent (CM_VMM_Inkonsistenz_MO_Cx1_nicht_konsistent)}, range raw 0..1  # Rückmeldung Inkonsistenz MO
          signal VMM_Inkonsistenz_AEB_XIX_VMM_02_Auth_XIX_E3V_K2CANFD: start 47, 1 bit, little-endian, data-type-policy=OVERRIDE, i-signal-type=PRIMITIVE, init-value=0, base-type=BT_VMM_Inkonsistenz_AEB, compu {0=Cx0_konsistent (CM_VMM_Inkonsistenz_AEB_Cx0_konsistent), 1=Cx1_nicht_konsistent (CM_VMM_Inkonsistenz_AEB_Cx1_nicht_konsistent)}, range raw 0..1  # Rückmeldung Inkonsistenz vom AEB
          signal VMM_Fahrer_Bremskraft_bestimmend_XIX_VMM_02_Auth_XIX_E3V_K2CANFD: start 48, 1 bit, little-endian, data-type-policy=OVERRIDE, i-signal-type=PRIMITIVE, init-value=0, base-type=BT_VMM_Fahrer_Bremskraft_bestimmend, compu {0=Cx0_Nicht_Bremskraft_bestimmend (CM_VMM_Fahrer_Bremskraft_bestimmend_Cx0_Nicht_Bremskraft_bestimmend), 1=Cx1_Bremskraft_bestimmend (CM_VMM_Fahrer_Bremskraft_bestimmend_Cx1_Bremskraft_bestimmend)}, range raw 0..1  # Dieses Signal gibt eine Rückmeldung ob der Fahrer stärker bremst als die angeforderte Bremsung.
          signal VMM_Inkonsistenz_EA_XIX_VMM_02_Auth_XIX_E3V_K2CANFD: start 49, 1 bit, little-endian, data-type-policy=OVERRIDE, i-signal-type=PRIMITIVE, init-value=0, base-type=BT_VMM_Inkonsistenz_EA, compu {0=Cx0_konsistent (CM_VMM_Inkonsistenz_EA_Cx0_konsistent), 1=Cx1_nicht_konsistent (CM_VMM_Inkonsistenz_EA_Cx1_nicht_konsistent)}, range raw 0..1  # Rückmeldung Inkonsistenz EA
          signal VZM_Status_Wegregelung_XIX_VMM_02_Auth_XIX_E3V_K2CANFD: start 50, 2 bit, little-endian, data-type-policy=OVERRIDE, i-signal-type=PRIMITIVE, init-value=0, base-type=BT_VZM_Status_Wegregelung, compu {0=Cx0_Inaktiv (CM_VZM_Status_Wegregelung_Cx0_Inaktiv), 1=Cx1_Passiv (CM_VZM_Status_Wegregelung_Cx1_Passiv), 2=Cx2_Aktiv (CM_VZM_Status_Wegregelung_Cx2_Aktiv), 3=Cx3_Passiv_Ueberwachend (CM_VZM_Status_Wegregelung_Cx3_Passiv_Ueberwachend)}, range raw 0..3  # Rückmeldung der Wegregelung ob dieser Service Inaktiv, aktiv oder passiv ist. Bei Passiv_Überwachend Bremseingriff durch VZM im Notfall möglich.
          signal VZM_Verz_ASIL_Verfuegbarkeit_XIX_VMM_02_Auth_XIX_E3V_K2CANFD: start 52, 3 bit, little-endian, data-type-policy=OVERRIDE, i-signal-type=PRIMITIVE, init-value=0, base-type=BT_VZM_Verz_ASIL_Verfuegbarkeit, compu {0=Cx0_Nicht_verfuegbar (CM_VZM_Verz_ASIL_Verfuegbarkeit_Cx0_Nicht_verfuegbar), 1=Cx1_Verfuegbar_ab_ASIL_QM (CM_VZM_Verz_ASIL_Verfuegbarkeit_Cx1_Verfuegbar_ab_ASIL_QM), 2=Cx2_Verfuegbar_ab_ASIL_A (CM_VZM_Verz_ASIL_Verfuegbarkeit_Cx2_Verfuegbar_ab_ASIL_A), 3=Cx3_Verfuegbar_ab_ASIL_B (CM_VZM_Verz_ASIL_Verfuegbarkeit_Cx3_Verfuegbar_ab_ASIL_B), 4=Cx4_Verfuegbar_ab_ASIL_C (CM_VZM_Verz_ASIL_Verfuegbarkeit_Cx4_Verfuegbar_ab_ASIL_C)}, range raw 0..4  # Dieses Signal gibt die Rückmeldung in welchem ASIL Bereich aktuell verzögert wird.
          signal VZM_aktives_System_XIX_VMM_02_Auth_XIX_E3V_K2CANFD: start 55, 5 bit, little-endian, data-type-policy=OVERRIDE, i-signal-type=PRIMITIVE, init-value=0, base-type=BT_VZM_aktives_System, compu {0=Cx0_Kein_aktiver_Teilnehmer (CM_VZM_aktives_System_Cx0_Kein_aktiver_Teilnehmer), 1=Cx1_VZM_intern (CM_VZM_aktives_System_Cx1_VZM_intern), 2=Cx2_AWV_PCF (CM_VZM_aktives_System_Cx2_AWV_PCF), 3=Cx3_EA (CM_VZM_aktives_System_Cx3_EA), 4=Cx4_TSK (CM_VZM_aktives_System_Cx4_TSK), 5=Cx5_RCTA (CM_VZM_aktives_System_Cx5_RCTA), 6=Cx6_ParkAssist (CM_VZM_aktives_System_Cx6_ParkAssist), 7=Cx7_ACC (CM_VZM_aktives_System_Cx7_ACC), 8=Cx8_ARA (CM_VZM_aktives_System_Cx8_ARA), 9=Cx9_NV (CM_VZM_aktives_System_Cx9_NV), 10=Cxa_KAS (CM_VZM_aktives_System_Cxa_KAS), 11=Cxb_FAS_VK (CM_VZM_aktives_System_Cxb_FAS_VK), 12=Cxc_vESC (CM_VZM_aktives_System_Cxc_vESC), 13=Cxd_KAM (CM_VZM_aktives_System_Cxd_KAM), 14=Cxe_reserviert (CM_VZM_aktives_System_Cxe_reserviert), 15=Cxf_AEB (CM_VZM_aktives_System_Cxf_AEB), 16=Cx10_MKB (CM_VZM_aktives_System_Cx10_MKB), 17=Cx11_ECD (CM_VZM_aktives_System_Cx11_ECD), 18=Cx12_RHP (CM_VZM_aktives_System_Cx12_RHP)}, range raw 0..18  # Rückmeldung über das aktiv anfordernde System bei dem Verzögerungsmanagement.
          signal VZM_Verz_Begrenzung_XIX_VMM_02_Auth_XIX_E3V_K2CANFD: start 60, 1 bit, little-endian, data-type-policy=OVERRIDE, i-signal-type=PRIMITIVE, init-value=0, base-type=BT_VZM_Verz_Begrenzung, compu {0=Cx0_keine_Begrenzung (CM_VZM_Verz_Begrenzung_Cx0_keine_Begrenzung), 1=Cx1_Begrenzung_aktiv (CM_VZM_Verz_Begrenzung_Cx1_Begrenzung_aktiv)}, range raw 0..1  # Rückmeldung angeforderte Verzögerung oder Summenradbremsmoment wird begrenzt umgesetzt
          signal VZM_Systemstatus_XIX_VMM_02_Auth_XIX_E3V_K2CANFD: start 61, 3 bit, little-endian, data-type-policy=OVERRIDE, i-signal-type=PRIMITIVE, init-value=0, base-type=BT_VZM_Systemstatus, invalid-value=Invalid_VZM_Systemstatus_XIX_VMM_02_Auth_XIX_E3V_K2CANFD:4, compu {0=Cx0_Initialisierung (CM_VZM_Systemstatus_Cx0_Initialisierung), 1=Cx1_Verfuegbar (CM_VZM_Systemstatus_Cx1_Verfuegbar), 2=Cx2_Verfuegbar_eingeschr_Performance (CM_VZM_Systemstatus_Cx2_Verfuegbar_eingeschr_Performance), 3=Cx3_Nicht_Verfuegbar (CM_VZM_Systemstatus_Cx3_Nicht_Verfuegbar), 4=Cx4_Fehler (CM_VZM_Systemstatus_Cx4_Fehler), 5=Cx5_Sonderbetriebsmodus (CM_VZM_Systemstatus_Cx5_Sonderbetriebsmodus)}, range raw 0..5  # In diesem Signal wird der aktuelle Systemstatus des Verzögerungsmanagments ausgeben.
          signal VZM_SRBM_Soll_XIX_VMM_02_Auth_XIX_E3V_K2CANFD: start 64, 12 bit, little-endian, data-type-policy=OVERRIDE, i-signal-type=PRIMITIVE, init-value=4094, base-type=BT_VZM_SRBM_Soll, invalid-value=Invalid_VZM_SRBM_Soll_XIX_VMM_02_Auth_XIX_E3V_K2CANFD:4095, compu {phys=raw*8 for raw 0..4093, 4094=Cxffe_Init (CM_VZM_SRBM_Soll_Cxffe_Init), 4095=Cxfff_Fehler (CM_VZM_SRBM_Soll_Cxfff_Fehler); unit Unit_NewtoMeter}, range phys 0..32744 Unit_NewtoMeter, raw 0..4095, unit=Unit_NewtoMeter  # Gibt das angeforderte Summenradbremsmoment aus.
          signal VZM_SRBM_Ist_XIX_VMM_02_Auth_XIX_E3V_K2CANFD: start 76, 12 bit, little-endian, data-type-policy=OVERRIDE, i-signal-type=PRIMITIVE, init-value=4094, base-type=BT_VZM_SRBM_Ist, invalid-value=Invalid_VZM_SRBM_Ist_XIX_VMM_02_Auth_XIX_E3V_K2CANFD:4095, compu {phys=raw*8 for raw 0..4093, 4094=Cxffe_Init (CM_VZM_SRBM_Ist_Cxffe_Init), 4095=Cxfff_Fehler (CM_VZM_SRBM_Ist_Cxfff_Fehler); unit Unit_NewtoMeter}, range phys 0..32744 Unit_NewtoMeter, raw 0..4095, unit=Unit_NewtoMeter  # Gibt das aktuelle Summenradbremsmoment aus.
          signal VZM_SRBM_max_Gradient_XIX_VMM_02_Auth_XIX_E3V_K2CANFD: start 88, 7 bit, little-endian, data-type-policy=OVERRIDE, i-signal-type=PRIMITIVE, init-value=126, base-type=BT_VZM_SRBM_max_Gradient, invalid-value=Invalid_VZM_SRBM_max_Gradient_XIX_VMM_02_Auth_XIX_E3V_K2CANFD:127, compu {phys=raw*50 for raw 0..125, 126=Cx7e_Init (CM_VZM_SRBM_max_Gradient_Cx7e_Init), 127=Cx7f_Fehler (CM_VZM_SRBM_max_Gradient_Cx7f_Fehler); unit Unit_NewtoMeterPerSecon}, range phys 0..6250 Unit_NewtoMeterPerSecon, raw 0..127, unit=Unit_NewtoMeterPerSecon  # Rückmeldung aktueller Maximalgradient
          signal VMM_Inkonsistenz_KAM_XIX_VMM_02_Auth_XIX_E3V_K2CANFD: start 95, 1 bit, little-endian, data-type-policy=OVERRIDE, i-signal-type=PRIMITIVE, init-value=0, base-type=BT_VMM_Inkonsistenz_KAM, compu {0=Cx0_konsistent (CM_VMM_Inkonsistenz_KAM_Cx0_konsistent), 1=Cx1_nicht_konsistent (CM_VMM_Inkonsistenz_KAM_Cx1_nicht_konsistent)}, range raw 0..1  # Rückmeldung Inkonsistenz der Kamera
          signal VMM_Inkonsistenz_RHP_XIX_VMM_02_Auth_XIX_E3V_K2CANFD: start 96, 1 bit, little-endian, data-type-policy=OVERRIDE, i-signal-type=PRIMITIVE, init-value=0, base-type=BT_VMM_Inkonsistenz_RHP, compu {0=Cx0_konsistent (CM_VMM_Inkonsistenz_RHP_Cx0_konsistent), 1=Cx1_nicht_konsistent (CM_VMM_Inkonsistenz_RHP_Cx1_nicht_konsistent)}, range raw 0..1  # Rückmeldung Inkonsistenz RHP (Rush Hour pilot).
          signal VMM_Inkonsistenz_VMC_XIX_VMM_02_Auth_XIX_E3V_K2CANFD: start 97, 1 bit, little-endian, data-type-policy=OVERRIDE, i-signal-type=PRIMITIVE, init-value=0, base-type=BT_VMM_Inkonsistenz_VMC, compu {0=Cx0_konsistent (CM_VMM_Inkonsistenz_VMC_Cx0_konsistent), 1=Cx1_nicht_konsistent (CM_VMM_Inkonsistenz_VMC_Cx1_nicht_konsistent)}, range raw 0..1  # Rückmeldung Inkonsistenz VMC Prim
          signal VZM_int_Laengsverz_XIX_VMM_02_Auth_XIX_E3V_K2CANFD: start 98, 10 bit, little-endian, data-type-policy=OVERRIDE, i-signal-type=PRIMITIVE, init-value=1022, base-type=BT_VZM_int_Laengsverz, invalid-value=Invalid_VZM_int_Laengsverz_XIX_VMM_02_Auth_XIX_E3V_K2CANFD:1023, compu {phys=raw/32-16 for raw 0..1021, 1022=Cx3fe_Init (CM_VZM_int_Laengsverz_Cx3fe_Init), 1023=Cx3ff_Fehler (CM_VZM_int_Laengsverz_Cx3ff_Fehler); unit Unit_MeterPerSeconSquar}, range phys -16..15.90625 Unit_MeterPerSeconSquar, raw 0..1023, unit=Unit_MeterPerSeconSquar  # Das Signal gibt den im VZM intern verwendeten Längsverzögerungswert aus
          signal ISignalVoid_VMM_02_Auth_XIX_E3V_K2CANFD_0: start 108, 4 bit, little-endian, system signal SignalVoid_VMM_02_Auth_0, data-type-policy=OVERRIDE, i-signal-type=PRIMITIVE, base-type=BT_SignalVoid
          signal ISignalVoid_VMM_02_Auth_XIX_E3V_K2CANFD_1: start 112, 8 bit, little-endian, system signal SignalVoid_VMM_02_Auth_1, data-type-policy=OVERRIDE, i-signal-type=PRIMITIVE, base-type=BT_SignalVoid
          signal ISignalVoid_VMM_02_Auth_XIX_E3V_K2CANFD_2: start 120, 8 bit, little-endian, system signal SignalVoid_VMM_02_Auth_2, data-type-policy=OVERRIDE, i-signal-type=PRIMITIVE, base-type=BT_SignalVoid
          signal ISignalVoid_VMM_02_Auth_XIX_E3V_K2CANFD_3: start 128, 8 bit, little-endian, system signal SignalVoid_VMM_02_Auth_3, data-type-policy=OVERRIDE, i-signal-type=PRIMITIVE, base-type=BT_SignalVoid
          signal ISignalVoid_VMM_02_Auth_XIX_E3V_K2CANFD_4: start 136, 8 bit, little-endian, system signal SignalVoid_VMM_02_Auth_4, data-type-policy=OVERRIDE, i-signal-type=PRIMITIVE, base-type=BT_SignalVoid
          signal ISignalVoid_VMM_02_Auth_XIX_E3V_K2CANFD_5: start 144, 8 bit, little-endian, system signal SignalVoid_VMM_02_Auth_5, data-type-policy=OVERRIDE, i-signal-type=PRIMITIVE, base-type=BT_SignalVoid
          signal ISignalVoid_VMM_02_Auth_XIX_E3V_K2CANFD_6: start 152, 8 bit, little-endian, system signal SignalVoid_VMM_02_Auth_6, data-type-policy=OVERRIDE, i-signal-type=PRIMITIVE, base-type=BT_SignalVoid
          signal ISignalVoid_VMM_02_Auth_XIX_E3V_K2CANFD_7: start 160, 8 bit, little-endian, system signal SignalVoid_VMM_02_Auth_7, data-type-policy=OVERRIDE, i-signal-type=PRIMITIVE, base-type=BT_SignalVoid
          signal ISignalVoid_VMM_02_Auth_XIX_E3V_K2CANFD_8: start 168, 4 bit, little-endian, system signal SignalVoid_VMM_02_Auth_8, data-type-policy=OVERRIDE, i-signal-type=PRIMITIVE, base-type=BT_SignalVoid
          signal HMS_P_beibehalten_GE_XIX_VMM_02_Auth_XIX_E3V_K2CANFD: start 172, 2 bit, little-endian, data-type-policy=OVERRIDE, i-signal-type=PRIMITIVE, init-value=2, base-type=BT_HMS_P_beibehalten_GE, invalid-value=Invalid_HMS_P_beibehalten_GE_XIX_VMM_02_Auth_XIX_E3V_K2CANFD:3, compu {0=Cx0_P_nicht_beibehalten (CM_HMS_P_beibehalten_GE_Cx0_P_nicht_beibehalten), 1=Cx1_P_beibehalten (CM_HMS_P_beibehalten_GE_Cx1_P_beibehalten), 2=Cx2_Init (CM_HMS_P_beibehalten_GE_Cx2_Init), 3=Cx3_Fehler (CM_HMS_P_beibehalten_GE_Cx3_Fehler)}, range raw 0..3  # Fordert das Getriebe auf in Stellung 'P' zu bleiben.
          signal VZM_Unterdrueckung_Antriebsmom_XIX_VMM_02_Auth_XIX_E3V_K2CANFD: start 174, 1 bit, little-endian, data-type-policy=OVERRIDE, i-signal-type=PRIMITIVE, init-value=0, base-type=BT_VZM_Unterdrueckung_Antriebsmom, compu {0=Cx0_Pos_Antriebsmoment_moeglich (CM_VZM_Unterdrueckung_Antriebsmom_Cx0_Pos_Antriebsmoment_moeglich), 1=Cx1_Pos_Antriebsmoment_unterdruecken (CM_VZM_Unterdrueckung_Antriebsmom_Cx1_Pos_Antriebsmoment_unterdruecken)}, range raw 0..1  # Mit diesem Signal wird dem TSK signalisiert ob ein positives Antriebsmoment angefordert werden kann. In einer Notbremsung ist das positive Antriebsmoment zu unterdrücken.
          signal VMM_Inkonsistenz_VLK_XIX_VMM_02_Auth_XIX_E3V_K2CANFD: start 175, 1 bit, little-endian, data-type-policy=OVERRIDE, i-signal-type=PRIMITIVE, init-value=0, base-type=BT_VMM_Inkonsistenz_VLK, compu {0=Cx0_konsistent (CM_VMM_Inkonsistenz_VLK_Cx0_konsistent), 1=Cx1_nicht_konsistent (CM_VMM_Inkonsistenz_VLK_Cx1_nicht_konsistent)}, range raw 0..1  # Rückmeldung Inkonsistenz VLK
          signal HMS_halten_nicht_verfuegbar_02_XIX_VMM_02_Auth_XIX_E3V_K2CANFD: start 176, 2 bit, little-endian, data-type-policy=OVERRIDE, i-signal-type=PRIMITIVE, init-value=0, base-type=BT_HMS_halten_nicht_verfuegbar_02, compu {0=Cx0_verfuegbar (CM_HMS_halten_nicht_verfuegbar_02_Cx0_verfuegbar), 1=Cx1_nicht_verfuegbar (CM_HMS_halten_nicht_verfuegbar_02_Cx1_nicht_verfuegbar), 2=Cx2_verfuegbar_ohne_Anwesenheitserk (CM_HMS_halten_nicht_verfuegbar_02_Cx2_verfuegbar_ohne_Anwesenheitserk), 3=Cx3_reserviert (CM_HMS_halten_nicht_verfuegbar_02_Cx3_reserviert)}, range raw 0..3  # Erweiterung des Signals "HMS_halten_nicht_verfuegbar": Für Remotevorgänge (Ein-, Ausparken, etc.) ohne anwesenden Fahrer soll das Signal eine Halteverfügbarkeit signalisieren durch "verfuegbar_ohne_Fahrer".
          signal ISignalVoid_VMM_02_Auth_XIX_E3V_K2CANFD_9: start 178, 2 bit, little-endian, system signal SignalVoid_VMM_02_Auth_9, data-type-policy=OVERRIDE, i-signal-type=PRIMITIVE, base-type=BT_SignalVoid
          signal HMS_halten_nicht_verfuegbar_XIX_VMM_02_Auth_XIX_E3V_K2CANFD: start 180, 1 bit, little-endian, data-type-policy=OVERRIDE, i-signal-type=PRIMITIVE, init-value=0, base-type=BT_HMS_halten_nicht_verfuegbar, compu {0=Cx0_verfuegbar (CM_HMS_halten_nicht_verfuegbar_Cx0_verfuegbar), 1=Cx1_nicht_verfuegbar (CM_HMS_halten_nicht_verfuegbar_Cx1_nicht_verfuegbar)}, range raw 0..1  # Rueckmeldung HMS-Teilfunktion "Halten" nicht verfuegbar.
          signal ISignalVoid_VMM_02_Auth_XIX_E3V_K2CANFD_10: start 181, 3 bit, little-endian, system signal SignalVoid_VMM_02_Auth_10, data-type-policy=OVERRIDE, i-signal-type=PRIMITIVE, base-type=BT_SignalVoid
          signal ISignalVoid_VMM_02_Auth_XIX_E3V_K2CANFD_11: start 184, 8 bit, little-endian, system signal SignalVoid_VMM_02_Auth_11, data-type-policy=OVERRIDE, i-signal-type=PRIMITIVE, base-type=BT_SignalVoid
          signal HMS_parken_nicht_verfuegbar_XIX_VMM_02_Auth_XIX_E3V_K2CANFD: start 192, 1 bit, little-endian, data-type-policy=OVERRIDE, i-signal-type=PRIMITIVE, init-value=0, base-type=BT_HMS_parken_nicht_verfuegbar, compu {0=Cx0_verfuegbar (CM_HMS_parken_nicht_verfuegbar_Cx0_verfuegbar), 1=Cx1_nicht_verfuegbar (CM_HMS_parken_nicht_verfuegbar_Cx1_nicht_verfuegbar)}, range raw 0..1, to SAM(timeout 1 s)  # Rueckmeldung HMS-Teilfunktionen "Parken" nicht verfuegbar.
          signal HMS_Anforderung_GE_XIX_VMM_02_Auth_XIX_E3V_K2CANFD: start 193, 3 bit, little-endian, data-type-policy=OVERRIDE, i-signal-type=PRIMITIVE, init-value=0, base-type=BT_HMS_Anforderung_GE, compu {0=Cx0_keine_Anforderung (CM_HMS_Anforderung_GE_Cx0_keine_Anforderung), 1=Cx1_P_einlegen (CM_HMS_Anforderung_GE_Cx1_P_einlegen)}, range raw 0..1  # Fordert vom Getriebe bestimmte Schaltstellungen an.
          signal HMS_Systemstatus_XIX_VMM_02_Auth_XIX_E3V_K2CANFD: start 196, 4 bit, little-endian, data-type-policy=OVERRIDE, i-signal-type=PRIMITIVE, init-value=14, base-type=BT_HMS_Systemstatus, invalid-value=Invalid_HMS_Systemstatus_XIX_VMM_02_Auth_XIX_E3V_K2CANFD:15, compu {0=Cx0_keine_Funktion_aktiv (CM_HMS_Systemstatus_Cx0_keine_Funktion_aktiv), 1=Cx1_Halten_aktiv (CM_HMS_Systemstatus_Cx1_Halten_aktiv), 2=Cx2_Parken_angefordert (CM_HMS_Systemstatus_Cx2_Parken_angefordert), 3=Cx3_Parken_aktiv (CM_HMS_Systemstatus_Cx3_Parken_aktiv), 4=Cx4_Parken_beibehalten_aktiv (CM_HMS_Systemstatus_Cx4_Parken_beibehalten_aktiv), 5=Cx5_Anfahren_aktiv (CM_HMS_Systemstatus_Cx5_Anfahren_aktiv), 6=Cx6_Loeseanforderung_aktiv (CM_HMS_Systemstatus_Cx6_Loeseanforderung_aktiv), 7=Cx7_Loeseanforderung_durch_Fahrer (CM_HMS_Systemstatus_Cx7_Loeseanforderung_durch_Fahrer), 8=Cx8_Abrutschen_erkannt (CM_HMS_Systemstatus_Cx8_Abrutschen_erkannt), 9=Cx9_Halten_Standby_aktiv (CM_HMS_Systemstatus_Cx9_Halten_Standby_aktiv), 10=Cxa_Anfahren_Standby_aktiv (CM_HMS_Systemstatus_Cxa_Anfahren_Standby_aktiv), 14=Cxe_Init (CM_HMS_Systemstatus_Cxe_Init), 15=Cxf_Fehler (CM_HMS_Systemstatus_Cxf_Fehler)}, range raw 0..15, to SAM(timeout 1 s)  # Zeigt den aktuellen Systemstatus des HMS an.
          signal HMS_Stillstand_XIX_VMM_02_Auth_XIX_E3V_K2CANFD: start 200, 3 bit, little-endian, data-type-policy=OVERRIDE, i-signal-type=PRIMITIVE, init-value=6, base-type=BT_HMS_Stillstand, invalid-value=Invalid_HMS_Stillstand_XIX_VMM_02_Auth_XIX_E3V_K2CANFD:7, compu {0=Cx0_kein_Stillstand (CM_HMS_Stillstand_Cx0_kein_Stillstand), 1=Cx1_Stillstand_frueh (CM_HMS_Stillstand_Cx1_Stillstand_frueh), 2=Cx2_Stillstand (CM_HMS_Stillstand_Cx2_Stillstand), 6=Cx6_Init (CM_HMS_Stillstand_Cx6_Init), 7=Cx7_Fehler (CM_HMS_Stillstand_Cx7_Fehler)}, range raw 0..7, to SAM(timeout 1 s)  # Das Signal zeigt, basierend auf den vier ESP-Raddrehzahlinformatioen, gefiltert und/oder entprellt mehrstufig den Fahrzeuggeschwindigkeitszustand an.
          signal HMS_aktives_System_XIX_VMM_02_Auth_XIX_E3V_K2CANFD: start 203, 5 bit, little-endian, data-type-policy=OVERRIDE, i-signal-type=PRIMITIVE, init-value=0, base-type=BT_HMS_aktives_System, compu {0=Cx0_kein_System_Init_Fehler (CM_HMS_aktives_System_Cx0_kein_System_Init_Fehler) (kein_System__Init_Fehler), 1=Cx1_Fahreranforderung_aktiv (CM_HMS_aktives_System_Cx1_Fahreranforderung_aktiv), 2=Cx2_HMS_intern_aktiv (CM_HMS_aktives_System_Cx2_HMS_intern_aktiv), 3=Cx3_ACC_aktiv (CM_HMS_aktives_System_Cx3_ACC_aktiv), 4=Cx4_Autohold_aktiv (CM_HMS_aktives_System_Cx4_Autohold_aktiv), 5=Cx5_HHC_aktiv (CM_HMS_aktives_System_Cx5_HHC_aktiv), 6=Cx6_HVLM_aktiv (CM_HMS_aktives_System_Cx6_HVLM_aktiv), 7=Cx7_Getriebe_aktiv (CM_HMS_aktives_System_Cx7_Getriebe_aktiv), 8=Cx8_EBKV_aktiv (CM_HMS_aktives_System_Cx8_EBKV_aktiv), 9=Cx9_ParkAssist_aktiv (CM_HMS_aktives_System_Cx9_ParkAssist_aktiv), 10=Cxa_ARA_aktiv (CM_HMS_aktives_System_Cxa_ARA_aktiv), 11=Cxb_HTO_aktiv (CM_HMS_aktives_System_Cxb_HTO_aktiv), 12=Cxc_autonomous_Hold_aktiv (CM_HMS_aktives_System_Cxc_autonomous_Hold_aktiv), 13=Cxd_STA_aktiv (CM_HMS_aktives_System_Cxd_STA_aktiv), 14=Cxe_Motor_aktiv (CM_HMS_aktives_System_Cxe_Motor_aktiv), 15=Cxf_EA_aktiv (CM_HMS_aktives_System_Cxf_EA_aktiv), 16=Cx10_VLK_aktiv (CM_HMS_aktives_System_Cx10_VLK_aktiv), 17=Cx11_RHP_aktiv (CM_HMS_aktives_System_Cx11_RHP_aktiv), 18=Cx12_ORU_aktiv (CM_HMS_aktives_System_Cx12_ORU_aktiv), 19=Cx13_VMC_prim_aktiv (CM_HMS_aktives_System_Cx13_VMC_prim_aktiv), 20=Cx14_VMC_sec_aktiv (CM_HMS_aktives_System_Cx14_VMC_sec_aktiv)}, range raw 0..20, to SAM(timeout 1 s)  # Zeigt an, von welchem System die Anforderung gerade umgesetzt wird.
          signal VMM_Inkonsistenz_GE_XIX_VMM_02_Auth_XIX_E3V_K2CANFD: start 208, 1 bit, little-endian, data-type-policy=OVERRIDE, i-signal-type=PRIMITIVE, init-value=0, base-type=BT_VMM_Inkonsistenz_GE, compu {0=Cx0_konsistent (CM_VMM_Inkonsistenz_GE_Cx0_konsistent), 1=Cx1_nicht_konsistent (CM_VMM_Inkonsistenz_GE_Cx1_nicht_konsistent)}, range raw 0..1  # Zeigt an, ob die Kommunikation und die Anforderungen plausibel sind.
          signal VMM_Inkonsistenz_HVLM_XIX_VMM_02_Auth_XIX_E3V_K2CANFD: start 209, 1 bit, little-endian, data-type-policy=OVERRIDE, i-signal-type=PRIMITIVE, init-value=0, base-type=BT_VMM_Inkonsistenz_HVLM, compu {0=Cx0_konsistent (CM_VMM_Inkonsistenz_HVLM_Cx0_konsistent), 1=Cx1_nicht_konsistent (CM_VMM_Inkonsistenz_HVLM_Cx1_nicht_konsistent)}, range raw 0..1  # Rückmeldung Inkonsistenz HVLM
          signal HMS_Fehlerstatus_XIX_VMM_02_Auth_XIX_E3V_K2CANFD: start 210, 3 bit, little-endian, data-type-policy=OVERRIDE, i-signal-type=PRIMITIVE, init-value=0, base-type=BT_HMS_Fehlerstatus, compu {0=Cx0_kein_Fehler (CM_HMS_Fehlerstatus_Cx0_kein_Fehler), 1=Cx1_Halten_nicht_moeglich (CM_HMS_Fehlerstatus_Cx1_Halten_nicht_moeglich), 2=Cx2_Sonderbetriebsmodus_aktiv (CM_HMS_Fehlerstatus_Cx2_Sonderbetriebsmodus_aktiv), 3=Cx3_Systemeinschraenkung (CM_HMS_Fehlerstatus_Cx3_Systemeinschraenkung), 4=Cx4_Systemstoerung (CM_HMS_Fehlerstatus_Cx4_Systemstoerung)}, range raw 0..4, to SAM(timeout 1 s)  # Zeigt den Fehlerstatus des Haltemanagementsystems HMS an. Details zu den Werten 3/4: 3=Systemeinschränkung, Parken EPB oder GSG nicht möglich 4=Systemstörung bzw. Parken EPB und GSG nicht möglich
          signal HMS_Index_Haltemoment_XIX_VMM_02_Auth_XIX_E3V_K2CANFD: start 213, 1 bit, little-endian, data-type-policy=OVERRIDE, i-signal-type=PRIMITIVE, init-value=0, base-type=BT_HMS_Index_Haltemoment, compu {0=Cx0_Bremsmoment (CM_HMS_Index_Haltemoment_Cx0_Bremsmoment), 1=Cx1_Antriebsmoment (CM_HMS_Index_Haltemoment_Cx1_Antriebsmoment)}, range raw 0..1  # Zeigt an, ob das Summen-HMS_Haltemoment ein Bremsmoment (bergab) oder ein Antriebsmoment (bergauf) darstellt.
          signal HMS_Haltemoment_XIX_VMM_02_Auth_XIX_E3V_K2CANFD: start 214, 10 bit, little-endian, data-type-policy=OVERRIDE, i-signal-type=PRIMITIVE, init-value=1022, base-type=BT_HMS_Haltemoment, invalid-value=Invalid_HMS_Haltemoment_XIX_VMM_02_Auth_XIX_E3V_K2CANFD:1023, compu {phys=raw*10 for raw 0..1021, 1022=Cx3fe_Init (CM_HMS_Haltemoment_Cx3fe_Init), 1023=Cx3ff_Fehler (CM_HMS_Haltemoment_Cx3ff_Fehler); unit Unit_NewtoMeter}, range phys 0..10210 Unit_NewtoMeter, raw 0..1023, unit=Unit_NewtoMeter  # Zeigt in Abhängigkeit von HMS_Index_Haltemoment das notwendige Summen-Radmoment an (bergab: Bremsmoment; bergauf: Antriebsmoment), das mindestens notwendig ist um das Fahrzeug an der aktuellen Neigung zu halten.
          mapping SG_VMM_02_Auth_XIX_E3V_K2CANFD: i-signal-group=SG_VMM_02_Auth_XIX_E3V_K2CANFD, transfer-property=TRIGGERED-WITHOUT-REPETITION
      frame WFS_01_XIX_E3V_K2CANFD: id 0x551, to SAM, frame-length=8, can-addressing-mode=STANDARD, can-frame-rx-behavior=CAN-FD, can-frame-tx-behavior=CAN-FD
        pdu WFS_01_XIX_E3V_K2CANFD: length=8, minimum-delay=0.05, transmission-mode-true-timing={cyclic-timing={time-offset=0.0, time-period=0.2}, event-controlled-timing={number-of-repetitions=0, repetition-period=0.0}}, unused-bit-pattern=0
          signal WFS_Schluessel_Fahrberecht_XIX_WFS_01_XIX_E3V_K2CANFD: start 0, 4 bit, little-endian, data-type-policy=OVERRIDE, i-signal-type=PRIMITIVE, init-value=0, base-type=BT_WFS_Schluessel_Fahrberecht, compu {0=Cx0_kein_authorisierter_Schluessel_erkannt (CM_WFS_Schluessel_Fahrberecht_Cx0_kein_authorisierter_Schluessel_erkannt) (kein authorisierter Schluessel erkannt), 1=Cx1_aktive_Funkschluessel_Nr_01 (CM_WFS_Schluessel_Fahrberecht_Cx1_aktive_Funkschluessel_Nr_01), 2=Cx2_aktive_Funkschluessel_Nr_02 (CM_WFS_Schluessel_Fahrberecht_Cx2_aktive_Funkschluessel_Nr_02), 3=Cx3_aktive_Funkschluessel_Nr_03 (CM_WFS_Schluessel_Fahrberecht_Cx3_aktive_Funkschluessel_Nr_03), 4=Cx4_aktive_Funkschluessel_Nr_04 (CM_WFS_Schluessel_Fahrberecht_Cx4_aktive_Funkschluessel_Nr_04), 5=Cx5_aktive_Funkschluessel_Nr_05 (CM_WFS_Schluessel_Fahrberecht_Cx5_aktive_Funkschluessel_Nr_05), 6=Cx6_aktive_Funkschluessel_Nr_06 (CM_WFS_Schluessel_Fahrberecht_Cx6_aktive_Funkschluessel_Nr_06), 7=Cx7_aktive_Funkschluessel_Nr_07 (CM_WFS_Schluessel_Fahrberecht_Cx7_aktive_Funkschluessel_Nr_07), 8=Cx8_aktive_Funkschluessel_Nr_08 (CM_WFS_Schluessel_Fahrberecht_Cx8_aktive_Funkschluessel_Nr_08), 9=Cx9_ungueltig_09 (CM_WFS_Schluessel_Fahrberecht_Cx9_ungueltig_09), 10=Cxa_ungueltig_10 (CM_WFS_Schluessel_Fahrberecht_Cxa_ungueltig_10), 11=Cxb_ungueltig_11 (CM_WFS_Schluessel_Fahrberecht_Cxb_ungueltig_11), 12=Cxc_ungueltig_12 (CM_WFS_Schluessel_Fahrberecht_Cxc_ungueltig_12), 13=Cxd_ungueltig_13 (CM_WFS_Schluessel_Fahrberecht_Cxd_ungueltig_13), 14=Cxe_ungueltig_14 (CM_WFS_Schluessel_Fahrberecht_Cxe_ungueltig_14), 15=Cxf_digitaler_Schluessel_aktiv (CM_WFS_Schluessel_Fahrberecht_Cxf_digitaler_Schluessel_aktiv)}, range raw 0..15, transfer-property=PENDING, to SAM(timeout 2 s)  # Schlüsselnummer Fahrberechtigung 0 = ungueltig, xxxx = Schluessel-Nr.
          signal WFS_Verbauinfo_ELV_XIX_WFS_01_XIX_E3V_K2CANFD: start 4, 1 bit, little-endian, data-type-policy=OVERRIDE, i-signal-type=PRIMITIVE, init-value=0, base-type=BT_WFS_Verbauinfo_ELV, compu {0=Cx0_ELV_nicht_verbaut (CM_WFS_Verbauinfo_ELV_Cx0_ELV_nicht_verbaut), 1=Cx1_ELV_verbaut (CM_WFS_Verbauinfo_ELV_Cx1_ELV_verbaut)}, range raw 0..1, transfer-property=TRIGGERED-ON-CHANGE-WITHOUT-REPETITION  # Info über die Konfiguration der ELV im WFS-Master
          signal WFS_ID_Geb_autorisiert_XIX_WFS_01_XIX_E3V_K2CANFD: start 5, 1 bit, little-endian, data-type-policy=OVERRIDE, i-signal-type=PRIMITIVE, init-value=0, base-type=BT_WFS_ID_Geb_autorisiert, compu {0=Cx0_Schluessel_nicht_authorisiert (CM_WFS_ID_Geb_autorisiert_Cx0_Schluessel_nicht_authorisiert), 1=Cx1_Schluessel_authorisiert (CM_WFS_ID_Geb_autorisiert_Cx1_Schluessel_authorisiert)}, range raw 0..1, transfer-property=TRIGGERED-ON-CHANGE-WITHOUT-REPETITION  # Authorisierung Schluessel (ID-Geber)
          signal WFS_ID_Geb_autorisiert_in_Kl15_XIX_WFS_01_XIX_E3V_K2CANFD: start 6, 1 bit, little-endian, data-type-policy=OVERRIDE, i-signal-type=PRIMITIVE, init-value=0, base-type=BT_WFS_ID_Geb_autorisiert_in_Kl15, compu {0=Cx0_nicht_authorisiert_in_Kl15 (CM_WFS_ID_Geb_autorisiert_in_Kl15_Cx0_nicht_authorisiert_in_Kl15), 1=Cx1_authorisiert_in_Kl15 (CM_WFS_ID_Geb_autorisiert_in_Kl15_Cx1_authorisiert_in_Kl15)}, range raw 0..1, transfer-property=TRIGGERED-ON-CHANGE-WITHOUT-REPETITION, to SAM(timeout 2 s)  # Authorisierung des Schlüssels im aktiven Klemme-15-Zyklus
          signal WFS_ID_Geb_steckt_XIX_WFS_01_XIX_E3V_K2CANFD: start 7, 1 bit, little-endian, data-type-policy=OVERRIDE, i-signal-type=PRIMITIVE, init-value=0, base-type=BT_WFS_ID_Geb_steckt, compu {0=Cx0_kein_Schluessel_im_Zuendschloss (CM_WFS_ID_Geb_steckt_Cx0_kein_Schluessel_im_Zuendschloss), 1=Cx1_Schluessel_steckt_im_Zuendschloss (CM_WFS_ID_Geb_steckt_Cx1_Schluessel_steckt_im_Zuendschloss) (Schluessel steckt im Zuendschloss)}, range raw 0..1, transfer-property=TRIGGERED-ON-CHANGE-WITHOUT-REPETITION  # Schluessel (ID-Geber) im Zuendschloss
          signal WFS_Schluessel_Soll_XIX_WFS_01_XIX_E3V_K2CANFD: start 8, 4 bit, little-endian, data-type-policy=OVERRIDE, i-signal-type=PRIMITIVE, init-value=0, base-type=BT_WFS_Schluessel_Soll, compu {phys=raw for raw 0..8; unit Unit_None}, range phys 0..8 Unit_None, raw 0..8, unit=Unit_None, transfer-property=TRIGGERED-ON-CHANGE-WITHOUT-REPETITION  # Sollwert der zu lernenden Schluessel
          signal WFS_Schluessel_Ist_XIX_WFS_01_XIX_E3V_K2CANFD: start 12, 4 bit, little-endian, data-type-policy=OVERRIDE, i-signal-type=PRIMITIVE, init-value=0, base-type=BT_WFS_Schluessel_Ist, compu {phys=raw for raw 0..8; unit Unit_None}, range phys 0..8 Unit_None, raw 0..8, unit=Unit_None, transfer-property=TRIGGERED-ON-CHANGE-WITHOUT-REPETITION  # Istwert der gelernten Schluessel
          signal WFS_Safe_XIX_WFS_01_XIX_E3V_K2CANFD: start 16, 1 bit, little-endian, data-type-policy=OVERRIDE, i-signal-type=PRIMITIVE, init-value=0, base-type=BT_WFS_Safe, compu {0=Cx0_Init (CM_WFS_Safe_Cx0_Init), 1=Cx1_WFS_nicht_deaktiviert (CM_WFS_Safe_Cx1_WFS_nicht_deaktiviert) (WFS nicht deaktiviert)}, range raw 0..1, transfer-property=TRIGGERED-ON-CHANGE-WITHOUT-REPETITION  # Status WFS
          signal WFS_LZ_XIX_WFS_01_XIX_E3V_K2CANFD: start 17, 2 bit, little-endian, data-type-policy=OVERRIDE, i-signal-type=PRIMITIVE, init-value=0, base-type=BT_WFS_LZ, compu {0=Cx0_nicht_def (CM_WFS_LZ_Cx0_nicht_def) (nicht def.), 1=Cx1_LZ_1 (CM_WFS_LZ_Cx1_LZ_1) (LZ 1), 2=Cx2_LZ_2 (CM_WFS_LZ_Cx2_LZ_2) (LZ 2), 3=Cx3_LZ_3 (CM_WFS_LZ_Cx3_LZ_3) (LZ 3)}, range raw 0..3, transfer-property=TRIGGERED-ON-CHANGE-WITHOUT-REPETITION  # Anforderung aus Lastenheft WFS V
          signal WFS_ELV_authorisiert_XIX_WFS_01_XIX_E3V_K2CANFD: start 19, 1 bit, little-endian, data-type-policy=OVERRIDE, i-signal-type=PRIMITIVE, init-value=0, base-type=BT_WFS_ELV_authorisiert, compu {0=Cx0_ELV_nicht_authorisiert (CM_WFS_ELV_authorisiert_Cx0_ELV_nicht_authorisiert), 1=Cx1_ELV_authorisiert (CM_WFS_ELV_authorisiert_Cx1_ELV_authorisiert)}, range raw 0..1, transfer-property=TRIGGERED-ON-CHANGE-WITHOUT-REPETITION  # Authorisierung der elektrischen Lenkungsverriegelung an der WFS
          signal WFS_LF_Aktiv_XIX_WFS_01_XIX_E3V_K2CANFD: start 20, 1 bit, little-endian, data-type-policy=OVERRIDE, i-signal-type=PRIMITIVE, init-value=0, base-type=BT_WFS_LF_Aktiv, compu {0=Cx0_Funktempfang_nicht_aktiv (CM_WFS_LF_Aktiv_Cx0_Funktempfang_nicht_aktiv), 1=Cx1_LF_Funkempfang_aktiv (CM_WFS_LF_Aktiv_Cx1_LF_Funkempfang_aktiv)}, range raw 0..1, transfer-property=TRIGGERED-ON-CHANGE-WITHOUT-REPETITION  # LF Schluesselkommunikation
          signal WFS_Betrieb_Lesespule_XIX_WFS_01_XIX_E3V_K2CANFD: start 21, 1 bit, little-endian, data-type-policy=OVERRIDE, i-signal-type=PRIMITIVE, init-value=0, base-type=BT_WFS_Betrieb_Lesespule, compu {0=Cx0_keine_Schluesselkomm_Lesespule (CM_WFS_Betrieb_Lesespule_Cx0_keine_Schluesselkomm_Lesespule), 1=Cx1_Schluesselkomm_Lesespule (CM_WFS_Betrieb_Lesespule_Cx1_Schluesselkomm_Lesespule)}, range raw 0..1, transfer-property=TRIGGERED-ON-CHANGE-WITHOUT-REPETITION  # Schlüsselkommunikation über die Lesespule
          signal WFS_Klemmenfreigabe_XIX_WFS_01_XIX_E3V_K2CANFD: start 22, 1 bit, little-endian, data-type-policy=OVERRIDE, i-signal-type=PRIMITIVE, init-value=0, base-type=BT_WFS_Klemmenfreigabe, compu {0=Cx0_keine_Freigabe (CM_WFS_Klemmenfreigabe_Cx0_keine_Freigabe), 1=Cx1_Freigabe (CM_WFS_Klemmenfreigabe_Cx1_Freigabe)}, range raw 0..1, transfer-property=TRIGGERED-ON-CHANGE-WITHOUT-REPETITION  # Freigabe von der WFS zum Einschalten der Klemme 15 und Klemme S
          signal WFS_Klemmenfreigabe_Signatur_XIX_WFS_01_XIX_E3V_K2CANFD: start 23, 11 bit, little-endian, data-type-policy=OVERRIDE, i-signal-type=PRIMITIVE, init-value=0, base-type=BT_WFS_Klemmenfreigabe_Signatur, compu {phys=raw for raw 0..2047}, range phys 0..2047, raw 0..2047, transfer-property=TRIGGERED-ON-CHANGE-WITHOUT-REPETITION  # Signatur zur Klemmenfreigabe durch die WFS
          signal WFS_Fahrerhinweise_XIX_WFS_01_XIX_E3V_K2CANFD: start 34, 2 bit, little-endian, data-type-policy=OVERRIDE, i-signal-type=PRIMITIVE, init-value=0, base-type=BT_WFS_Fahrerhinweise, compu {0=Cx0_Keine_Anzeigeanforderung (CM_WFS_Fahrerhinweise_Cx0_Keine_Anzeigeanforderung), 1=Cx1_Schuessel_Auth_niO (CM_WFS_Fahrerhinweise_Cx1_Schuessel_Auth_niO), 2=Cx2_Notlauf_aktiv (CM_WFS_Fahrerhinweise_Cx2_Notlauf_aktiv), 3=Cx3_Schluessel_Kessy_nicht_gefunden (CM_WFS_Fahrerhinweise_Cx3_Schluessel_Kessy_nicht_gefunden)}, range raw 0..3, transfer-property=TRIGGERED-ON-CHANGE-WITHOUT-REPETITION  # Meldungen, Fahrer- und Warnhinweise der Wegfahrsperre
          signal WFS_Parken_Status_XIX_WFS_01_XIX_E3V_K2CANFD: start 36, 2 bit, little-endian, data-type-policy=OVERRIDE, i-signal-type=PRIMITIVE, init-value=0, base-type=BT_WFS_Parken_Status, compu {0=Cx0_Limitierung_inaktiv (CM_WFS_Parken_Status_Cx0_Limitierung_inaktiv), 1=Cx1_Limitierung_aktiv (CM_WFS_Parken_Status_Cx1_Limitierung_aktiv), 2=Cx2_Abbruch (CM_WFS_Parken_Status_Cx2_Abbruch)}, range raw 0..2, transfer-property=TRIGGERED-ON-CHANGE-WITHOUT-REPETITION  # Schnittstelle zwischen WFS und ZFAS für das Pilotierte Parken um in Richtung ZFAS den Status der WFS im BCM2 zu kommunizieren
          signal WFS_LZ_02_XIX_WFS_01_XIX_E3V_K2CANFD: start 38, 4 bit, little-endian, data-type-policy=OVERRIDE, i-signal-type=PRIMITIVE, init-value=0, base-type=BT_WFS_LZ_02, invalid-value=Invalid_WFS_LZ_02_XIX_WFS_01_XIX_E3V_K2CANFD:9, compu {0=Cx0_Lieferant_Init (CM_WFS_LZ_02_Cx0_Lieferant_Init) (Lieferant/Init), 1=Cx1_fabrikneu (CM_WFS_LZ_02_Cx1_fabrikneu), 2=Cx2_angelernt (CM_WFS_LZ_02_Cx2_angelernt), 3=Cx3_Schluessel_lernen_Kundendienst (CM_WFS_LZ_02_Cx3_Schluessel_lernen_Kundendienst), 4=Cx4_Schluessel_lernen_Produktion (CM_WFS_LZ_02_Cx4_Schluessel_lernen_Produktion), 8=Cx8_WFS_temporaer_nicht_verfuegbar (CM_WFS_LZ_02_Cx8_WFS_temporaer_nicht_verfuegbar), 9=Cx9_Fehler (CM_WFS_LZ_02_Cx9_Fehler)}, range raw 0..9, transfer-property=TRIGGERED-ON-CHANGE-WITHOUT-REPETITION  # Inbetriebnahme/Anlernzustand der Wegfahrsperre
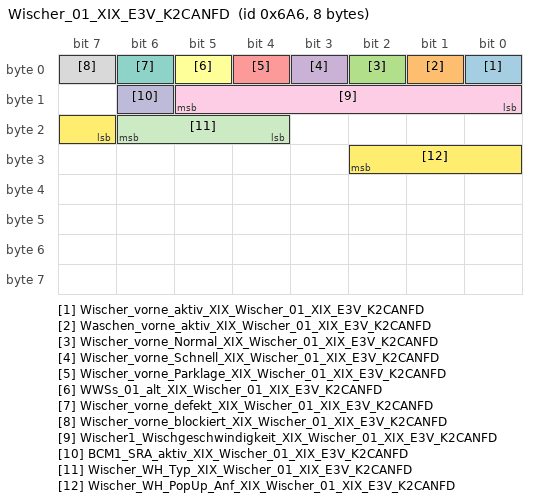
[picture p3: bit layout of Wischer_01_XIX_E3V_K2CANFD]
      frame Wischer_01_XIX_E3V_K2CANFD: id 0x6A6, from SAM, frame-length=8, can-addressing-mode=STANDARD, can-frame-rx-behavior=CAN-FD, can-frame-tx-behavior=CAN-FD
        pdu Wischer_01_XIX_E3V_K2CANFD: length=8, minimum-delay=0.05, transmission-mode-true-timing={cyclic-timing={time-offset=0.0, time-period=1.0}, event-controlled-timing={number-of-repetitions=0, repetition-period=0.0}}, unused-bit-pattern=0  # MLBevo
          signal Wischer_vorne_aktiv_XIX_Wischer_01_XIX_E3V_K2CANFD: start 0, 1 bit, little-endian, data-type-policy=OVERRIDE, i-signal-type=PRIMITIVE, init-value=0, base-type=BT_Wischer_vorne_aktiv, compu {0=Cx0_Init (CM_Wischer_vorne_aktiv_Cx0_Init), 1=Cx1_Wischer_vorne_laeuft (CM_Wischer_vorne_aktiv_Cx1_Wischer_vorne_laeuft)}, range raw 0..1, transfer-property=TRIGGERED-ON-CHANGE-WITHOUT-REPETITION  # Status: Wischer vorne
          signal Waschen_vorne_aktiv_XIX_Wischer_01_XIX_E3V_K2CANFD: start 1, 1 bit, little-endian, data-type-policy=OVERRIDE, i-signal-type=PRIMITIVE, init-value=0, base-type=BT_Waschen_vorne_aktiv, compu {0=Cx0_inaktiv (CM_Waschen_vorne_aktiv_Cx0_inaktiv), 1=Cx1_Waschen_aktiv (CM_Waschen_vorne_aktiv_Cx1_Waschen_aktiv)}, range raw 0..1, transfer-property=TRIGGERED-ON-CHANGE-WITHOUT-REPETITION  # Status: Waschen vorne aktiv
          signal Wischer_vorne_Normal_XIX_Wischer_01_XIX_E3V_K2CANFD: start 2, 1 bit, little-endian, data-type-policy=OVERRIDE, i-signal-type=PRIMITIVE, init-value=0, base-type=BT_Wischer_vorne_Normal, compu {1=Cx1_Wischer_Front_normal_aktiv (CM_Wischer_vorne_Normal_Cx1_Wischer_Front_normal_aktiv) (Wischer Front normal aktiv)}, range raw 1, transfer-property=TRIGGERED-ON-CHANGE-WITHOUT-REPETITION  # Wischer Front normal aktiv
          signal Wischer_vorne_Schnell_XIX_Wischer_01_XIX_E3V_K2CANFD: start 3, 1 bit, little-endian, data-type-policy=OVERRIDE, i-signal-type=PRIMITIVE, init-value=0, base-type=BT_Wischer_vorne_Schnell, compu {1=Cx1_Wischer_vorne_schnell_aktiv (CM_Wischer_vorne_Schnell_Cx1_Wischer_vorne_schnell_aktiv) (Wischer vorne schnell aktiv)}, range raw 1, transfer-property=TRIGGERED-ON-CHANGE-WITHOUT-REPETITION  # Wischer vorne schnell aktiv
          signal Wischer_vorne_Parklage_XIX_Wischer_01_XIX_E3V_K2CANFD: start 4, 1 bit, little-endian, data-type-policy=OVERRIDE, i-signal-type=PRIMITIVE, init-value=1, base-type=BT_Wischer_vorne_Parklage, compu {0=Cx0_Wischer_Front_nicht_in_Parklage (CM_Wischer_vorne_Parklage_Cx0_Wischer_Front_nicht_in_Parklage), 1=Cx1_Wischer_Front_in_Parklage_Initialzustand (CM_Wischer_vorne_Parklage_Cx1_Wischer_Front_in_Parklage_Initialzustand) (Wischer_Front_in_Parklage__Initialzustand)}, range raw 0..1, transfer-property=TRIGGERED-ON-CHANGE-WITHOUT-REPETITION  # Wischer Front in Parklage
          signal WWSs_01_alt_XIX_Wischer_01_XIX_E3V_K2CANFD: start 5, 1 bit, little-endian, data-type-policy=OVERRIDE, i-signal-type=PRIMITIVE, init-value=1, base-type=BT_WWSs_01_alt, compu {0=Cx0_aktuell (CM_WWSs_01_alt_Cx0_aktuell), 1=Cx1_veraltet (CM_WWSs_01_alt_Cx1_veraltet)}, range raw 0..1, transfer-property=PENDING  # Veraltet Bit für die LIN-Botschaft WWSs_01. Betroffene Signale: Wischer_vorne_aktiv
          signal Wischer_vorne_defekt_XIX_Wischer_01_XIX_E3V_K2CANFD: start 6, 1 bit, little-endian, data-type-policy=OVERRIDE, i-signal-type=PRIMITIVE, init-value=0, base-type=BT_Wischer_vorne_defekt, compu {0=Cx0_Init (CM_Wischer_vorne_defekt_Cx0_Init), 1=Cx1_Wischer_vorne_defekt (CM_Wischer_vorne_defekt_Cx1_Wischer_vorne_defekt) (Wischer vorne defekt)}, range raw 0..1, transfer-property=TRIGGERED-ON-CHANGE-WITHOUT-REPETITION  # Fehlerstatus Wischer vorne (Anzeige im Kombi)
          signal Wischer_vorne_blockiert_XIX_Wischer_01_XIX_E3V_K2CANFD: start 7, 1 bit, little-endian, data-type-policy=OVERRIDE, i-signal-type=PRIMITIVE, init-value=0, base-type=BT_Wischer_vorne_blockiert, compu {1=Cx1_Wischer_vorne_blockiert (CM_Wischer_vorne_blockiert_Cx1_Wischer_vorne_blockiert) (Wischer vorne blockiert)}, range raw 1, transfer-property=TRIGGERED-ON-CHANGE-WITHOUT-REPETITION  # Blockade Wischer vorne (z.B. durch Schnee)
          signal Wischer1_Wischgeschwindigkeit_XIX_Wischer_01_XIX_E3V_K2CANFD: start 8, 6 bit, little-endian, data-type-policy=OVERRIDE, i-signal-type=PRIMITIVE, init-value=62, base-type=BT_Wischer1_Wischgeschwindigkeit, invalid-value=Invalid_Wischer1_Wischgeschwindigkeit_XIX_Wischer_01_XIX_E3V_K2CANFD:63, compu {0=Cx0_0_U_min (CM_Wischer1_Wischgeschwindigkeit_Cx0_0_U_min) (0 U/min), phys=raw+9 for raw 1..61, 62=Cx3e_Init (CM_Wischer1_Wischgeschwindigkeit_Cx3e_Init), 63=Cx3f_Fehler (CM_Wischer1_Wischgeschwindigkeit_Cx3f_Fehler); unit Unit_MinutInver}, range phys 10..70 Unit_MinutInver, raw 0..63, unit=Unit_MinutInver, transfer-property=PENDING  # aktuelle, durch Sensorik gemessene Wischgeschwindigkeit
          signal BCM1_SRA_aktiv_XIX_Wischer_01_XIX_E3V_K2CANFD: start 14, 1 bit, little-endian, data-type-policy=OVERRIDE, i-signal-type=PRIMITIVE, init-value=0, base-type=BT_BCM1_SRA_aktiv, compu {0=Cx0_nicht_aktiv (CM_BCM1_SRA_aktiv_Cx0_nicht_aktiv) (nicht aktiv), 1=Cx1_aktiv (CM_BCM1_SRA_aktiv_Cx1_aktiv)}, range raw 0..1, transfer-property=TRIGGERED-ON-CHANGE-WITHOUT-REPETITION  # Status Scheinwerferreinigungsanlage
          signal Wischer_WH_Typ_XIX_Wischer_01_XIX_E3V_K2CANFD: start 20, 3 bit, little-endian, data-type-policy=OVERRIDE, i-signal-type=PRIMITIVE, init-value=0, base-type=BT_Wischer_WH_Typ, compu {0=Cx0_Lenkstockschalter_0_Int_Stufen (CM_Wischer_WH_Typ_Cx0_Lenkstockschalter_0_Int_Stufen), 1=Cx1_Lenkstockschalter_2_Int_Stufen (CM_Wischer_WH_Typ_Cx1_Lenkstockschalter_2_Int_Stufen), 2=Cx2_Lenkstockschalter_4_Int_Stufen (CM_Wischer_WH_Typ_Cx2_Lenkstockschalter_4_Int_Stufen)}, range raw 0..2, transfer-property=PENDING  # Signal beinhaltet Lenkstockschaltertyp für grafische Anzeige im Kombi zur Wischerfunktion
          signal Wischer_WH_PopUp_Anf_XIX_Wischer_01_XIX_E3V_K2CANFD: start 23, 4 bit, little-endian, data-type-policy=OVERRIDE, i-signal-type=PRIMITIVE, init-value=0, base-type=BT_Wischer_WH_PopUp_Anf, compu {0=Cx0_keine_Anzeige (CM_Wischer_WH_PopUp_Anf_Cx0_keine_Anzeige), 1=Cx1_Intervallstufe_1_aktiv (CM_Wischer_WH_PopUp_Anf_Cx1_Intervallstufe_1_aktiv), 2=Cx2_Intervallstufe_2_aktiv (CM_Wischer_WH_PopUp_Anf_Cx2_Intervallstufe_2_aktiv), 3=Cx3_Intervallstufe_3_aktiv (CM_Wischer_WH_PopUp_Anf_Cx3_Intervallstufe_3_aktiv), 4=Cx4_Intervallstufe_4_aktiv (CM_Wischer_WH_PopUp_Anf_Cx4_Intervallstufe_4_aktiv), 5=Cx5_Regensensorstufe_1_aktiv (CM_Wischer_WH_PopUp_Anf_Cx5_Regensensorstufe_1_aktiv), 6=Cx6_Regensensorstufe_2_aktiv (CM_Wischer_WH_PopUp_Anf_Cx6_Regensensorstufe_2_aktiv), 7=Cx7_Regensensorstufe_3_aktiv (CM_Wischer_WH_PopUp_Anf_Cx7_Regensensorstufe_3_aktiv), 8=Cx8_Regensensorstufe_4_aktiv (CM_Wischer_WH_PopUp_Anf_Cx8_Regensensorstufe_4_aktiv), 9=Cx9_Wischerstufe_1_aktiv (CM_Wischer_WH_PopUp_Anf_Cx9_Wischerstufe_1_aktiv), 10=Cxa_Wischerstufe_2_aktiv (CM_Wischer_WH_PopUp_Anf_Cxa_Wischerstufe_2_aktiv), 11=Cxb_Tippwischen_aktiv (CM_Wischer_WH_PopUp_Anf_Cxb_Tippwischen_aktiv), 12=Cxc_Heckwischen_aktiv (CM_Wischer_WH_PopUp_Anf_Cxc_Heckwischen_aktiv)}, range raw 0..12, transfer-property=TRIGGERED-ON-CHANGE-WITHOUT-REPETITION  # Anzeige von Wischerstufen im Kombi.
      frame ZFH_01_XIX_E3V_K2CANFD: id 0x185, to SAM, frame-length=8, can-addressing-mode=STANDARD, can-frame-rx-behavior=CAN-FD, can-frame-tx-behavior=CAN-FD
        pdu ZFH_01_XIX_E3V_K2CANFD: length=8, minimum-delay=0.01, transmission-mode-false-timing=event-controlled-timing={number-of-repetitions=5, repetition-period=0.04}, transmission-mode-true-timing={cyclic-timing={time-offset=0.0, time-period=0.04}, event-controlled-timing={number-of-repetitions=5, repetition-period=0.04}}, unused-bit-pattern=0  # Zentraler Fensterhebertaster ab MQB gueltig
          transmission-mode-conditions:
            {data-filter={data-filter-type=MASKED-NEW-DIFFERS-X, mask=1, x=0}, i-signal-in-i-pdu=ZFH_FS_ManHoch}
            {data-filter={data-filter-type=MASKED-NEW-DIFFERS-X, mask=1, x=0}, i-signal-in-i-pdu=ZFH_FS_AutoHoch}
            {data-filter={data-filter-type=MASKED-NEW-DIFFERS-X, mask=1, x=0}, i-signal-in-i-pdu=ZFH_FS_ManTief}
            {data-filter={data-filter-type=MASKED-NEW-DIFFERS-X, mask=1, x=0}, i-signal-in-i-pdu=ZFH_FS_AutoTief}
            {data-filter={data-filter-type=MASKED-NEW-DIFFERS-X, mask=1, x=0}, i-signal-in-i-pdu=ZFH_BFS_ManHoch}
            {data-filter={data-filter-type=MASKED-NEW-DIFFERS-X, mask=1, x=0}, i-signal-in-i-pdu=ZFH_BFS_AutoHoch}
            {data-filter={data-filter-type=MASKED-NEW-DIFFERS-X, mask=1, x=0}, i-signal-in-i-pdu=ZFH_BFS_ManTief}
            {data-filter={data-filter-type=MASKED-NEW-DIFFERS-X, mask=1, x=0}, i-signal-in-i-pdu=ZFH_BFS_AutoTief}
            {data-filter={data-filter-type=MASKED-NEW-DIFFERS-X, mask=1, x=0}, i-signal-in-i-pdu=ZFH_HFS_ManHoch}
            {data-filter={data-filter-type=MASKED-NEW-DIFFERS-X, mask=1, x=0}, i-signal-in-i-pdu=ZFH_HFS_AutoHoch}
            {data-filter={data-filter-type=MASKED-NEW-DIFFERS-X, mask=1, x=0}, i-signal-in-i-pdu=ZFH_HFS_ManTief}
            {data-filter={data-filter-type=MASKED-NEW-DIFFERS-X, mask=1, x=0}, i-signal-in-i-pdu=ZFH_HFS_AutoTief}
            {data-filter={data-filter-type=MASKED-NEW-DIFFERS-X, mask=1, x=0}, i-signal-in-i-pdu=ZFH_HBFS_ManHoch}
            {data-filter={data-filter-type=MASKED-NEW-DIFFERS-X, mask=1, x=0}, i-signal-in-i-pdu=ZFH_HBFS_AutoHoch}
            {data-filter={data-filter-type=MASKED-NEW-DIFFERS-X, mask=1, x=0}, i-signal-in-i-pdu=ZFH_HBFS_ManTief}
            {data-filter={data-filter-type=MASKED-NEW-DIFFERS-X, mask=1, x=0}, i-signal-in-i-pdu=ZFH_HBFS_AutoTief}
            {data-filter={data-filter-type=MASKED-NEW-DIFFERS-X, mask=1, x=0}, i-signal-in-i-pdu=ZFH_zentral_zu}
            {data-filter={data-filter-type=MASKED-NEW-DIFFERS-X, mask=1, x=0}, i-signal-in-i-pdu=ZFH_zentral_auf}
            {data-filter={data-filter-type=MASKED-NEW-DIFFERS-X, mask=1, x=0}, i-signal-in-i-pdu=Krypt_Schluesselschalter_auf}
            {data-filter={data-filter-type=MASKED-NEW-DIFFERS-X, mask=1, x=0}, i-signal-in-i-pdu=Krypt_Schluesselschalter_zu}
          signal ZFH_FS_ManHoch_XIX_ZFH_01_XIX_E3V_K2CANFD: start 0, 1 bit, little-endian, data-type-policy=OVERRIDE, i-signal-type=PRIMITIVE, init-value=0, base-type=BT_ZFH_FS_ManHoch, compu {0=Cx0_Keine_Verfahranforderung (CM_ZFH_FS_ManHoch_Cx0_Keine_Verfahranforderung), 1=Cx1_Manueller_Hochlauf (CM_ZFH_FS_ManHoch_Cx1_Manueller_Hochlauf)}, range raw 0..1, transfer-property=TRIGGERED-ON-CHANGE  # manueller Hochlauf des FS Fenster ausgelöst durch zentralen Fensterhebertaster
          signal ZFH_FS_AutoHoch_XIX_ZFH_01_XIX_E3V_K2CANFD: start 1, 1 bit, little-endian, data-type-policy=OVERRIDE, i-signal-type=PRIMITIVE, init-value=0, base-type=BT_ZFH_FS_AutoHoch, compu {0=Cx0_Keine_Verfahranforderung (CM_ZFH_FS_AutoHoch_Cx0_Keine_Verfahranforderung), 1=Cx1_Automatischer_Hochlauf (CM_ZFH_FS_AutoHoch_Cx1_Automatischer_Hochlauf)}, range raw 0..1, transfer-property=TRIGGERED-ON-CHANGE  # automatischer Hochlauf des FS Fenster ausgelöst durch zentralen Fensterhebertaster
          signal ZFH_FS_ManTief_XIX_ZFH_01_XIX_E3V_K2CANFD: start 2, 1 bit, little-endian, data-type-policy=OVERRIDE, i-signal-type=PRIMITIVE, init-value=0, base-type=BT_ZFH_FS_ManTief, compu {0=Cx0_Keine_Verfahranforderung (CM_ZFH_FS_ManTief_Cx0_Keine_Verfahranforderung), 1=Cx1_Manueller_Tieflauf (CM_ZFH_FS_ManTief_Cx1_Manueller_Tieflauf)}, range raw 0..1, transfer-property=TRIGGERED-ON-CHANGE  # manueller Tieflauf des FS Fenster ausgelöst durch zentralen Fensterhebertaster
          signal ZFH_FS_AutoTief_XIX_ZFH_01_XIX_E3V_K2CANFD: start 3, 1 bit, little-endian, data-type-policy=OVERRIDE, i-signal-type=PRIMITIVE, init-value=0, base-type=BT_ZFH_FS_AutoTief, compu {0=Cx0_Keine_Verfahranforderung (CM_ZFH_FS_AutoTief_Cx0_Keine_Verfahranforderung), 1=Cx1_Automatischer_Tieflauf (CM_ZFH_FS_AutoTief_Cx1_Automatischer_Tieflauf)}, range raw 0..1, transfer-property=TRIGGERED-ON-CHANGE  # automatischer Tieflauf des FS Fenster ausgelöst durch zentralen Fensterhebertaster
          signal ZFH_BFS_ManHoch_XIX_ZFH_01_XIX_E3V_K2CANFD: start 4, 1 bit, little-endian, data-type-policy=OVERRIDE, i-signal-type=PRIMITIVE, init-value=0, base-type=BT_ZFH_BFS_ManHoch, compu {0=Cx0_Keine_Verfahranforderung (CM_ZFH_BFS_ManHoch_Cx0_Keine_Verfahranforderung), 1=Cx1_Manueller_Hochlauf (CM_ZFH_BFS_ManHoch_Cx1_Manueller_Hochlauf)}, range raw 0..1, transfer-property=TRIGGERED-ON-CHANGE  # manueller Hochlauf des BFS Fenster ausgelöst durch zentralen Fensterhebertaster
          signal ZFH_BFS_AutoHoch_XIX_ZFH_01_XIX_E3V_K2CANFD: start 5, 1 bit, little-endian, data-type-policy=OVERRIDE, i-signal-type=PRIMITIVE, init-value=0, base-type=BT_ZFH_BFS_AutoHoch, compu {0=Cx0_Keine_Verfahranforderung (CM_ZFH_BFS_AutoHoch_Cx0_Keine_Verfahranforderung), 1=Cx1_Automatischer_Hochlauf (CM_ZFH_BFS_AutoHoch_Cx1_Automatischer_Hochlauf)}, range raw 0..1, transfer-property=TRIGGERED-ON-CHANGE  # automatischer Hochlauf des BFS Fenster ausgelöst durch zentralen Fensterhebertaster
          signal ZFH_BFS_ManTief_XIX_ZFH_01_XIX_E3V_K2CANFD: start 6, 1 bit, little-endian, data-type-policy=OVERRIDE, i-signal-type=PRIMITIVE, init-value=0, base-type=BT_ZFH_BFS_ManTief, compu {0=Cx0_Keine_Verfahranforderung (CM_ZFH_BFS_ManTief_Cx0_Keine_Verfahranforderung), 1=Cx1_Manueller_Tieflauf (CM_ZFH_BFS_ManTief_Cx1_Manueller_Tieflauf)}, range raw 0..1, transfer-property=TRIGGERED-ON-CHANGE  # manueller Tieflauf des BFS Fenster ausgelöst durch zentralen Fensterhebertaster
          signal ZFH_BFS_AutoTief_XIX_ZFH_01_XIX_E3V_K2CANFD: start 7, 1 bit, little-endian, data-type-policy=OVERRIDE, i-signal-type=PRIMITIVE, init-value=0, base-type=BT_ZFH_BFS_AutoTief, compu {0=Cx0_Keine_Verfahranforderung (CM_ZFH_BFS_AutoTief_Cx0_Keine_Verfahranforderung), 1=Cx1_Automatischer_Tieflauf (CM_ZFH_BFS_AutoTief_Cx1_Automatischer_Tieflauf)}, range raw 0..1, transfer-property=TRIGGERED-ON-CHANGE  # automatischer Tieflauf des BFS Fenster ausgelöst durch zentralen Fensterhebertaster
          signal ZFH_HFS_ManHoch_XIX_ZFH_01_XIX_E3V_K2CANFD: start 8, 1 bit, little-endian, data-type-policy=OVERRIDE, i-signal-type=PRIMITIVE, init-value=0, base-type=BT_ZFH_HFS_ManHoch, compu {0=Cx0_Keine_Verfahranforderung (CM_ZFH_HFS_ManHoch_Cx0_Keine_Verfahranforderung), 1=Cx1_Manueller_Hochlauf (CM_ZFH_HFS_ManHoch_Cx1_Manueller_Hochlauf)}, range raw 0..1, transfer-property=TRIGGERED-ON-CHANGE, to SAM  # manueller Hochlauf des HFS Fenster ausgelöst durch zentralen Fensterhebertaster
          signal ZFH_HFS_AutoHoch_XIX_ZFH_01_XIX_E3V_K2CANFD: start 9, 1 bit, little-endian, data-type-policy=OVERRIDE, i-signal-type=PRIMITIVE, init-value=0, base-type=BT_ZFH_HFS_AutoHoch, compu {0=Cx0_Keine_Verfahranforderung (CM_ZFH_HFS_AutoHoch_Cx0_Keine_Verfahranforderung), 1=Cx1_Automatischer_Hochlauf (CM_ZFH_HFS_AutoHoch_Cx1_Automatischer_Hochlauf)}, range raw 0..1, transfer-property=TRIGGERED-ON-CHANGE, to SAM  # automatischer Hochlauf des HFS Fenster ausgelöst durch zentralen Fensterhebertaster
          signal ZFH_HFS_ManTief_XIX_ZFH_01_XIX_E3V_K2CANFD: start 10, 1 bit, little-endian, data-type-policy=OVERRIDE, i-signal-type=PRIMITIVE, init-value=0, base-type=BT_ZFH_HFS_ManTief, compu {0=Cx0_Keine_Verfahranforderung (CM_ZFH_HFS_ManTief_Cx0_Keine_Verfahranforderung), 1=Cx1_Manueller_Tieflauf (CM_ZFH_HFS_ManTief_Cx1_Manueller_Tieflauf)}, range raw 0..1, transfer-property=TRIGGERED-ON-CHANGE, to SAM  # manueller Tieflauf des HFS Fenster ausgelöst durch zentralen Fensterhebertaster
          signal ZFH_HFS_AutoTief_XIX_ZFH_01_XIX_E3V_K2CANFD: start 11, 1 bit, little-endian, data-type-policy=OVERRIDE, i-signal-type=PRIMITIVE, init-value=0, base-type=BT_ZFH_HFS_AutoTief, compu {0=Cx0_Keine_Verfahranforderung (CM_ZFH_HFS_AutoTief_Cx0_Keine_Verfahranforderung), 1=Cx1_Automatischer_Tieflauf (CM_ZFH_HFS_AutoTief_Cx1_Automatischer_Tieflauf)}, range raw 0..1, transfer-property=TRIGGERED-ON-CHANGE, to SAM  # automatischer Tieflauf des HFS Fenster ausgelöst durch zentralen Fensterhebertaster
          signal ZFH_HBFS_ManHoch_XIX_ZFH_01_XIX_E3V_K2CANFD: start 12, 1 bit, little-endian, data-type-policy=OVERRIDE, i-signal-type=PRIMITIVE, init-value=0, base-type=BT_ZFH_HBFS_ManHoch, compu {0=Cx0_Keine_Verfahranforderung (CM_ZFH_HBFS_ManHoch_Cx0_Keine_Verfahranforderung), 1=Cx1_Manueller_Hochlauf (CM_ZFH_HBFS_ManHoch_Cx1_Manueller_Hochlauf)}, range raw 0..1, transfer-property=TRIGGERED-ON-CHANGE, to SAM  # manueller Hochlauf des HBFS Fenster ausgelöst durch zentralen Fensterhebertaster
          signal ZFH_HBFS_AutoHoch_XIX_ZFH_01_XIX_E3V_K2CANFD: start 13, 1 bit, little-endian, data-type-policy=OVERRIDE, i-signal-type=PRIMITIVE, init-value=0, base-type=BT_ZFH_HBFS_AutoHoch, compu {0=Cx0_Keine_Verfahranforderung (CM_ZFH_HBFS_AutoHoch_Cx0_Keine_Verfahranforderung), 1=Cx1_Automatischer_Hochlauf (CM_ZFH_HBFS_AutoHoch_Cx1_Automatischer_Hochlauf)}, range raw 0..1, transfer-property=TRIGGERED-ON-CHANGE, to SAM  # automatischer Hochlauf des HBFS Fenster ausgelöst durch zentralen Fensterhebertaster
          signal ZFH_HBFS_ManTief_XIX_ZFH_01_XIX_E3V_K2CANFD: start 14, 1 bit, little-endian, data-type-policy=OVERRIDE, i-signal-type=PRIMITIVE, init-value=0, base-type=BT_ZFH_HBFS_ManTief, compu {0=Cx0_Keine_Verfahranforderung (CM_ZFH_HBFS_ManTief_Cx0_Keine_Verfahranforderung), 1=Cx1_Manueller_Tieflauf (CM_ZFH_HBFS_ManTief_Cx1_Manueller_Tieflauf)}, range raw 0..1, transfer-property=TRIGGERED-ON-CHANGE, to SAM  # manueller Tieflauf des HBFS Fenster ausgelöst durch zentralen Fensterhebertaster
          signal ZFH_HBFS_AutoTief_XIX_ZFH_01_XIX_E3V_K2CANFD: start 15, 1 bit, little-endian, data-type-policy=OVERRIDE, i-signal-type=PRIMITIVE, init-value=0, base-type=BT_ZFH_HBFS_AutoTief, compu {0=Cx0_Keine_Verfahranforderung (CM_ZFH_HBFS_AutoTief_Cx0_Keine_Verfahranforderung), 1=Cx1_Automatischer_Tieflauf (CM_ZFH_HBFS_AutoTief_Cx1_Automatischer_Tieflauf)}, range raw 0..1, transfer-property=TRIGGERED-ON-CHANGE, to SAM  # automatischer Tieflauf des HBFS Fenster ausgelöst durch zentralen Fensterhebertaster
          signal ZFH_zentral_zu_XIX_ZFH_01_XIX_E3V_K2CANFD: start 28, 1 bit, little-endian, data-type-policy=OVERRIDE, i-signal-type=PRIMITIVE, init-value=0, base-type=BT_ZFH_zentral_zu, compu {0=Cx0_Init (CM_ZFH_zentral_zu_Cx0_Init), 1=Cx1_Fensterheber_zentral_zu (CM_ZFH_zentral_zu_Cx1_Fensterheber_zentral_zu)}, range raw 0..1, transfer-property=TRIGGERED-ON-CHANGE, to SAM  # Zentraler Hochlauf aller Seitenscheiben
          signal ZFH_zentral_auf_XIX_ZFH_01_XIX_E3V_K2CANFD: start 29, 1 bit, little-endian, data-type-policy=OVERRIDE, i-signal-type=PRIMITIVE, init-value=0, base-type=BT_ZFH_zentral_auf, compu {0=Cx0_Init (CM_ZFH_zentral_auf_Cx0_Init), 1=Cx1_Fensterheber_zentral_auf (CM_ZFH_zentral_auf_Cx1_Fensterheber_zentral_auf)}, range raw 0..1, transfer-property=TRIGGERED-ON-CHANGE, to SAM  # Zentraler Tieflauf aller Seitenscheiben
          signal Krypt_Signatur_XIX_ZFH_01_XIX_E3V_K2CANFD: start 48, 11 bit, little-endian, data-type-policy=OVERRIDE, i-signal-type=PRIMITIVE, init-value=0, base-type=BT_Krypt_Signatur, compu {phys=raw for raw 0..2047}, range phys 0..2047, raw 0..2047, transfer-property=TRIGGERED-ON-CHANGE  # Kryptologiesignatur
          signal Krypt_Schluesselschalter_auf_XIX_ZFH_01_XIX_E3V_K2CANFD: start 59, 1 bit, little-endian, data-type-policy=OVERRIDE, i-signal-type=PRIMITIVE, init-value=0, base-type=BT_Krypt_Schluesselschalter_auf, compu {0=Cx0_Schluesselschalter_nicht_betaetigt (CM_Krypt_Schluesselschalter_auf_Cx0_Schluesselschalter_nicht_betaetigt), 1=Cx1_Schluesselschalter_betaetigt (CM_Krypt_Schluesselschalter_auf_Cx1_Schluesselschalter_betaetigt)}, range raw 0..1, transfer-property=TRIGGERED-ON-CHANGE  # Schluesselschalter "Auf" betaetigt
          signal Krypt_Schluesselschalter_zu_XIX_ZFH_01_XIX_E3V_K2CANFD: start 60, 1 bit, little-endian, data-type-policy=OVERRIDE, i-signal-type=PRIMITIVE, init-value=0, base-type=BT_Krypt_Schluesselschalter_zu, compu {0=Cx0_Schluesselschalter_nicht_betaeti (CM_Krypt_Schluesselschalter_zu_Cx0_Schluesselschalter_nicht_betaeti), 1=Cx1_Schluesselschalter_betaetigt (CM_Krypt_Schluesselschalter_zu_Cx1_Schluesselschalter_betaetigt)}, range raw 0..1, transfer-property=TRIGGERED-ON-CHANGE  # Schluesselschalter "ZU" betaetigt
